VERSION ""

NS_ :

BS_:

BU_: Dummy_PHS EBOOST_OBD_PHS EOCM2cp_IMX6_PHS EOCM2cp_K1_PHS EPSb_PHS EBCM_PHS EPSa_PHS CMMb_PHS CGM3a_PHS CMMa_PHS ADIMb_PHS
VAL_TABLE_ vt_BooleanValues 1 "true" 0 "false" ;
VAL_TABLE_ StgOvrdDetn 3 "Disabled" 2 "False" 1 "True" 0 "Initialization" ;
VAL_TABLE_ PriADSCmdMsgStat 3 "Dual Communication Failure" 2 "Secondary Communication Failed" 1 "Main Communication Failed" 0 "Communication Normal" ;
VAL_TABLE_ PriBrkSysArbStat 7 "Supervisor Override" 6 "Automatic Brake Apply 2" 5 "Automatic Brake Apply 1" 4 "CoPilot Override Request Honored" 3 "Redundant ADS Request Honored" 2 "Main ADS Request Honored" 1 "No Autonomous Request" 0 "Unknown" ;
VAL_TABLE_ AATPCS_PropRngLmtgStat 3 "Request Rate Limited" 2 "Request Value Limited Maximum" 1 "Request Value Limited Minimum" 0 "Request Not Limited" ;
VAL_TABLE_ AATPCS_PropSysStat 6 "Degraded Mode 5" 5 "Degraded Mode 4" 4 "Degraded Mode 3" 3 "Degraded Mode 2" 2 "Degraded Mode 1" 1 "Full Function" 0 "Initialize" ;
VAL_TABLE_ AutoAxlTrqStat 3 "Serial Data Failure" 2 "Data Invalid" 1 "Data Valid" 0 "Unknown" ;
VAL_TABLE_ AutoPropAxlTrqArbStat 3 "Lost Axle Arbitration" 2 "CoPilot Active" 1 "ADS Active" 0 "No ADS data" ;
VAL_TABLE_ StrgCmndMsgStat 3 "Dual Communication Failure" 2 "Redundant Communication Failed" 1 "Primary Communication Failed" 0 "Communication Normal" ;
VAL_TABLE_ StrgCmndMsgUtlzd 1 "Redundant Controller" 0 "Primary Controller" ;
VAL_TABLE_ AutoEstBrkTrqAppStat 2 "Valid" 1 "Reduced Accuracy" 0 "Invalid" ;
VAL_TABLE_ AutoBrkSysDrInfcStat 3 "Failed" 2 "Driver Intervention Not Detected" 1 "Driver Intervention Detected" 0 "Unknown" ;
VAL_TABLE_ ActrBrkFldFlwReqStat 2 "qTarget_EBRmaxPerformance" 1 "qTarget_EBR" 0 "qTarget_Off" ;
VAL_TABLE_ EstWhlBrkPrsStat 3 "Invalid" 2 "Reduced Accuracy" 1 "Valid" 0 "Unknown" ;
VAL_TABLE_ SpltMuCntrl 2 "Split Driver Side High" 1 "Split Driver Side Low" 0 "Inactive" ;
VAL_TABLE_ PriBrkModStat 3 "Failed" 2 "Active" 1 "Available" 0 "Not Available" ;
VAL_TABLE_ ExtBrkReqStat 3 "External Brake Req Active" 2 "External Brake Req Available" 1 "External Brake Req Not Available" 0 "Unknown" ;
VAL_TABLE_ Qualifier 2 "Faulted" 1 "Normal" 0 "Unknown" ;
VAL_TABLE_ iBstStat 7 "iBooster Ready" 6 "iBooster PostRun Reduced" 5 "iBooster Reduced" 2 "iBooster Diagnosis" 1 "iBooster Failure iBoosterOff" 0 "Unknown" 3 "iBooster Autonomous Diagnosis" 4 "iBooster Standalone" ;
VAL_TABLE_ BrkRngLmtgStat 3 "Request Rate Limited" 2 "Req Value Limited Maximum" 1 "Req Value Limited Minimum" 0 "Request Not Limited" ;
VAL_TABLE_ BrkSysStat 6 "Degraded Mode 5" 5 "Degraded Mode 4" 4 "Degraded Mode 3" 3 "Degraded Mode 2" 2 "Degraded Mode 1" 1 "Full Function" 0 "Unknown" ;
VAL_TABLE_ SecBrkModSbSte 5 "Loss of Request" 4 "Full System" 3 "Failed Operational" 2 "Failed Degraded" 1 "Unable to Execute Requests" 0 "Faulted" ;
VAL_TABLE_ SecBrkModCapStat 1 "Active" 0 "Not Active" ;
VAL_TABLE_ EstSrfcMuTyp 3 "Invalid" 2 "Actual Surface Estimate" 1 "Minimum Surface Estimate" 0 "Unknown" ;
VAL_TABLE_ SecBrkModStat 3 "Failed" 2 "Active" 1 "Available" 0 "Not Available" ;
VAL_TABLE_ StgSysOtptStat 3 "Failed" 2 "Single Controller" 1 "Fail Operational" 0 "Unknown" ;
VAL_TABLE_ StgOtptTempLmtgSte 4 "Voltage" 3 "Thermal" 2 "Safety Limit Exceeded" 1 "Normal" 0 "Unknown" 7 "ECU Fault Limited" 6 "Friction Limited" 5 "Lash Exceeded" ;
VAL_TABLE_ AutoStrgCmndStat 6 "Failed" 5 "Emergency Steering Profile" 4 "Temporarily Limited" 3 "Active" 2 "Ready" 1 "Temporarily Inhibited" 0 "Unknown" ;
VAL_TABLE_ EPSWAR_ReqdState 2 "Active" 1 "Inactive" 0 "No Action" ;
VAL_TABLE_ EPBReq 2 "Request Release" 1 "Request Apply" 0 "No Request" ;
VAL_TABLE_ AutoBrkReqType 2 "Standstill Hold Request" 1 "Brake Torque Request" 0 "No Request" 3 "Brake Prefill" ;
VAL_TABLE_ TrqAthdCrsCntrlDsgRsn 17 "CiCRZC_RsmAccelSwTogether" 16 "CiCRZC_PCM_Inhibit" 15 "CiCRZC_OverSpeedTapDown" 14 "CiCRZC_OverSpeed" 13 "CiCRZC_SwOff" 12 "CiCRZC_None" 11 "CiCRZC_LowSpeed" 10 "CiCRZC_IllegalCruzMode" 9 "CiCRZC_HighSpeed" 8 "CiCRZC_HighDecel" 7 "CiCRZC_HighAccel" 6 "CiCRZC_ETC" 5 "CiCRZC_CoastInhibit" 4 "CiCRZC_CoastDisengage" 3 "CiCRZC_Clutch" 2 "CiCRZC_Cancel" 1 "CiCRZC_BrakeBeforeCruz" 0 "CiCRZC_Brake" 74 "CeCRZC_e_HybTorqSigTO" 73 "CeCRZC_e_LCC_SerialDataFault" 72 "CeCRZC_e_ACC_InvalidEngage" 71 "CeCRZC_e_ACC_Off" 70 "CeCRZC_e_ACC_Brake" 69 "CeCRZC_e_ACC_Cancel" 68 "CeCRZC_e_ACC_RedEngPwr" 67 "CiCRZC_VSESFaulted" 66 "CiCRZC_TCSFaulted" 65 "CeCRZC_e_ABS" 64 "CeCRZC_e_VSESOff" 63 "CeCRZC_e_TCSOff" 62 "CeCRZC_e_HybridCruiseDisengage" 61 "CeCRZC_e_HillDescentSerDatInhb" 60 "CeCRZC_e_HillDescentActive" 59 "CeCRZC_e_AutoBrkSerialDataFlt" 58 "CeCRZC_e_AutoBrkFailed" 57 "CeCRZC_e_NotUsed" 56 "CeCRZC_e_SLSW_SwitchOn" 55 "CeCRZC_e_BrkPdlDrvrAplyPressDet" 54 "CeCRZC_e_ManlGrChngWithoutClch" 53 "CeCRZC_e_4WD_LowDisable" 52 "CeCRZC_e_RateLimError" 51 "CeCRZC_e_BrkAplySnsrHomeNotLrnd" 50 "CeCRZC_e_ProcIntegFault" 49 "CeCRZC_e_RunningReset" 48 "CeCRZC_e_PTO" 47 "CeCRZC_e_ACC_CmdSerialDataError" 46 "CeCRZC_e_CntrlSysTypeError" 45 "CeCRZC_e_ACC_AutoBrkFailed" 44 "CeCRZC_e_ACC_Inhibited" 43 "CeCRZC_e_ParkBrakeActive" 42 "CeCRZC_e_BrakeApplyInvalid" 41 "CeCRZC_e_BrakeSerDatError" 40 "CeCRZC_e_TransGrDfltd" 39 "CeCRZC_e_RearAxleLow" 38 "CiCRZC_e_VehStabilityActive" 37 "CiCRZC_e_MetalOvertempActive" 36 "CiCRZC_e_SerialDataFault" 35 "CiCRZC_Sequence" 34 "CiCRZC_DrivenWhlSpdGreater" 33 "CiCRZC_UndrivenWhlSpdGreater" 32 "CiCRZC_HighIgnVoltage" 31 "CiCRZC_AnalogCruzOOR" 30 "CiCRZC_MPH_LimitedFuelEst" 29 "CiCRZC_ManlNeutCruz" 28 "CiCRZC_LowIgnVoltage" 27 "CiCRZC_PedGreaterThanCruz" 26 "CiCRZC_FirstGearDsbl" 25 "CiCRZC_InjectorDsbld" 24 "CiCRZC_Malf" 23 "CiCRZC_EngSpd" 22 "CiCRZC_EngRunTime" 21 "CiCRZC_BadMemory" 20 "CiCRZC_ALDL" 19 "CiCRZC_UnderSchedule" 18 "CiCRZC_TCS" ;
VAL_TABLE_ RTXCorrctnEnbl 1 "Enabled" 0 "Disabled" ;
VAL_TABLE_ PTExPartFltManRegStat 7 "Reserved 3" 6 "Reserved 2" 5 "Reserved 1" 4 "Complete" 3 "In Progress" 2 "Not Allowed" 1 "Allowed" 0 "Cleaning Not Required" ;
VAL_TABLE_ LnchCtrlWhlSlpReq 31 "Unused and Reserved 10" 30 "Unused and Reserved 9" 29 "Unused and Reserved 8" 28 "Unused and Reserved 7" 27 "Unused and Reserved 6" 26 "Unused and Reserved 5" 25 "Unused and Reserved 4" 24 "Unused and Reserved 3" 23 "Unused and Reserved 2" 22 "Unused and Reserved 1" 21 "Fifteen Percent" 20 "Fourteen And A Half Percent" 19 "Fourteen Percent" 18 "Thirteen And A Half Percent" 17 "Thirteen Percent" 16 "Twelve And A Half Percent" 15 "Twelve Percent" 14 "Eleven And a Half Percent" 13 "Eleven Percent" 12 "Ten And A Half Percent" 11 "Ten Percent" 10 "Nine And A Half Percent" 9 "Nine Percent" 8 "Eight And A Half Percent" 7 "Eight Percent" 6 "Seven And A Half Percent" 5 "Seven Percent" 4 "Six And A Half Percent" 3 "Six Percent" 2 "Five And A Half Percent" 1 "Five Percent" 0 "No Action" ;
VAL_TABLE_ LnchCtrlMdReq 3 "Burn Out" 2 "Custom" 1 "Automatic" 0 "No Action" ;
VAL_TABLE_ LnchCtrlEngRPMReq 24 "3100" 23 "3000" 22 "2900" 21 "2800" 20 "2700" 19 "2600" 18 "2500" 17 "2400" 16 "2300" 15 "2200" 14 "2100" 13 "2000" 12 "1900" 11 "1800" 10 "1700" 9 "1600" 8 "1500" 7 "1400" 6 "1300" 5 "1200" 4 "1100" 3 "1000" 2 "900" 1 "800" 0 "No Action" 63 "Unused and Reserved 30" 62 "Unused and Reserved 29" 61 "Unused and Reserved 28" 60 "Unused and Reserved 27" 59 "Unused and Reserved 26" 58 "Unused and Reserved 25" 57 "Unused and Reserved 24" 56 "Unused and Reserved 23" 55 "Unused and Reserved 22" 54 "Unused and Reserved 21" 53 "Unused and Reserved 20" 52 "Unused and Reserved 19" 51 "Unused and Reserved 18" 50 "Unused and Reserved 17" 49 "Unused and Reserved 16" 48 "Unused and Reserved 15" 47 "Unused and Reserved 14" 46 "Unused and Reserved 13" 45 "Unused and Reserved 12" 44 "Unused and Reserved 11" 43 "Unused and Reserved 10" 42 "Unused and Reserved 9" 41 "Unused and Reserved 8" 40 "Unused and Reserved 7" 39 "Unused and Reserved 6" 38 "Unused and Reserved 5" 37 "Unused and Reserved 4" 36 "Unused and Reserved 3" 35 "Unused and Reserved 2" 34 "Unused and Reserved 1" 33 "4000" 32 "3900" 31 "3800" 30 "3700" 29 "3600" 28 "3500" 27 "3400" 26 "3300" 25 "3200" ;
VAL_TABLE_ TARS_TransActRng 15 "Unused and Reserved2" 14 "Unused and Reserved1" 13 "Fourth Drive Position" 12 "Between Third and Fourth Drive position" 11 "Third Drive Position" 10 "Between Second and Third Drive position" 9 "Second Drive Position" 8 "Between First and Second Drive position" 7 "First Drive Position" 6 "Between Neutral and First Drive position" 5 "Neutral Position" 4 "Between Reverse and Neutral" 3 "Reverse Position" 2 "Between Park and Reverse" 1 "Park Position" 0 "Unknown Position" ;
VAL_TABLE_ ChrgSysAudblIndRq 7 "Unused and Reserved3" 6 "Unused and Reserved2" 5 "Unused and Reserved1" 4 "Sequence 4" 3 "Sequence 3" 2 "Sequence 2" 1 "Sequence 1" 0 "Inactive" ;
VAL_TABLE_ EASSI_StrtTyp 7 "Type G" 6 "Type F" 5 "Type E" 4 "Type D" 3 "Type C" 2 "Type B" 1 "Type A" 0 "No Start" ;
VAL_TABLE_ EASSI_StrtStpSt 3 "Engine Stopping" 2 "Engine Starting" 1 "Engine Running" 0 "Engine Off" ;
VAL_TABLE_ TEPI_TrnsEngdPrFlwSt 7 "Unused and Reserved4" 6 "Unused and Reserved3" 5 "Unused and Reserved2" 4 "Unused and Reserved1" 3 "Reverse Engaged" 2 "Drive Engaged" 1 "No Powerflow" 0 "Unavailable " ;
VAL_TABLE_ ESBR_AutoBrkgRqTyp 3 "Unused and Reserved" 2 "Hold Deny Driver Release" 1 "Hold Allow Driver Release" 0 "Release" ;
VAL_TABLE_ ESBR_AutoBrkgRqd 1 "Braking Requested" 0 "Braking Not Requested " ;
VAL_TABLE_ EngDetPndTrnCsRngShf 3 "Shift Out of Neutral Range" 2 "Shift Out of Low Range" 1 "Shift Out of High Range" 0 "None" ;
VAL_TABLE_ AVHSwtchStats 1 "Active" 0 "Not Active" ;
VAL_TABLE_ BCS2ERDTC_SysDesigntr 15 "U3-Network Codes Reserved" 14 "U2-Network Codes Reserved" 13 "U1-Network Codes MFG Controlled" 12 "U0-Network Codes SAE Controlled" 11 "B3-Body Codes Reserved" 10 "B2-Body Codes Reserved" 9 "B1-Body Codes MFG Controlled" 8 "B0-Body Codes SAE Controlled" 7 "C3-Chassis Codes Reserved" 6 "C2-Chassis Codes Reserved" 5 "C1-Chassis Codes MFG Controlled" 4 "C0-Chassis Codes SAE Controlled" 3 "P3-Powertrain Codes Reserved" 2 "P2-Powertrain Codes Reserved" 1 "P1-Powertrain Codes MFG Controlled" 0 "P0-Powertrain Codes SAE Controlled" ;
VAL_TABLE_ ExtHlStrAssCsStRq 2 "Standard Hold" 1 "Extended Hold" 0 "No Action" ;
VAL_TABLE_ PrtdEPBSwStat 3 "Active" 2 "Apply" 1 "Release" 0 "Not Active" ;
VAL_TABLE_ EBrkAstStat 7 "Faulted" 6 "Temporarily Failed" 5 "Reduced" 4 "Standalone" 3 "PostRun Reduced" 2 "Normal" 1 "Initializing" 0 "Not Initialized" ;
VAL_TABLE_ AdptCruzCtrlStg 7 "Performance Mode 7" 6 "Performance Mode 6" 5 "Performance Mode 5" 4 "Performance Mode 4" 3 "Performance Mode 3" 2 "Performance Mode 2" 1 "Performance Mode 1" 0 "No Action" ;
VAL_TABLE_ SpdLmtrSttngTypAct 3 "Reserved" 2 "Auto" 1 "Manual" 0 "Off" ;
VAL_TABLE_ SetSpdLmtRchd 3 "Reserved" 2 "Low limit reached" 1 "High limit reached" 0 "No limit reached" ;
VAL_TABLE_ CrpCstCrvCmd 7 "Creep Coast Curve 7" 6 "Creep Coast Curve 6" 5 "Creep Coast Curve 5" 4 "Creep Coast Curve 4" 3 "Creep Coast Curve 3" 2 "Creep Coast Curve 2" 1 "Creep Coast Curve 1" 0 "Creep Coast Curve 0" ;
VAL_TABLE_ ClmtCtrlHtrEngRunRq 1 "Engine Run Requested" 0 "No Action" ;
VAL_TABLE_ StgSysPerfMdRq 7 "Performance Mode 7" 6 "Performance Mode 6" 5 "Performance Mode 5" 4 "Performance Mode 4" 3 "Performance Mode 3" 2 "Performance Mode 2" 1 "Performance Mode 1" 0 "No Action" ;
VAL_TABLE_ SndEnhcmtPerfMdRq 7 "Performance Mode 7" 6 "Performance Mode 6" 5 "Performance Mode 5" 4 "Performance Mode 4" 3 "Performance Mode 3" 2 "Performance Mode 2" 1 "Performance Mode 1" 0 "No Action" ;
VAL_TABLE_ RideCntrlPerfMdRq 7 "Performance Mode 7" 6 "Performance Mode 6" 5 "Performance Mode 5" 4 "Performance Mode 4" 3 "Performance Mode 3" 2 "Performance Mode 2" 1 "Performance Mode 1" 0 "No Action" ;
VAL_TABLE_ ExhstPerfMdRq 7 "Performance Mode 7" 6 "Performance Mode 6" 5 "Performance Mode 5" 4 "Performance Mode 4" 3 "Performance Mode 3" 2 "Performance Mode 2" 1 "Performance Mode 1" 0 "No Action" ;
VAL_TABLE_ DsplyPerfMdRq 7 "Performance Mode 7" 6 "Performance Mode 6" 5 "Performance Mode 5" 4 "Performance Mode 4" 3 "Performance Mode 3" 2 "Performance Mode 2" 1 "Performance Mode 1" 0 "No Action" ;
VAL_TABLE_ DiffPerfMdRq 7 "Performance Mode 7" 6 "Performance Mode 6" 5 "Performance Mode 5" 4 "Performance Mode 4" 3 "Performance Mode 3" 2 "Performance Mode 2" 1 "Performance Mode 1" 0 "No Action" ;
VAL_TABLE_ AWDPerfMdRq 7 "Performance Mode 7" 6 "Performance Mode 6" 5 "Performance Mode 5" 4 "Performance Mode 4" 3 "Performance Mode 3" 2 "Performance Mode 2" 1 "Performance Mode 1" 0 "No Action" ;
VAL_TABLE_ DrvSelMd8Stat 1 "Active" 0 "Inactive" ;
VAL_TABLE_ DrvSelMd7Stat 1 "Active" 0 "Inactive" ;
VAL_TABLE_ DrvSelMd6Stat 1 "Active" 0 "Inactive" ;
VAL_TABLE_ DrvSelMd5Stat 1 "Active" 0 "Inactive" ;
VAL_TABLE_ DrvSelMd4Stat 1 "Active" 0 "Inactive" ;
VAL_TABLE_ DrvSelMd3Stat 1 "Active" 0 "Inactive" ;
VAL_TABLE_ DrvSelMd2Stat 1 "Active" 0 "Inactive" ;
VAL_TABLE_ WhlRotDrctnlStatus 0 "Unknown" 1 "Forward" 2 "Reverse" 3 "Not Supported" 4 "Failed" 5 "Reserved 1" 6 "Reserved 2" 7 "Reserved 3" ;
VAL_TABLE_ DrvSelMd1Stat 1 "Active" 0 "Inactive" ;
VAL_TABLE_ EngCntrlUtldTrnCsRng 3 "Neutral" 2 "Unused and Reserved" 1 "Low" 0 "High" ;
VAL_TABLE_ CSTATRS_ReqStat 6 "Control System Failure Permanent" 5 "Control System Failure Temporary" 4 "Serial Data Failure Permanent" 3 "Serial Data Failure Temporary" 2 "Lost Arbitration" 1 "Request Honored" 0 "No Request" ;
VAL_TABLE_ CSTATRS_LmtgStat 3 "Rate and Value Limited" 2 "Value Limited" 1 "Rate Limited" 0 "Not Limited" ;
VAL_TABLE_ EngCntrlDtrmdTrfCRng 3 "Neutral" 2 "Unused and Reserved" 1 "Low" 0 "High" ;
VAL_TABLE_ ElecPrkBrkAvailStat 7 "Unused and Reserved 3" 6 "Unused and Reserved 2" 5 "Unused and Reserved 1" 4 "Unavailable, Failed other" 3 "Unavailable, Failed Released" 2 "Unavailable, Failed Applied" 1 "Available, Not Failed" 0 "Unavailable, Not Failed" ;
VAL_TABLE_ ElecPrkBrkApplStat 3 "Park Brake Application in Progress" 2 "Park brake Released" 1 "Park Brake Applied" 0 "Unknown" ;
VAL_TABLE_ CSPATR_TrqIntrvnTyp 3 "Minimum and Maximum Limit" 2 "Minimum Limit" 1 "Maximum Limit" 0 "No Intervention" ;
VAL_TABLE_ CSPATR_TrqRqTyp 0 "Absolute Torque Request" ;
VAL_TABLE_ ChsSysAxlTqRqRspTyp 4 "Braking Torque Request" 3 "Automatic Actuator Selection" 2 "Maximum Range Request" 1 "Pleasability Limited Request" 0 "Inactive" ;
VAL_TABLE_ PMVSS_Trans 7 "Visualization Type 7" 6 "Visualization Type 6" 5 "Visualization Type 5" 4 "Visualization Type 4" 3 "Visualization Type 3" 2 "Visualization Type 2" 1 "Visualization Type 1" 0 "No Action" ;
VAL_TABLE_ PMVSS_Susp 7 "Visualization Type 7" 6 "Visualization Type 6" 5 "Visualization Type 5" 4 "Visualization Type 4" 3 "Visualization Type 3" 2 "Visualization Type 2" 1 "Visualization Type 1" 0 "No Action" ;
VAL_TABLE_ PMVSS_Strng 7 "Visualization Type 7" 6 "Visualization Type 6" 5 "Visualization Type 5" 4 "Visualization Type 4" 3 "Visualization Type 3" 2 "Visualization Type 2" 1 "Visualization Type 1" 0 "No Action" ;
VAL_TABLE_ PMVSS_Snd 7 "Visualization Type 7" 6 "Visualization Type 6" 5 "Visualization Type 5" 4 "Visualization Type 4" 3 "Visualization Type 3" 2 "Visualization Type 2" 1 "Visualization Type 1" 0 "No Action" ;
VAL_TABLE_ PMVSS_PsngrSeat 7 "Visualization Type 7" 6 "Visualization Type 6" 5 "Visualization Type 5" 4 "Visualization Type 4" 3 "Visualization Type 3" 2 "Visualization Type 2" 1 "Visualization Type 1" 0 "No Action" ;
VAL_TABLE_ PMVSS_Exhst 7 "Visualization Type 7" 6 "Visualization Type 6" 5 "Visualization Type 5" 4 "Visualization Type 4" 3 "Visualization Type 3" 2 "Visualization Type 2" 1 "Visualization Type 1" 0 "No Action" ;
VAL_TABLE_ PMVSS_Eng 7 "Visualization Type 7" 6 "Visualization Type 6" 5 "Visualization Type 5" 4 "Visualization Type 4" 3 "Visualization Type 3" 2 "Visualization Type 2" 1 "Visualization Type 1" 0 "No Action" ;
VAL_TABLE_ PMVSS_DrvrSeat 7 "Visualization Type 7" 6 "Visualization Type 6" 5 "Visualization Type 5" 4 "Visualization Type 4" 3 "Visualization Type 3" 2 "Visualization Type 2" 1 "Visualization Type 1" 0 "No Action" ;
VAL_TABLE_ PMVSS_Drvln 7 "Visualization Type 7" 6 "Visualization Type 6" 5 "Visualization Type 5" 4 "Visualization Type 4" 3 "Visualization Type 3" 2 "Visualization Type 2" 1 "Visualization Type 1" 0 "No Action" ;
VAL_TABLE_ PMVSS_Disps 7 "Visualization Type 7" 6 "Visualization Type 6" 5 "Visualization Type 5" 4 "Visualization Type 4" 3 "Visualization Type 3" 2 "Visualization Type 2" 1 "Visualization Type 1" 0 "No Action" ;
VAL_TABLE_ PMVSS_AdptCrsCnt 7 "Visualization Type 7" 6 "Visualization Type 6" 5 "Visualization Type 5" 4 "Visualization Type 4" 3 "Visualization Type 3" 2 "Visualization Type 2" 1 "Visualization Type 1" 0 "No Action" ;
VAL_TABLE_ PsngStPerfMdCsStReq 7 "Auto" 6 "Performance Mode 6" 5 "Performance Mode 5" 4 "Performance Mode 4" 3 "Performance Mode 3" 2 "Performance Mode 2" 1 "Performance Mode 1" 0 "No Action" ;
VAL_TABLE_ DrvrStPerfMdCsStReq 7 "Auto" 6 "Performance Mode 6" 5 "Performance Mode 5" 4 "Performance Mode 4" 3 "Performance Mode 3" 2 "Performance Mode 2" 1 "Performance Mode 1" 0 "No Action" ;
VAL_TABLE_ DrvStyPerfMdCsStReq 7 "Performance Mode 7" 6 "Performance Mode 6" 5 "Performance Mode 5" 4 "Performance Mode 4" 3 "Performance Mode 3" 2 "Performance Mode 2" 1 "Performance Mode 1" 0 "No Action" ;
VAL_TABLE_ ACCPerfMdCsStReq 7 "Auto" 6 "Performance Mode 6" 5 "Performance Mode 5" 4 "Performance Mode 4" 3 "Performance Mode 3" 2 "Performance Mode 2" 1 "Performance Mode 1" 0 "No Action" ;
VAL_TABLE_ PltfrmEngSpdCmmndSt 3 "Request Denied" 2 "Lost Arbitration" 1 "Request Honored" 0 "No Request" ;
VAL_TABLE_ DTCStatus 0 "Not Supported" 1 "Critically Disabled" 2 "No Status to Report" 3 "Diagnostic Passed" 4 "Diagnostic Failed" ;
VAL_TABLE_ WhlSlpSt 3 "Slip Detection Fault" 2 "Positive Slip Detected" 1 "Negative Slip Detected" 0 "No Slip Detected" ;
VAL_TABLE_ ACCmEngRunReq 1 "Engine Run Requested" 0 "No Action" ;
VAL_TABLE_ EngCntrlRunCrnkTrmSt 1 "Active" 0 "Inactive" ;
VAL_TABLE_ ACCATCS_RqStat 4 "Request Suspended Till Driver Input" 3 "Request Denied" 2 "Lost Arbitration" 1 "Request Honored" 0 "No Request" ;
VAL_TABLE_ ACCATCS_LmtgStat 3 "Request Rate Limited" 2 "Request Value Limited Maximum" 1 "Request Value Limited Minimum" 0 "Request Not Limited" ;
VAL_TABLE_ EPBSysWrnIndReq 3 "Flash Rate #2 Indication" 2 "Flash Rate #1 Indication" 1 "Continuous Indication" 0 "No Indication" ;
VAL_TABLE_ SecAxlOpeMod 3 "Active All Wheel Drive (High)" 2 "4 Wheel Drive Low Locked" 1 "4 Wheel Drive High Locked" 0 "2 Wheel Drive High" 15 "Neutral" 14 "Unknown" 7 "2 Wheel Drive Low" 6 "Active All Wheel Drive (Low)" 5 "4 Wheel Drive Low Open" 4 "4 Wheel Drive High Open" ;
VAL_TABLE_ EPBSwSta 3 "Active" 2 "Apply" 1 "Release" 0 "NotActive" ;
VAL_TABLE_ EPBSta 2 "Fault" 1 "Applied" 0 "Released" ;
VAL_TABLE_ TransTUDMdStat 2 "Electronic Range Select Active" 1 "Driver Shift Control Active" 0 "No Activation" ;
VAL_TABLE_ TrnShftPtrnActStat 6 "PT Protection Pattern Active" 5 "PT Non-Protection Pattern Active" 4 "Shift Pattern 4 Active" 3 "Shift Pattern 3 Active" 2 "Shift Pattern 2 Active" 1 "Shift Pattern 1 Active" 0 "Default Shift Pattern Active" ;
VAL_TABLE_ EPBSysAudWarnReq 2 "Warning #2" 1 "Warning #1" 0 "Off" ;
VAL_TABLE_ NotEventSta 2 "Pretensioner Deployment Event" 1 "Near Deployment Event" 0 "No Event" 3 "Airbag Deployment Event" ;
VAL_TABLE_ VehMovSta 4 "Invalid" 3 "Reverse" 2 "Forward" 1 "Neutral" 0 "Parked" ;
VAL_TABLE_ TrnsEngdState 3 "Operating State Not Reached" 2 "Transmission Engaged in Reverse" 1 "Transmission Engaged in Forward" 0 "Transmission Not Engaged" ;
VAL_TABLE_ EPBSysDspMsgReq 7 "Message #7" 6 "Message #6" 5 "Message #5" 4 "Message #4" 3 "Message #3" 2 "Message #2" 1 "Message #1" 0 "Off" ;
VAL_TABLE_ OtsdAmbtLtLvlStat 2 "Day" 1 "Night" 0 "Unknown" ;
VAL_TABLE_ RdSpdCatType 3 "all speed categories 0 - 50 km/h" 2 "all speed categories 51-80 km/h" 1 "all speed categories 81-130 km/h" 0 "all speed categories > 130 km/h" ;
VAL_TABLE_ LnCat 3 "Four Or More Lanes" 2 "Two Or Three Lanes" 1 "One lane" 0 "no info available" ;
VAL_TABLE_ FncRdClass 7 "COLLECTOR" 6 "ALLEY" 5 "ARTERIAL" 4 "HIGHWAY" 3 "PED-MALL" 2 "FREEWAY" 1 "SFREEWAY" 0 "LOCAL (Residential Road)" ;
VAL_TABLE_ CustomizationSettingRequest 4 "Performance Mode 4" 3 "Performance Mode 3" 2 "Performance Mode 2" 1 "Performance Mode 1" 0 "No Action" 7 "Auto" 6 "Performance Mode 6" 5 "Performance Mode 5" ;
VAL_TABLE_ RstrCustFctrDef 1 "Restore Defaults" 0 "No Action" ;
VAL_TABLE_ CustomizationCurrentSettingValue 7 "Auto" 6 "Performance Mode 6" 5 "Performance Mode 5" 4 "Performance Mode 4" 3 "Performance Mode 3" 0 "No Action" 1 "Performance Mode 1" 2 "Performance Mode 2" ;
VAL_TABLE_ EPBSysStatIndReq 3 "Flash Rate 2 Indication" 2 "Flash Rate 1 Indication" 1 "Continuous Indication" 0 "No Indication" ;
VAL_TABLE_ AllNodesVNA 1 "Activate Virtual Network" 0 "No Activation" ;
VAL_TABLE_ ClntCircPmpRq 1 "On" 0 "Off" ;
VAL_TABLE_ ImoIdSt 1 "Info valid" 0 "No info" ;
VAL_TABLE_ LrnEnvIdSt 1 "Info_valid" 0 "No_info" ;
VAL_TABLE_ EnvIdRspSt4 3 "Environment_id_request" 2 "Incorrect_immo_id" 1 "Info_valid" 0 "No_info" ;
VAL_TABLE_ VDAvailability 1 "VirtualDeviceAvailable" 0 "VirtualDeviceUnavailable" ;
VAL_TABLE_ MaskStates 1 "Use Data" 0 "Don't Use Data" ;
VAL_TABLE_ CldrMth 12 "December" 11 "November" 10 "October" 9 "September" 8 "August" 7 "July" 6 "June" 5 "May" 4 "April" 3 "March" 2 "February" 1 "January" 0 "Unknown" ;
VAL_TABLE_ TrnSwAct 2 "Right" 1 "Left" 0 "No Activation" ;
VAL_TABLE_ HdlmpBmSelectStat 2 "High Beams" 1 "Low Beams" 0 "Unknown" ;
VAL_TABLE_ VehStabEnhmntMd 2 "Competitive" 1 "Normal" 0 "Off" ;
VAL_TABLE_ VehStabEnhmntStat 4 "Not Ready" 3 "Warming Up" 2 "Fault" 1 "Active" 0 "Inactive" ;
VAL_TABLE_ TCSysOpMd 2 "Off Road" 1 "Normal" 0 "Off" ;
VAL_TABLE_ TCSysOpStat 2 "Fault" 1 "Active" 0 "Inactive" ;
VAL_TABLE_ HillDscntCntlSysStat 4 "Temporarily Inhibited" 3 "Failed" 2 "Active" 1 "Enabled" 0 "Normal" ;
VAL_TABLE_ EnrgMgtLdShdRq 4 "Load Shed Level 4" 3 "Load Shed Level 3" 2 "Load Shed Level 2" 1 "Load Shed Level 1" 0 "No Load Shedding" ;
VAL_TABLE_ DrId 7 "Unknown" 6 "Driver #7" 5 "Driver #6" 4 "Driver #5" 3 "Driver #4" 2 "Driver #3" 1 "Driver #2" 0 "Driver #1" ;
VAL_TABLE_ TireRRPrsStat 5 "High" 4 "Low - Extended Mobility" 3 "Low" 2 "Low - Service Now" 1 "Nominal" 0 "Unknown" ;
VAL_TABLE_ TireRFPrsStat 5 "High" 4 "Low - Extended Mobility" 3 "Low" 2 "Low - Service Now" 1 "Nominal" 0 "Unknown" ;
VAL_TABLE_ TireLRPrsStat 5 "High" 4 "Low - Extended Mobility" 3 "Low" 2 "Low - Service Now" 1 "Nominal" 0 "Unknown" ;
VAL_TABLE_ TireLFPrsStat 5 "High" 4 "Low - Extended Mobility" 3 "Low" 2 "Low - Service Now" 1 "Nominal" 0 "Unknown" ;
VAL_TABLE_ DTCI_DTCFaultType 3 "Type C" 2 "Type B" 1 "Type A" 0 "Not Supported" ;
VAL_TABLE_ DistRollCntAvgDrvnSrc 1 "Wheel Speed" 0 "Transmission Output Speed" ;
VAL_TABLE_ VehSpdAvgDrvnSrc 1 "Wheel Speed" 0 "Transmission Output Speed" ;
VAL_TABLE_ TrnsSftMdStat 3 "Automatic Grade Braking Mode" 2 "Lift-Foot Cornering Mode" 1 "Performance Mode" 0 "No Override Mode" ;
VAL_TABLE_ TrnsRngInhbtStat 4 "Diagnostic Inhibit Active" 3 "Driveline Not Engaged" 2 "Transmission Range Re-Selection Req" 1 "Transmission Inhibit Active" 0 "No Range Inhibit Active" ;
VAL_TABLE_ DrvtShftCntrlTrgtGear 10 "Tenth Gear" 9 "Ninth Gear" 8 "Eighth Gear" 7 "Seventh Gear" 6 "Sixth Gear" 5 "Fifth Gear" 4 "Fourth Gear" 3 "Third Gear" 2 "Second Gear" 1 "First Gear" 0 "Not Supported" ;
VAL_TABLE_ StrWhlAngSenCalStat 2 "Calibrated" 1 "Estimated" 0 "Unknown" ;
VAL_TABLE_ EngTrqRdFlrSt 4 "Torq Reduction Communication Failed" 3 "Torque Reduction Limited" 2 "Torque Reduction Permanently Failed" 1 "Torque Reduction Temporarily Failed" 0 "Torque Reduction OK" ;
VAL_TABLE_ EngCylDeactMd 3 "Reactivation In Progress" 2 "Half of Total Cylinders Active" 1 "Deactivation In Progress" 0 "All Cylinders Active" ;
VAL_TABLE_ PltfrmEngSpdCmdInhtRq 0 "Allow Platform Engine Speed Control" 1 "Inhibit Platform Eng. Speed Control" ;
VAL_TABLE_ PT_BrkPedDscrtInpStat 1 "Brake Applied" 0 "Brake Not Applied" ;
VAL_TABLE_ EngSpdStat 3 "Invalid" 1 "Degraded Operation" 0 "Normal Operation" ;
VAL_TABLE_ ACCompSysVDM 1 "Use Data" 0 "Don't Use Data" ;
VAL_TABLE_ DispMeasSys 1 "English" 0 "Metric" ;
VAL_TABLE_ ACCompModReq 3 "No Action" 2 "Engage" 1 "Disengage" 0 "Disengage Immediately" ;
VAL_TABLE_ TrnsShftLvrPos 13 "Forward Range J" 12 "Froward Range I" 15 "Lever Position Unknown" 11 "Forward Range H" 10 "Forward Range G" 9 "Forward Range F" 8 "Forward Range E" 7 "Forward Range D" 6 "Forward Range C" 5 "Forward Range B" 4 "Forward Range A" 3 "Neutral Range" 2 "Reverse Range" 1 "Park Range" 0 "Between Ranges" ;
VAL_TABLE_ TrnsTrqCnvCltCmndMd 7 "Not Supported" 3 "Locked" 2 "Controlled Slip" 1 "Transitioning" 0 "Unlocked" ;
VAL_TABLE_ VD_CoPilotSysFltStat 5 "Copilot System Failure" 4 "Partial Function Fault Detected" 3 "Redundancy Fault Detected" 2 "Environmental Interference" 1 "Operational" 0 "Unknown" ;
VAL_TABLE_ RedHVCntctrShdwnReq 4 "Normal Shutdown" 3 "Emergency Crash Shutdown" 2 "Controlled Shutdown" 1 "Emergency Shutdown" 0 "None" ;
VAL_TABLE_ SecVehSpdSrcDrvnRed 3 "Transmission Output Speed" 2 "Averaged Driven Wheel Speed" 1 "Motor RPM" 0 " No Source Available" ;
VAL_TABLE_ EPBStat 3 "Failed" 2 "Reduced Performance" 1 "Normal" 0 "Unknown" ;
VAL_TABLE_ EPBApplSt 3 "Applied" 2 "Transitioning" 1 "Released" 0 "Unknown" ;
VAL_TABLE_ BrkFldLvlIndStat 1 "Failed" 0 "Normal" ;
VAL_TABLE_ SystemStatus 3 "Failed" 2 "Active" 1 "Available" 0 "Unknown" ;
VAL_TABLE_ AutoPwrSelfTestStat 3 "Complete" 2 "Active" 1 "Pending" 0 "Inactive" ;
VAL_TABLE_ AutoPwrSOH 3 "Faulted" 2 "Supervision Mode" 1 "Inactive" 0 "Indeterminate" ;
VAL_TABLE_ AutoPwrDrtgLvl 5 " Derating Level 5" 4 " Derating Level 4" 3 " Derating Level 3" 2 " Derating Level 2" 1 " Derating Level 1" 0 " Derating Level 0" ;
VAL_TABLE_ StrgAngTrqBsdEstSrfcMuConf 2 "Indeterminate" 1 "Use Data" 0 "Do Not Use Data" ;
VAL_TABLE_ VehMdMngrSt 0 "Unknown" 1 "Manual" 2 "Autonomous Supervised" 3 "Supervisor Override" 4 "Autonomous Unsupervised" 5 "Failed" ;
VAL_TABLE_ AutoTransComndGear 9 "Ninth Gear" 15 "Park Gear" 14 "Reverse Gear" 13 "Neutral Gear" 12 "CVT Forward Gear" 11 "Unused and Reserved" 10 "Tenth Gear" 8 "Eighth Gear" 7 "Seventh Gear" 6 "Sixth Gear" 5 "Fifth Gear" 4 "Fourth Gear" 3 "Third Gear" 2 "Second Gear" 1 "First Gear" 0 "Not Supported" ;
VAL_TABLE_ AutoTransGrSftDirect 2 "Downshift in Progress" 1 "Upshift in Progress" 0 "No Shift in Progress" ;
VAL_TABLE_ TransEstGear 9 "Ninth Gear" 15 "Park Gear" 14 "Reverse Gear" 13 "Neutral Gear" 12 "CVT Forward Gear" 11 "Unused and Reserved" 10 "Tenth Gear" 8 "Eighth Gear" 7 "Seventh Gear" 6 "Sixth Gear" 5 "Fifth Gear" 4 "Fourth Gear" 3 "Third Gear" 2 "Second Gear" 1 "First Gear" 0 "Not Supported" ;
VAL_TABLE_ PTORmStMsEngStRq 1 "PTO Remote Start Requested" 0 "PTO Remote Start Not Requested" ;
VAL_TABLE_ RmVehStrRq 1 "Remote Start Requested" 0 "Remote Start Not Requested" ;
VAL_TABLE_ PF_MinIdlBstLvlReq 3 "Boost Level 3" 2 "Boost Level 2" 1 "Boost Level 1" 0 "No Boost Requested" ;
VAL_TABLE_ ThrtlPrgrsnReq 2 "Map C" 1 "Map B" 0 "Map A" ;
VAL_TABLE_ PMMAccTrmSt 1 "Active" 0 "Inactive" ;
VAL_TABLE_ PMMRunCrkTrmSt 1 "Active" 0 "Inactive" ;
VAL_TABLE_ SysBkUpPwrMd 3 "Crank Request" 2 "Run" 1 "Accessory" 0 "Off" ;
VAL_TABLE_ SysPwrMd 3 "Crank Request" 2 "Run" 1 "Accessory" 0 "Off" ;
VAL_TABLE_ ImmblzrPreRelPswdStat 1 "Information Valid" 0 "No Information" ;
VAL_TABLE_ SprTireSt 2 "Spare Detected" 1 "No Spare Detected" 0 "Undetermined" ;
VAL_TABLE_ BSTGRReqdGear 10 "Tenth Gear" 9 "Ninth Gear" 8 "Eighth Gear" 7 "Seventh Gear" 6 "Sixth Gear" 5 "Fifth Gear" 4 "Fourth Gear" 3 "Third Gear" 2 "Second Gear" 1 "First Gear" 0 "No Action" ;
VAL_TABLE_ BSTGRReqType 1 "Max Gear Request" 0 "No Action" 3 "Hold Gear" 2 "Min Gear Request" ;
VAL_TABLE_ VhDynCntlSysSt 7 "Driver Disabled" 6 "Enhanced Operation" 5 "Calibrating" 4 "Warming Up" 3 "Permanently Failed" 2 "Temporarily Inhibited" 1 "Reduced Function" 0 "Normal Operation" ;
VAL_TABLE_ TracCntrlSysDrIntnt 1 "Enabled" 0 "Disabled" ;
VAL_TABLE_ ValidityStates 1 "Invalid" 0 "Valid" ;
VAL_TABLE_ MainLghtSw 3 "HEADLAMP" 2 "PARKLAMP" 1 "OFF" 0 "AUTO" ;

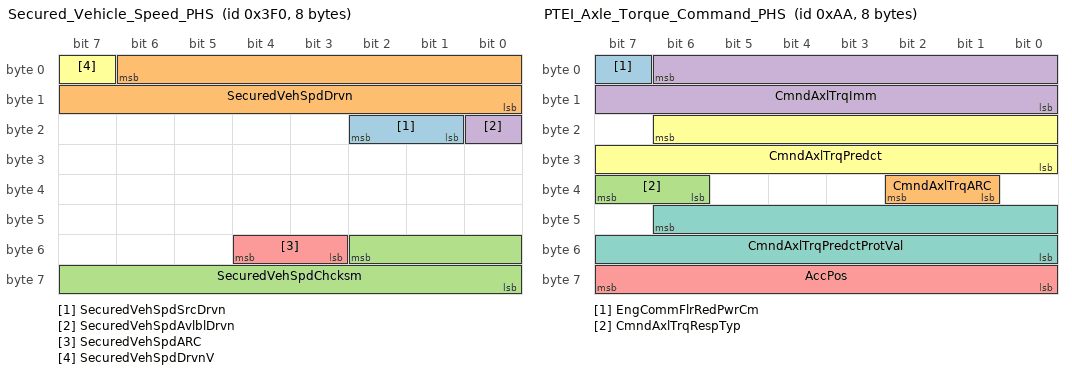
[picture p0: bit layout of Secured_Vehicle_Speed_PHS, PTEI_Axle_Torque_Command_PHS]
BO_ 1008 Secured_Vehicle_Speed_PHS: 8 CGM3a_PHS
 SG_ SecuredVehSpdSrcDrvn : 18|2@0+ (1,0) [0|3] "km/h"  EBOOST_OBD_PHS,EPSb_PHS
 SG_ SecuredVehSpdDrvn : 6|15@0+ (0.015625,0) [0|511.984375] "km/h"  EBOOST_OBD_PHS,EPSb_PHS
 SG_ SecuredVehSpdChcksm : 50|11@0+ (1,0) [0|2047] ""  EBOOST_OBD_PHS,EPSb_PHS
 SG_ SecuredVehSpdAvlblDrvn : 16|1@0+ (1,0) [0|1] ""  EBOOST_OBD_PHS,EPSb_PHS
 SG_ SecuredVehSpdARC : 52|2@0+ (1,0) [0|3] ""  EPSb_PHS,EBOOST_OBD_PHS
 SG_ SecuredVehSpdDrvnV : 7|1@0+ (1,0) [0|1] ""  EPSb_PHS,EBOOST_OBD_PHS

BO_ 647 PTEI_TransferCaseSupplementalPHS: 5 CGM3a_PHS
 SG_ CrnksftTqModRspMxCapV : 28|1@0+ (1,0) [0|1] "" Vector__XXX
 SG_ CrnksftTqModRspMxCap : 27|12@0+ (0.5,-848) [-848|1199.5] "Nm" Vector__XXX
 SG_ EngDetPndTrnCsRngShfV : 21|1@0+ (1,0) [0|1] "" Vector__XXX
 SG_ EngDetPndTrnCsRngShf : 20|2@0+ (1,0) [0|3] "" Vector__XXX
 SG_ CrpCstCrvCmd : 18|3@0+ (1,0) [0|7] "" Vector__XXX
 SG_ DrvMntnMdCmnd : 11|1@0+ (1,0) [0|1] "" Vector__XXX
 SG_ DrvHldMdCmnd : 12|1@0+ (1,0) [0|1] "" Vector__XXX
 SG_ DrPTGrdBrkDsbMdCmd : 22|1@0+ (1,0) [0|1] "" Vector__XXX
 SG_ DrvWntrMdCmd : 13|1@0+ (1,0) [0|1] "" Vector__XXX
 SG_ DrvTwHaulMdCmd : 14|1@0+ (1,0) [0|1] "" Vector__XXX
 SG_ DrvSprtMdCmd : 15|1@0+ (1,0) [0|1] "" Vector__XXX
 SG_ DrvEconMdCmd : 5|1@0+ (1,0) [0|1] "" Vector__XXX
 SG_ EngCntrlDtrmdTrfCRngV : 10|1@0+ (1,0) [0|1] "" Vector__XXX
 SG_ EngCntrlDtrmdTrfCRng : 9|2@0+ (1,0) [0|3] "" Vector__XXX
 SG_ EngCtrlUtldTrnCRgPVal : 1|2@0+ (1,0) [0|3] ""  EBCM_PHS
 SG_ EngCntrlUtldTrnCsRng : 3|2@0+ (1,0) [0|3] ""  EBCM_PHS
 SG_ EngCntrlUtldTrnCsRgIn : 4|1@0+ (1,0) [0|1] ""  EBCM_PHS
 SG_ EngCtrlUtldTrnCRgARC : 7|2@0+ (1,0) [0|3] ""  EBCM_PHS

BO_ 170 PTEI_Axle_Torque_Command_PHS: 8 CGM3a_PHS
 SG_ EngCommFlrRedPwrCm : 7|1@0+ (1,0) [0|1] "" Vector__XXX
 SG_ CmndAxlTrqARC : 34|2@0+ (1,0) [0|3] ""  EBCM_PHS
 SG_ CmndAxlTrqRespTyp : 39|2@0+ (1,0) [0|3] "" Vector__XXX
 SG_ CmndAxlTrqImm : 6|15@0+ (2,-22534) [-22534|43000] "Nm" Vector__XXX
 SG_ AccPos : 63|8@0+ (0.392157,0) [0|100.000035] "%" Vector__XXX
 SG_ CmndAxlTrqPredct : 22|15@0+ (2,-22534) [-22534|43000] "Nm"  EBCM_PHS
 SG_ CmndAxlTrqPredctProtVal : 46|15@0+ (1,0) [0|32767] ""  EBCM_PHS

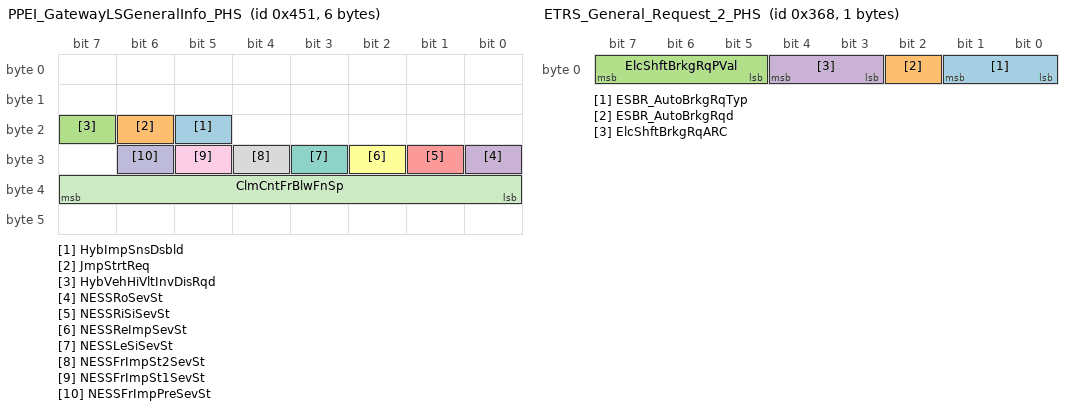
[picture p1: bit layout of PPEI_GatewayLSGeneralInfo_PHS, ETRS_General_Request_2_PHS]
BO_ 1105 PPEI_GatewayLSGeneralInfo_PHS: 6 CGM3a_PHS
 SG_ HybImpSnsDsbld : 21|1@0+ (1,0) [0|1] "" Vector__XXX
 SG_ JmpStrtReq : 22|1@0+ (1,0) [0|1] "" Vector__XXX
 SG_ HybVehHiVltInvDisRqd : 23|1@0+ (1,0) [0|1] "" Vector__XXX
 SG_ NESSRoSevSt : 24|1@0+ (1,0) [0|1] "" Vector__XXX
 SG_ NESSRiSiSevSt : 25|1@0+ (1,0) [0|1] "" Vector__XXX
 SG_ NESSReImpSevSt : 26|1@0+ (1,0) [0|1] "" Vector__XXX
 SG_ NESSLeSiSevSt : 27|1@0+ (1,0) [0|1] "" Vector__XXX
 SG_ NESSFrImpSt2SevSt : 28|1@0+ (1,0) [0|1] "" Vector__XXX
 SG_ NESSFrImpSt1SevSt : 29|1@0+ (1,0) [0|1] "" Vector__XXX
 SG_ NESSFrImpPreSevSt : 30|1@0+ (1,0) [0|1] "" Vector__XXX
 SG_ ClmCntFrBlwFnSp : 39|8@0+ (0.392157,0) [0|100.000035] "%"  EBCM_PHS

BO_ 872 ETRS_General_Request_2_PHS: 1 CGM3a_PHS
 SG_ ESBR_AutoBrkgRqTyp : 1|2@0+ (1,0) [0|3] ""  EBCM_PHS
 SG_ ESBR_AutoBrkgRqd : 2|1@0+ (1,0) [0|1] ""  EBCM_PHS
 SG_ ElcShftBrkgRqPVal : 7|3@0+ (1,0) [0|7] ""  EBCM_PHS
 SG_ ElcShftBrkgRqARC : 4|2@0+ (1,0) [0|3] ""  EBCM_PHS

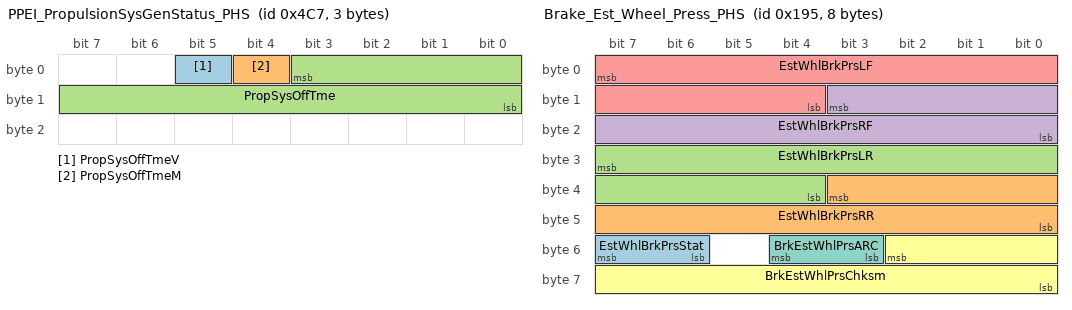
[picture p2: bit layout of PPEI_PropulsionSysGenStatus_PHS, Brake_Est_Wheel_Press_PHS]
BO_ 1223 PPEI_PropulsionSysGenStatus_PHS: 3 CGM3a_PHS
 SG_ PropSysOffTmeV : 5|1@0+ (1,0) [0|1] ""  EBCM_PHS
 SG_ PropSysOffTmeM : 4|1@0+ (1,0) [0|1] ""  EBCM_PHS
 SG_ PropSysOffTme : 3|12@0+ (0.5,0) [0|2047.5] "min"  EBCM_PHS

BO_ 405 Brake_Est_Wheel_Press_PHS: 8 EBCM_PHS
 SG_ EstWhlBrkPrsStat : 55|2@0+ (1,0) [0|3] ""  EBOOST_OBD_PHS,ADIMb_PHS
 SG_ EstWhlBrkPrsRR : 35|12@0+ (10,0) [0|40950] "kPa"  EBOOST_OBD_PHS,ADIMb_PHS
 SG_ EstWhlBrkPrsLR : 31|12@0+ (10,0) [0|40950] "kPa"  EBOOST_OBD_PHS,ADIMb_PHS
 SG_ EstWhlBrkPrsRF : 11|12@0+ (10,0) [0|40950] "kPa"  EBOOST_OBD_PHS,ADIMb_PHS
 SG_ EstWhlBrkPrsLF : 7|12@0+ (10,0) [0|40950] "kPa"  EBOOST_OBD_PHS,ADIMb_PHS
 SG_ BrkEstWhlPrsChksm : 50|11@0+ (1,0) [0|2047] ""  EBOOST_OBD_PHS,ADIMb_PHS
 SG_ BrkEstWhlPrsARC : 52|2@0+ (1,0) [0|3] ""  EBOOST_OBD_PHS,ADIMb_PHS

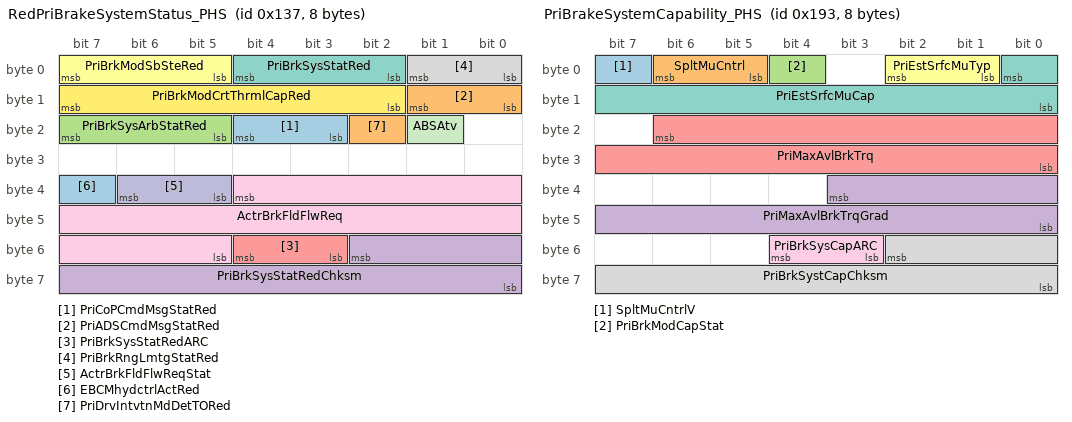
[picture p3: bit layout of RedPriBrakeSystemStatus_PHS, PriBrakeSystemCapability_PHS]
BO_ 311 RedPriBrakeSystemStatus_PHS: 8 EBCM_PHS
 SG_ PriCoPCmdMsgStatRed : 20|2@0+ (1,0) [0|3] ""  ADIMb_PHS,EBOOST_OBD_PHS
 SG_ PriADSCmdMsgStatRed : 9|2@0+ (1,0) [0|3] ""  ADIMb_PHS,EBOOST_OBD_PHS
 SG_ PriBrkSysArbStatRed : 23|3@0+ (1,0) [0|7] ""  ADIMb_PHS,EBOOST_OBD_PHS
 SG_ PriBrkSysStatRedChksm : 50|11@0+ (1,0) [0|2047] ""  ADIMb_PHS,EBOOST_OBD_PHS
 SG_ PriBrkSysStatRedARC : 52|2@0+ (1,0) [0|3] ""  ADIMb_PHS,EBOOST_OBD_PHS
 SG_ PriBrkModSbSteRed : 7|3@0+ (1,0) [0|7] ""  ADIMb_PHS,EBOOST_OBD_PHS
 SG_ PriBrkSysStatRed : 4|3@0+ (1,0) [0|7] ""  ADIMb_PHS,EBOOST_OBD_PHS
 SG_ PriBrkRngLmtgStatRed : 1|2@0+ (1,0) [0|3] ""  ADIMb_PHS,EBOOST_OBD_PHS
 SG_ ActrBrkFldFlwReq : 36|16@0+ (0.0076904296875,-252) [-252|252] "mL/s"  EBOOST_OBD_PHS
 SG_ ActrBrkFldFlwReqStat : 38|2@0+ (1,0) [0|3] ""  EBOOST_OBD_PHS
 SG_ ABSAtv : 17|1@0+ (1,0) [0|1] ""  EBOOST_OBD_PHS
 SG_ PriBrkModCrtThrmlCapRed : 15|6@0+ (1.5873,0) [0|100] "%"  EBOOST_OBD_PHS,ADIMb_PHS
 SG_ EBCMhydctrlActRed : 39|1@0+ (1,0) [0|1] ""  EBOOST_OBD_PHS
 SG_ PriDrvIntvtnMdDetTORed : 18|1@0+ (1,0) [0|1] ""  EBOOST_OBD_PHS,ADIMb_PHS

BO_ 403 PriBrakeSystemCapability_PHS: 8 EBCM_PHS
 SG_ SpltMuCntrlV : 7|1@0+ (1,0) [0|1] ""  ADIMb_PHS
 SG_ SpltMuCntrl : 6|2@0+ (1,0) [0|3] ""  ADIMb_PHS
 SG_ PriBrkModCapStat : 4|1@0+ (1,0) [0|1] ""  ADIMb_PHS
 SG_ PriMaxAvlBrkTrqGrad : 35|12@0+ (100,0) [0|409500] ""  ADIMb_PHS
 SG_ PriMaxAvlBrkTrq : 22|15@0+ (2,-65534) [-65534|0] "Nm"  ADIMb_PHS
 SG_ PriEstSrfcMuTyp : 2|2@0+ (1,0) [0|3] ""  ADIMb_PHS
 SG_ PriEstSrfcMuCap : 0|9@0+ (0.006,0) [0|3.066] ""  ADIMb_PHS
 SG_ PriBrkSystCapChksm : 50|11@0+ (1,0) [0|2047] ""  ADIMb_PHS
 SG_ PriBrkSysCapARC : 52|2@0+ (1,0) [0|3] ""  ADIMb_PHS

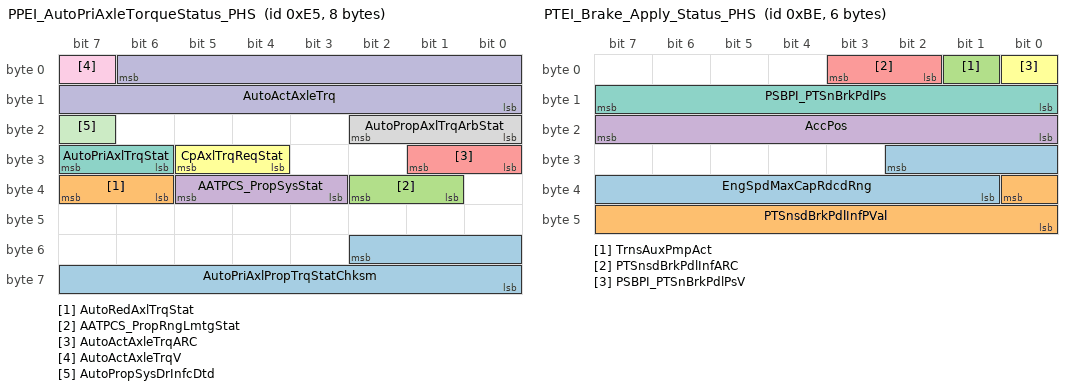
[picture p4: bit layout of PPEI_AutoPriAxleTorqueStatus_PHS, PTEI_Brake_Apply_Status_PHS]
BO_ 229 PPEI_AutoPriAxleTorqueStatus_PHS: 8 CGM3a_PHS
 SG_ AutoPriAxlPropTrqStatChksm : 50|11@0+ (1,0) [0|2047] ""  EOCM2cp_K1_PHS
 SG_ AutoRedAxlTrqStat : 39|2@0+ (1,0) [0|3] ""  EOCM2cp_K1_PHS
 SG_ AATPCS_PropRngLmtgStat : 34|2@0+ (1,0) [0|3] ""  EOCM2cp_K1_PHS
 SG_ AATPCS_PropSysStat : 37|3@0+ (1,0) [0|7] ""  EOCM2cp_K1_PHS
 SG_ AutoActAxleTrqARC : 25|2@0+ (1,0) [0|3] ""  EOCM2cp_K1_PHS
 SG_ CpAxlTrqReqStat : 29|2@0+ (1,0) [0|3] ""  EOCM2cp_K1_PHS
 SG_ AutoPriAxlTrqStat : 31|2@0+ (1,0) [0|3] ""  EOCM2cp_K1_PHS
 SG_ AutoPropAxlTrqArbStat : 18|3@0+ (1,0) [0|7] ""  EOCM2cp_K1_PHS
 SG_ AutoActAxleTrqV : 7|1@0+ (1,0) [0|1] ""  EOCM2cp_K1_PHS
 SG_ AutoActAxleTrq : 6|15@0+ (2,-22534) [-22534|43000] "Nm"  EOCM2cp_K1_PHS
 SG_ AutoPropSysDrInfcDtd : 23|1@0+ (1,0) [0|1] ""  EOCM2cp_K1_PHS

BO_ 190 PTEI_Brake_Apply_Status_PHS: 6 CGM3a_PHS
 SG_ EngSpdMaxCapRdcdRng : 26|10@0+ (8,0) [0|8184] "rpm" Vector__XXX
 SG_ PTSnsdBrkPdlInfPVal : 32|9@0+ (1,0) [0|511] ""  EBOOST_OBD_PHS,EBCM_PHS
 SG_ TrnsAuxPmpAct : 1|1@0+ (1,0) [0|1] "" Vector__XXX
 SG_ AccPos : 23|8@0+ (0.392157,0) [0|100.000035] "%" Vector__XXX
 SG_ PTSnsdBrkPdlInfARC : 3|2@0+ (1,0) [0|3] ""  EBOOST_OBD_PHS,EBCM_PHS
 SG_ PSBPI_PTSnBrkPdlPsV : 0|1@0+ (1,0) [0|1] ""  EBOOST_OBD_PHS,EBCM_PHS
 SG_ PSBPI_PTSnBrkPdlPs : 15|8@0+ (0.392157,0) [0|100.000035] "%"  EBOOST_OBD_PHS,EBCM_PHS

BO_ 288 Vehicle_Odometer_PHS: 5 CGM3a_PHS
 SG_ VehOdo : 7|32@0+ (0.015625,0) [0|67108863.984375] "km"  EOCM2cp_IMX6_PHS,EBOOST_OBD_PHS,EBCM_PHS
 SG_ VehOdoV : 32|1@0+ (1,0) [0|1] ""  EOCM2cp_IMX6_PHS,EBOOST_OBD_PHS,EBCM_PHS

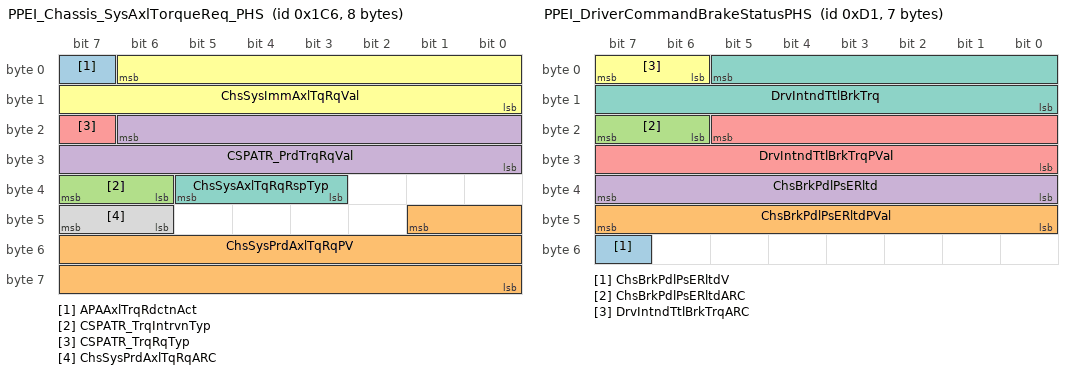
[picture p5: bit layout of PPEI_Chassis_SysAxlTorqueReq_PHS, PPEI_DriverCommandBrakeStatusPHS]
BO_ 454 PPEI_Chassis_SysAxlTorqueReq_PHS: 8 EBCM_PHS
 SG_ APAAxlTrqRdctnAct : 7|1@0+ (1,0) [0|1] ""  CGM3a_PHS
 SG_ ChsSysPrdAxlTqRqPV : 41|18@0+ (1,0) [0|262143] ""  CGM3a_PHS
 SG_ CSPATR_TrqIntrvnTyp : 39|2@0+ (1,0) [0|3] ""  CGM3a_PHS
 SG_ CSPATR_PrdTrqRqVal : 22|15@0+ (2,-22534) [-22534|43000] "Nm"  CGM3a_PHS
 SG_ CSPATR_TrqRqTyp : 23|1@0+ (1,0) [0|1] ""  CGM3a_PHS
 SG_ ChsSysImmAxlTqRqVal : 6|15@0+ (2,-22534) [-22534|43000] "Nm"  CGM3a_PHS
 SG_ ChsSysAxlTqRqRspTyp : 37|3@0+ (1,0) [0|7] ""  CGM3a_PHS
 SG_ ChsSysPrdAxlTqRqARC : 47|2@0+ (1,0) [0|3] ""  CGM3a_PHS

BO_ 209 PPEI_DriverCommandBrakeStatusPHS: 7 EBCM_PHS
 SG_ ChsBrkPdlPsERltdV : 55|1@0+ (1,0) [0|1] ""  CGM3a_PHS
 SG_ ChsBrkPdlPsERltdPVal : 47|8@0+ (1,0) [0|255] ""  CGM3a_PHS
 SG_ ChsBrkPdlPsERltdARC : 23|2@0+ (1,0) [0|3] ""  CGM3a_PHS
 SG_ ChsBrkPdlPsERltd : 39|8@0+ (0.392157,0) [0|100.000035] "%"  CGM3a_PHS
 SG_ DrvIntndTtlBrkTrqPVal : 21|14@0+ (1,0) [0|16383] ""  CGM3a_PHS
 SG_ DrvIntndTtlBrkTrqARC : 7|2@0+ (1,0) [0|3] ""  CGM3a_PHS
 SG_ DrvIntndTtlBrkTrq : 5|14@0+ (2,0) [0|32766] "Nm"  CGM3a_PHS

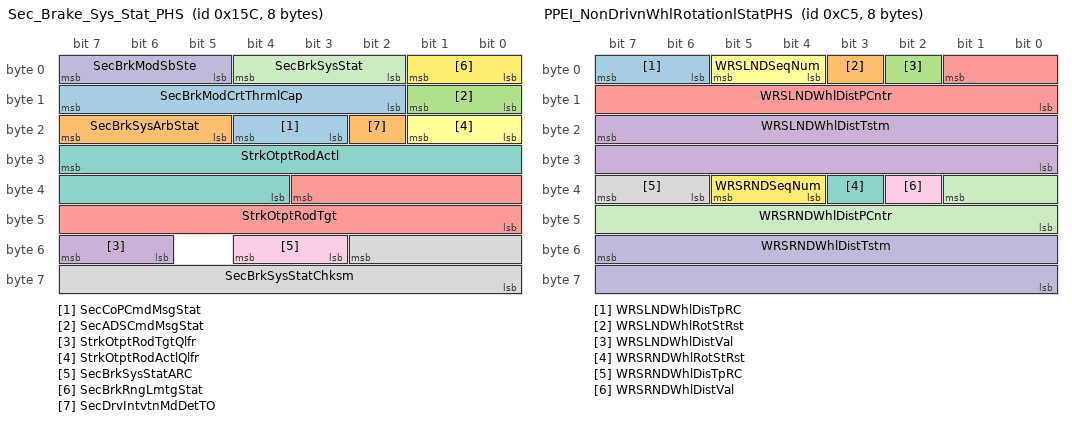
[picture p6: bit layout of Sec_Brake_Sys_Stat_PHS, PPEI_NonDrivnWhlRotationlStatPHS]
BO_ 348 Sec_Brake_Sys_Stat_PHS: 8 EBOOST_OBD_PHS
 SG_ SecCoPCmdMsgStat : 20|2@0+ (1,0) [0|3] ""  ADIMb_PHS,EBCM_PHS
 SG_ SecBrkSysArbStat : 23|3@0+ (1,0) [0|7] ""  ADIMb_PHS,EBCM_PHS
 SG_ SecADSCmdMsgStat : 9|2@0+ (1,0) [0|3] ""  ADIMb_PHS,EBCM_PHS
 SG_ StrkOtptRodTgtQlfr : 55|2@0+ (1,0) [0|3] ""  EBCM_PHS,ADIMb_PHS
 SG_ StrkOtptRodTgt : 35|12@0+ (0.015625,0) [0|64] "mm"  EBCM_PHS,ADIMb_PHS
 SG_ StrkOtptRodActlQlfr : 17|2@0+ (1,0) [0|3] ""  EBCM_PHS,ADIMb_PHS
 SG_ StrkOtptRodActl : 31|12@0+ (0.015625,0) [0|64] "mm"  EBCM_PHS,ADIMb_PHS
 SG_ SecBrkSysStatChksm : 50|11@0+ (1,0) [0|2047] ""  EBCM_PHS,ADIMb_PHS
 SG_ SecBrkSysStatARC : 52|2@0+ (1,0) [0|3] ""  EBCM_PHS,ADIMb_PHS
 SG_ SecBrkModSbSte : 7|3@0+ (1,0) [0|7] ""  EBCM_PHS,ADIMb_PHS
 SG_ SecBrkSysStat : 4|3@0+ (1,0) [0|7] ""  EBCM_PHS,ADIMb_PHS
 SG_ SecBrkRngLmtgStat : 1|2@0+ (1,0) [0|3] ""  EBCM_PHS,ADIMb_PHS
 SG_ SecBrkModCrtThrmlCap : 15|6@0+ (1.5873,0) [0|100] "%"  EBCM_PHS,ADIMb_PHS
 SG_ SecDrvIntvtnMdDetTO : 18|1@0+ (1,0) [0|1] ""  EBCM_PHS,ADIMb_PHS

BO_ 197 PPEI_NonDrivnWhlRotationlStatPHS: 8 EBCM_PHS
 SG_ WRSLNDWhlDisTpRC : 7|2@0+ (1,0) [0|3] "counts"  ADIMb_PHS,CGM3a_PHS
 SG_ WRSLNDWhlRotStRst : 3|1@0+ (1,0) [0|1] ""  ADIMb_PHS,CGM3a_PHS
 SG_ WRSLNDWhlDistVal : 2|1@0+ (1,0) [0|1] ""  ADIMb_PHS,CGM3a_PHS
 SG_ WRSLNDWhlDistTstm : 23|16@0+ (1,0) [0|65535] "counts"  ADIMb_PHS,CGM3a_PHS
 SG_ WRSLNDWhlDistPCntr : 1|10@0+ (1,0) [0|1023] "counts"  ADIMb_PHS,CGM3a_PHS
 SG_ WRSLNDSeqNum : 5|2@0+ (1,0) [0|3] "counts"  ADIMb_PHS,CGM3a_PHS
 SG_ WRSRNDWhlRotStRst : 35|1@0+ (1,0) [0|1] ""  ADIMb_PHS,CGM3a_PHS
 SG_ WRSRNDWhlDisTpRC : 39|2@0+ (1,0) [0|3] "counts"  ADIMb_PHS,CGM3a_PHS
 SG_ WRSRNDWhlDistVal : 34|1@0+ (1,0) [0|1] ""  ADIMb_PHS,CGM3a_PHS
 SG_ WRSRNDWhlDistTstm : 55|16@0+ (1,0) [0|65535] "counts"  ADIMb_PHS,CGM3a_PHS
 SG_ WRSRNDWhlDistPCntr : 33|10@0+ (1,0) [0|1023] "counts"  ADIMb_PHS,CGM3a_PHS
 SG_ WRSRNDSeqNum : 37|2@0+ (1,0) [0|3] "counts"  ADIMb_PHS,CGM3a_PHS

BO_ 500 PPEI_DrvPrefModeSwitchStatus_PHS: 6 CGM3a_PHS
 SG_ EnhDrvMdSwChUseAct : 40|1@0+ (1,0) [0|1] ""  EBCM_PHS
 SG_ EnhDrvSelMdSwStat : 42|2@0+ (1,0) [0|3] ""  EBCM_PHS
 SG_ DrvSelMd8Stat : 17|1@0+ (1,0) [0|1] ""  EBCM_PHS
 SG_ DrvSelMd8ReqDnd : 16|1@0+ (1,0) [0|1] "" Vector__XXX
 SG_ DrvSelMd7Stat : 19|1@0+ (1,0) [0|1] ""  EBCM_PHS
 SG_ DrvSelMd7ReqDnd : 18|1@0+ (1,0) [0|1] "" Vector__XXX
 SG_ DrvSelMd6Stat : 21|1@0+ (1,0) [0|1] ""  EBCM_PHS
 SG_ DrvSelMd6ReqDnd : 20|1@0+ (1,0) [0|1] "" Vector__XXX
 SG_ DrvSelMd5Stat : 23|1@0+ (1,0) [0|1] ""  EBCM_PHS
 SG_ DrvSelMd5ReqDnd : 22|1@0+ (1,0) [0|1] "" Vector__XXX
 SG_ DrvSelMd4Stat : 9|1@0+ (1,0) [0|1] ""  EBCM_PHS
 SG_ DrvSelMd4ReqDnd : 8|1@0+ (1,0) [0|1] "" Vector__XXX
 SG_ DrvSelMd3Stat : 11|1@0+ (1,0) [0|1] ""  EBCM_PHS
 SG_ DrvSelMd3ReqDnd : 10|1@0+ (1,0) [0|1] "" Vector__XXX
 SG_ DrvSelMd2Stat : 13|1@0+ (1,0) [0|1] ""  EBCM_PHS
 SG_ DrvSelMd2ReqDnd : 12|1@0+ (1,0) [0|1] "" Vector__XXX
 SG_ DSMSS_DrvSelMd0Pn : 47|1@0+ (1,0) [0|1] ""  EBCM_PHS
 SG_ DSMSS_DrvSelMd8Pn : 32|1@0+ (1,0) [0|1] ""  EBCM_PHS
 SG_ DSMSS_DrvSelMd7Pn : 33|1@0+ (1,0) [0|1] ""  EBCM_PHS
 SG_ DSMSS_DrvSelMd6Pn : 34|1@0+ (1,0) [0|1] ""  EBCM_PHS
 SG_ DSMSS_DrvSelMd5Pn : 35|1@0+ (1,0) [0|1] ""  EBCM_PHS
 SG_ DSMSS_DrvSelMd4Pn : 36|1@0+ (1,0) [0|1] ""  EBCM_PHS
 SG_ DSMSS_DrvSelMd3Pn : 37|1@0+ (1,0) [0|1] ""  EBCM_PHS
 SG_ DSMSS_DrvSelMd2Pn : 38|1@0+ (1,0) [0|1] ""  EBCM_PHS
 SG_ DSMSS_DrvSelMd1Pn : 39|1@0+ (1,0) [0|1] ""  EBCM_PHS
 SG_ DSMSS_DrvSelMd8Un : 24|1@0+ (1,0) [0|1] ""  EBCM_PHS
 SG_ DSMSS_DrvSelMd7Un : 25|1@0+ (1,0) [0|1] ""  EBCM_PHS
 SG_ DSMSS_DrvSelMd6Un : 26|1@0+ (1,0) [0|1] ""  EBCM_PHS
 SG_ DSMSS_DrvSelMd5Un : 27|1@0+ (1,0) [0|1] ""  EBCM_PHS
 SG_ DSMSS_DrvSelMd4Un : 28|1@0+ (1,0) [0|1] ""  EBCM_PHS
 SG_ DSMSS_DrvSelMd3Un : 29|1@0+ (1,0) [0|1] ""  EBCM_PHS
 SG_ DSMSS_DrvSelMd2Un : 30|1@0+ (1,0) [0|1] ""  EBCM_PHS
 SG_ DSMSS_DrvSelMd1Un : 31|1@0+ (1,0) [0|1] ""  EBCM_PHS
 SG_ DrvSelMd1ReqDnd : 14|1@0+ (1,0) [0|1] "" Vector__XXX
 SG_ DrvSelMd1Stat : 15|1@0+ (1,0) [0|1] ""  EBCM_PHS

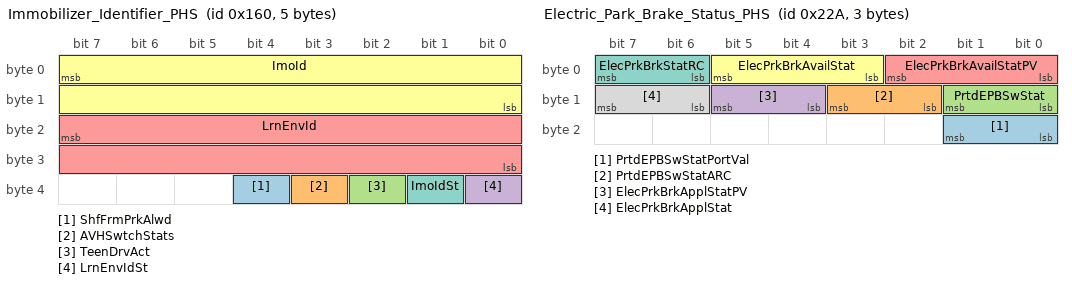
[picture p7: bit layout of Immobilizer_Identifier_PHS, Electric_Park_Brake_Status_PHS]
BO_ 352 Immobilizer_Identifier_PHS: 5 CGM3a_PHS
 SG_ ShfFrmPrkAlwd : 36|1@0+ (1,0) [0|1] "" Vector__XXX
 SG_ AVHSwtchStats : 35|1@0+ (1,0) [0|1] ""  EBCM_PHS
 SG_ TeenDrvAct : 34|1@0+ (1,0) [0|1] ""  EBCM_PHS
 SG_ LrnEnvIdSt : 32|1@0+ (1,0) [0|1] ""  EBCM_PHS
 SG_ LrnEnvId : 23|16@0+ (1,0) [0|65535] ""  EBCM_PHS
 SG_ ImoId : 7|16@0+ (1,0) [0|65535] ""  EBCM_PHS
 SG_ ImoIdSt : 33|1@0+ (1,0) [0|1] ""  EBCM_PHS

BO_ 554 Electric_Park_Brake_Status_PHS: 3 EBCM_PHS
 SG_ PrtdEPBSwStatPortVal : 17|2@0+ (1,0) [0|3] "Counts"  CGM3a_PHS
 SG_ PrtdEPBSwStatARC : 11|2@0+ (1,0) [0|3] "Counts"  CGM3a_PHS
 SG_ PrtdEPBSwStat : 9|2@0+ (1,0) [0|3] ""  CGM3a_PHS
 SG_ ElecPrkBrkApplStatPV : 13|2@0+ (1,0) [0|3] ""  CGM3a_PHS,EBCM_PHS
 SG_ ElecPrkBrkAvailStatPV : 2|3@0+ (1,0) [0|7] ""  CGM3a_PHS,EBCM_PHS
 SG_ ElecPrkBrkAvailStat : 5|3@0+ (1,0) [0|7] ""  CGM3a_PHS,EBCM_PHS
 SG_ ElecPrkBrkStatRC : 7|2@0+ (1,0) [0|3] ""  CGM3a_PHS,EBCM_PHS
 SG_ ElecPrkBrkApplStat : 15|2@0+ (1,0) [0|3] ""  CGM3a_PHS,EBCM_PHS

BO_ 566 VICM_Status_PHS: 7 CGM3a_PHS
 SG_ RdHVBatHtrCntctrStat : 51|2@0+ (1,0) [0|3] "" Vector__XXX
 SG_ ChrgSysShftPrkReqPval : 44|2@0+ (1,0) [0|3] "" Vector__XXX
 SG_ ChrgSysShftPrkReqARC : 42|2@0+ (1,0) [0|3] "" Vector__XXX
 SG_ ChrgSysShftPrkReq : 40|1@0+ (1,0) [0|1] "" Vector__XXX
 SG_ ChrgSysAudblIndRq : 39|3@0+ (1,0) [0|7] "" Vector__XXX
 SG_ HVBatChrgCrdAlrtReq : 7|2@0+ (1,0) [0|3] "" Vector__XXX
 SG_ RdHVBatLwParMdReq : 32|1@0+ (1,0) [0|1] "" Vector__XXX
 SG_ RdHVBtClOVFFTstRq : 31|1@0+ (1,0) [0|1] "" Vector__XXX
 SG_ RdHVBtClOVFFTstIdx : 30|7@0+ (1,0) [0|127] "" Vector__XXX
 SG_ ClimCtrlHVDvcShtdwnCmd : 23|1@0+ (1,0) [0|1] "" Vector__XXX
 SG_ ThrmlRefCompSpdReqARC : 36|2@0+ (1,0) [0|3] " " Vector__XXX
 SG_ VICMHVEnMgCmEnTrS : 22|1@0+ (1,0) [0|1] "" Vector__XXX
 SG_ ChrgSysPrkBrkAnmsBrkReqPVal : 20|2@0+ (1,0) [0|3] ""  EBCM_PHS
 SG_ ChrgSysPrkBrkAnmsBrkReqARC : 18|2@0+ (1,0) [0|3] ""  EBCM_PHS
 SG_ ChrgSysPrkBrkAnmsBrkReq : 16|1@0+ (1,0) [0|1] ""  EBCM_PHS
 SG_ HybVehHiVltSysDisbld_236 : 21|1@0+ (1,0) [0|1] "" Vector__XXX
 SG_ ThrmlRefCompSpdReq : 5|14@0+ (1,0) [0|16383] "rpm" Vector__XXX
 SG_ RHVBCCS_ACChrgrCntCmd : 52|1@0+ (1,0) [0|1] "" Vector__XXX
 SG_ RHVBCCS_InvtrCntCmd : 53|1@0+ (1,0) [0|1] "" Vector__XXX
 SG_ RHVBCCS_InvtrCaptrChrgAct : 54|1@0+ (1,0) [0|1] "" Vector__XXX
 SG_ RHVBCCS_DCChrgrCntCmd : 55|1@0+ (1,0) [0|1] "" Vector__XXX
 SG_ RdDCChrgCntctrStat : 34|2@0+ (1,0) [0|3] "" Vector__XXX
 SG_ RdHVCntctrShdwnCmd : 47|3@0+ (1,0) [0|7] "" Vector__XXX

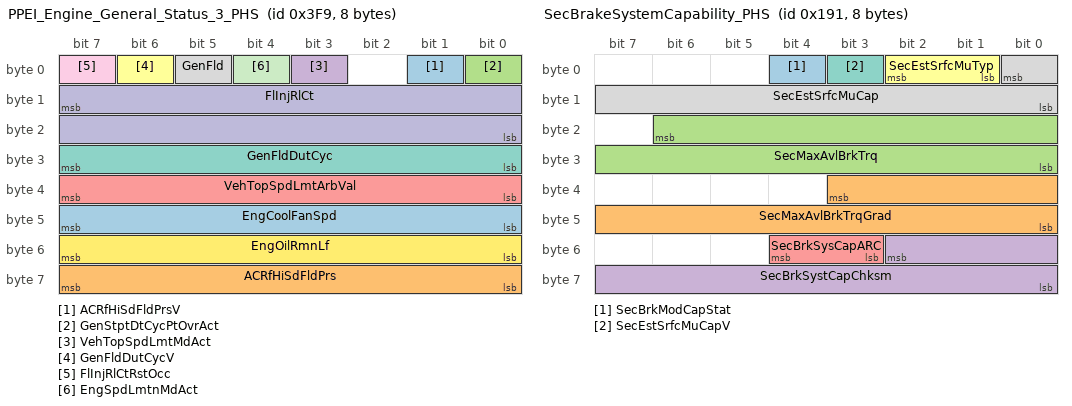
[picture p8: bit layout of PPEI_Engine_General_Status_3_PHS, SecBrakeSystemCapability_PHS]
BO_ 1017 PPEI_Engine_General_Status_3_PHS: 8 CGM3a_PHS
 SG_ ACRfHiSdFldPrsV : 1|1@0+ (1,0) [0|1] ""  Dummy_PHS
 SG_ ACRfHiSdFldPrs : 63|8@0+ (14,0) [0|3570] "kPaG"  Dummy_PHS
 SG_ GenStptDtCycPtOvrAct : 0|1@0+ (1,0) [0|1] ""  Dummy_PHS
 SG_ VehTopSpdLmtMdAct : 3|1@0+ (1,0) [0|1] ""  Dummy_PHS
 SG_ VehTopSpdLmtArbVal : 39|8@0+ (2,0) [0|510] "km / h"  Dummy_PHS
 SG_ GenFldDutCycV : 6|1@0+ (1,0) [0|1] ""  Dummy_PHS
 SG_ GenFldDutCyc : 31|8@0+ (0.392157,0) [0|100.000035] "%"  Dummy_PHS
 SG_ GenFld : 5|1@0+ (1,0) [0|1] ""  Dummy_PHS
 SG_ FlInjRlCtRstOcc : 7|1@0+ (1,0) [0|1] ""  Dummy_PHS
 SG_ FlInjRlCt : 15|16@0+ (3.05176E-005,0) [0|1.999970916] "liters"  Dummy_PHS
 SG_ EngSpdLmtnMdAct : 4|1@0+ (1,0) [0|1] ""  Dummy_PHS
 SG_ EngOilRmnLf : 55|8@0+ (0.392157,0) [0|100.000035] "%"  Dummy_PHS
 SG_ EngCoolFanSpd : 47|8@0+ (0.392157,0) [0|100.000035] "%"  Dummy_PHS

BO_ 401 SecBrakeSystemCapability_PHS: 8 EBOOST_OBD_PHS
 SG_ SecBrkModCapStat : 4|1@0+ (1,0) [0|1] ""  ADIMb_PHS
 SG_ SecMaxAvlBrkTrqGrad : 35|12@0+ (100,0) [0|409500] ""  ADIMb_PHS
 SG_ SecMaxAvlBrkTrq : 22|15@0+ (2,-65534) [-65534|0] "Nm"  ADIMb_PHS
 SG_ SecBrkSystCapChksm : 50|11@0+ (1,0) [0|2047] ""  ADIMb_PHS
 SG_ SecBrkSysCapARC : 52|2@0+ (1,0) [0|3] ""  ADIMb_PHS
 SG_ SecEstSrfcMuTyp : 2|2@0+ (1,0) [0|3] ""  ADIMb_PHS
 SG_ SecEstSrfcMuCapV : 3|1@0+ (1,0) [0|1] ""  ADIMb_PHS
 SG_ SecEstSrfcMuCap : 0|9@0+ (0.006,0) [0|3.066] ""  ADIMb_PHS

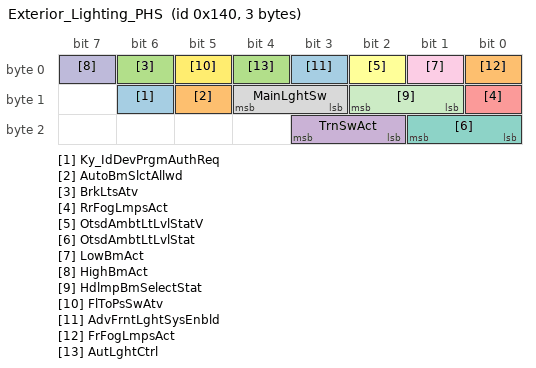
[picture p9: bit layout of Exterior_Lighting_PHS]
BO_ 320 Exterior_Lighting_PHS: 3 CGM3a_PHS
 SG_ Ky_IdDevPrgmAuthReq : 14|1@0+ (1,0) [0|1] ""  EOCM2cp_IMX6_PHS
 SG_ AutoBmSlctAllwd : 13|1@0+ (1,0) [0|1] ""  EOCM2cp_IMX6_PHS
 SG_ BrkLtsAtv : 6|1@0+ (1,0) [0|1] ""  EOCM2cp_IMX6_PHS
 SG_ TrnSwAct : 19|2@0+ (1,0) [0|3] ""  EOCM2cp_IMX6_PHS,EBCM_PHS
 SG_ RrFogLmpsAct : 8|1@0+ (1,0) [0|1] ""  EOCM2cp_IMX6_PHS
 SG_ OtsdAmbtLtLvlStatV : 2|1@0+ (1,0) [0|1] ""  EOCM2cp_IMX6_PHS
 SG_ OtsdAmbtLtLvlStat : 17|2@0+ (1,0) [0|3] ""  EOCM2cp_IMX6_PHS
 SG_ MainLghtSw : 12|2@0+ (1,0) [0|3] "N/A"  EOCM2cp_IMX6_PHS
 SG_ LowBmAct : 1|1@0+ (1,0) [0|1] ""  EOCM2cp_IMX6_PHS
 SG_ HighBmAct : 7|1@0+ (1,0) [0|1] ""  EOCM2cp_IMX6_PHS
 SG_ HdlmpBmSelectStat : 10|2@0+ (1,0) [0|3] ""  EOCM2cp_IMX6_PHS
 SG_ FlToPsSwAtv : 5|1@0+ (1,0) [0|1] ""  EOCM2cp_IMX6_PHS
 SG_ AdvFrntLghtSysEnbld : 3|1@0+ (1,0) [0|1] ""  EOCM2cp_IMX6_PHS
 SG_ FrFogLmpsAct : 0|1@0+ (1,0) [0|1] ""  EOCM2cp_IMX6_PHS
 SG_ AutLghtCtrl : 4|1@0+ (1,0) [0|1] "N/A"  EOCM2cp_IMX6_PHS

CM_ "Private HS bus";
CM_ BU_ Dummy_PHS "This is to avoid single ended signalling";
CM_ BU_ EBOOST_OBD_PHS "Electric Brake Booster OBD";
CM_ BU_ EOCM2cp_IMX6_PHS "External Object Control Module Safety co-pilot - IMX6 micro";
CM_ BU_ EOCM2cp_K1_PHS "External Object Control Module Safety co-pilot - K1 micro";
CM_ BU_ EPSb_PHS "Electronic Power Steering 2";
CM_ BU_ EBCM_PHS "Electronic Brake Control Module";
CM_ BU_ EPSa_PHS "Electronic Power Steering";
CM_ BU_ CMMb_PHS "Chassis Motion Module";
CM_ BU_ CGM3a_PHS "Communication Gateway - Primary";
CM_ BU_ CMMa_PHS "Chassis Motion Module";
CM_ BU_ ADIMb_PHS "Autonomous Drive Interface Module";
CM_ SG_ 320 MainLghtSw "Operator selection for the main lighting switch";
CM_ SG_ 320 AutLghtCtrl "This signal represents if Automatic Lights Control feature is active/inactive";
BA_DEF_  "BusType" STRING ;
BA_DEF_ SG_  "VNSigSLHSSharedDiagnostic" ENUM  "No","Yes";
BA_DEF_ SG_  "SignalType" STRING ;
BA_DEF_ SG_  "PacketOrder" INT 0 65535;
BA_DEF_ SG_  "SignalLongName" STRING ;
BA_DEF_ SG_  "GenSigStartValue" INT 0 65535;
BA_DEF_ SG_  "VNSigAllNodes" ENUM  "No","Yes";
BA_DEF_ SG_  "GenSigSendType" ENUM  "not used","not used","not used","not used","not used","not used","not used","NoSigSendType","not used","not used","OnAnyChange","OnChangeIfActive","OnDelta";
BA_DEF_ SG_  "GenSigSendOnInit" ENUM  "Not Initialized","Application","Handler";
BA_DEF_ BO_  "AppGenMsgCycleTime" INT 0 0;
BA_DEF_ BO_  "GenMsgILSupport" ENUM  "No","Yes";
BA_DEF_ BO_  "TpApplType" STRING ;
BA_DEF_ BO_  "Prio" INT 0 7;
BA_DEF_ BO_  "MessageSubnet" ENUM  "LS","HS","CE","PE","HV","FO","LE","HE2","PHS","PCE","DLCLS","DLCHS","DLCCE","DLCFO";
BA_DEF_ BO_  "DiagState" ENUM  "No","Yes";
BA_DEF_ BO_  "GenMsgStartDelayTime" INT 0 100000;
BA_DEF_ BO_  "GenMsgDelayTime" INT 0 100000;
BA_DEF_ BO_  "GenMsgCycleTime" INT 0 100000;
BA_DEF_ BO_  "GenMsgSendType" ENUM  "cyclicX","spontanX","cyclicIfActiveX","spontanWithDelay","cyclicAndSpontanX","cyclicAndSpontanWithDelay","spontanWithRepitition","cyclicIfActiveAndSpontanWD";
BA_DEF_ BO_  "DiagResponse" ENUM  "No","Yes";
BA_DEF_ BO_  "DiagRequest" ENUM  "No","Yes";
BA_DEF_ BO_  "NmMessage" ENUM  "No","Yes";
BA_DEF_ BU_  "MessageManagerUsed" ENUM  "No","Yes";
BA_DEF_ BU_  "NmNode" ENUM  "No","Yes";
BA_DEF_ BU_  "ILUsed" ENUM  "No","Yes";
BA_DEF_ BU_  "NodeLayerModules" STRING ;
BA_DEF_ BU_  "VNECUSLHSSharedDiagnostic" ENUM  "None","Activator","Remoted","Activator and Remoted","Shared Local";
BA_DEF_ BU_  "VNECUAllNodes" ENUM  "None","Activator","Remoted","Activator and Remoted","Shared Local";
BA_DEF_ BU_  "ECU_Id" HEX 0 255;
BA_DEF_ BU_  "SourceId" HEX 0 253;
BA_DEF_  "VersionMonth" INT 0 255;
BA_DEF_  "SyncJumpWidthMax" INT 0 255;
BA_DEF_  "SyncJumpWidthMin" INT 0 255;
BA_DEF_  "SamplePointMax" FLOAT 0 100;
BA_DEF_  "SamplePointMin" FLOAT 0 100;
BA_DEF_  "Baudrate" INT 0 1000000;
BA_DEF_  "VehicleArchitecture" STRING ;
BA_DEF_  "VNInitActSLHSSharedDiagnostic" ENUM  "No","Yes";
BA_DEF_  "VN_SLHSSharedDiagnostic" INT 0 255;
BA_DEF_  "VersionNumber" INT 0 65535;
BA_DEF_  "NmMessageCount" INT 0 32;
BA_DEF_  "NmBaseAddress" HEX 0 2032;
BA_DEF_  "NetworkType" STRING ;
BA_DEF_  "VNMFPeriodicInterval" INT 0 65535;
BA_DEF_  "BusWakeUpDelay" INT 0 65535;
BA_DEF_  "BusOffRecoveryTime" INT 0 65535;
BA_DEF_  "NodeStatusMsgID" HEX 0 536870911;
BA_DEF_  "NodeStatusMsgCycleTime" INT 0 65535;
BA_DEF_  "NodeStatusMsgTimeoutTime" INT 0 65535;
BA_DEF_  "UseGMParameterIDs" INT 0 1;
BA_DEF_  "VersionWeek" INT 0 255;
BA_DEF_  "VersionYear" INT 0 255;
BA_DEF_  "VN_AllNodes" INT 0 255;
BA_DEF_  "Manufacturer" ENUM  "DBAG","VAG","BMW","PAG","GM";
BA_DEF_  "NmType" STRING ;
BA_DEF_REL_ BU_SG_REL_  "GenSigSuprvRespComment" STRING ;
BA_DEF_REL_ BU_SG_REL_  "GenSigVBitResp" ENUM  "No","Yes";
BA_DEF_REL_ BU_SG_REL_  "GenSigVBitRespComment" STRING ;
BA_DEF_REL_ BU_SG_REL_  "GenSigVDAFailComment" STRING ;
BA_DEF_REL_ BU_SG_REL_  "GenSigVDAFailResp" ENUM  "No","Yes";
BA_DEF_REL_ BU_SG_REL_  "GenSigRxStartValue" STRING ;
BA_DEF_REL_ BU_SG_REL_  "GenSigSuprvResp" ENUM  "None","Notify App","Substitute Default";
BA_DEF_REL_ BU_SG_REL_  "GenSigTimeoutMsg" HEX 0 268435455;
BA_DEF_REL_ BU_SG_REL_  "GenSigTimeoutTime" INT 0 15000;
BA_DEF_DEF_  "BusType" "";
BA_DEF_DEF_  "VNSigSLHSSharedDiagnostic" "No";
BA_DEF_DEF_  "SignalType" "";
BA_DEF_DEF_  "PacketOrder" 0;
BA_DEF_DEF_  "SignalLongName" "";
BA_DEF_DEF_  "GenSigStartValue" 0;
BA_DEF_DEF_  "VNSigAllNodes" "No";
BA_DEF_DEF_  "GenSigSendType" "NoSigSendType";
BA_DEF_DEF_  "GenSigSendOnInit" "Not Initialized";
BA_DEF_DEF_  "AppGenMsgCycleTime" 0;
BA_DEF_DEF_  "GenMsgILSupport" "Yes";
BA_DEF_DEF_  "TpApplType" "";
BA_DEF_DEF_  "Prio" 4;
BA_DEF_DEF_  "MessageSubnet" "LS";
BA_DEF_DEF_  "DiagState" "No";
BA_DEF_DEF_  "GenMsgStartDelayTime" 0;
BA_DEF_DEF_  "GenMsgDelayTime" 0;
BA_DEF_DEF_  "GenMsgCycleTime" 0;
BA_DEF_DEF_  "GenMsgSendType" "spontanX";
BA_DEF_DEF_  "DiagResponse" "No";
BA_DEF_DEF_  "DiagRequest" "No";
BA_DEF_DEF_  "NmMessage" "No";
BA_DEF_DEF_REL_ "GenSigSuprvRespComment" "";
BA_DEF_DEF_REL_ "GenSigVBitResp" "No";
BA_DEF_DEF_REL_ "GenSigVBitRespComment" "";
BA_DEF_DEF_REL_ "GenSigVDAFailComment" "";
BA_DEF_DEF_REL_ "GenSigVDAFailResp" "No";
BA_DEF_DEF_REL_ "GenSigRxStartValue" "";
BA_DEF_DEF_REL_ "GenSigSuprvResp" "None";
BA_DEF_DEF_REL_ "GenSigTimeoutMsg" 0;
BA_DEF_DEF_REL_ "GenSigTimeoutTime" 0;
BA_DEF_DEF_  "MessageManagerUsed" "Yes";
BA_DEF_DEF_  "NmNode" "Yes";
BA_DEF_DEF_  "ILUsed" "Yes";
BA_DEF_DEF_  "NodeLayerModules" "gmlan02.dll";
BA_DEF_DEF_  "VNECUSLHSSharedDiagnostic" "None";
BA_DEF_DEF_  "VNECUAllNodes" "None";
BA_DEF_DEF_  "ECU_Id" 0;
BA_DEF_DEF_  "SourceId" 0;
BA_DEF_DEF_  "VersionMonth" 0;
BA_DEF_DEF_  "SyncJumpWidthMax" 0;
BA_DEF_DEF_  "SyncJumpWidthMin" 0;
BA_DEF_DEF_  "SamplePointMax" 0;
BA_DEF_DEF_  "SamplePointMin" 0;
BA_DEF_DEF_  "Baudrate" 0;
BA_DEF_DEF_  "VehicleArchitecture" "";
BA_DEF_DEF_  "VNInitActSLHSSharedDiagnostic" "No";
BA_DEF_DEF_  "VN_SLHSSharedDiagnostic" 0;
BA_DEF_DEF_  "VersionNumber" 0;
BA_DEF_DEF_  "NmMessageCount" 32;
BA_DEF_DEF_  "NmBaseAddress" 1568;
BA_DEF_DEF_  "NetworkType" "";
BA_DEF_DEF_  "VNMFPeriodicInterval" 3000;
BA_DEF_DEF_  "BusWakeUpDelay" 100;
BA_DEF_DEF_  "BusOffRecoveryTime" 0;
BA_DEF_DEF_  "NodeStatusMsgID" 268427264;
BA_DEF_DEF_  "NodeStatusMsgCycleTime" 1200;
BA_DEF_DEF_  "NodeStatusMsgTimeoutTime" 0;
BA_DEF_DEF_  "UseGMParameterIDs" 1;
BA_DEF_DEF_  "VersionWeek" 0;
BA_DEF_DEF_  "VersionYear" 0;
BA_DEF_DEF_  "VN_AllNodes" 1;
BA_DEF_DEF_  "Manufacturer" "GM";
BA_DEF_DEF_  "NmType" "GMLAN";
BA_ "VersionMonth" 19;
BA_ "SyncJumpWidthMax" 4;
BA_ "SyncJumpWidthMin" 3;
BA_ "SamplePointMax" 81.25;
BA_ "SamplePointMin" 80;
BA_ "Baudrate" 500000;
BA_ "VehicleArchitecture" "Autonomous";
BA_ "VNInitActSLHSSharedDiagnostic" 1;
BA_ "NmMessageCount" 16;
BA_ "NmBaseAddress" 1536;
BA_ "NetworkType" "Powertrain";
BA_ "BusOffRecoveryTime" 160;
BA_ "NodeStatusMsgID" 0;
BA_ "UseGMParameterIDs" 0;
BA_ "VersionWeek" 38;
BA_ "VersionYear" 19;
BA_ "BusType" "CAN";
BA_ "VNECUSLHSSharedDiagnostic" BU_ Dummy_PHS 4;
BA_ "VNECUAllNodes" BU_ Dummy_PHS 4;
BA_ "VNECUSLHSSharedDiagnostic" BU_ EBOOST_OBD_PHS 4;
BA_ "VNECUAllNodes" BU_ EBOOST_OBD_PHS 4;
BA_ "ECU_Id" BU_ EBOOST_OBD_PHS 20;
BA_ "SourceId" BU_ EBOOST_OBD_PHS 43;
BA_ "VNECUSLHSSharedDiagnostic" BU_ EOCM2cp_IMX6_PHS 4;
BA_ "VNECUAllNodes" BU_ EOCM2cp_IMX6_PHS 4;
BA_ "SourceId" BU_ EOCM2cp_IMX6_PHS 220;
BA_ "VNECUSLHSSharedDiagnostic" BU_ EOCM2cp_K1_PHS 4;
BA_ "VNECUAllNodes" BU_ EOCM2cp_K1_PHS 4;
BA_ "ECU_Id" BU_ EOCM2cp_K1_PHS 11;
BA_ "SourceId" BU_ EOCM2cp_K1_PHS 108;
BA_ "VNECUSLHSSharedDiagnostic" BU_ EPSb_PHS 4;
BA_ "VNECUAllNodes" BU_ EPSb_PHS 4;
BA_ "ECU_Id" BU_ EPSb_PHS 10;
BA_ "SourceId" BU_ EPSb_PHS 48;
BA_ "VNECUSLHSSharedDiagnostic" BU_ EBCM_PHS 4;
BA_ "VNECUAllNodes" BU_ EBCM_PHS 4;
BA_ "ECU_Id" BU_ EBCM_PHS 3;
BA_ "SourceId" BU_ EBCM_PHS 40;
BA_ "VNECUSLHSSharedDiagnostic" BU_ EPSa_PHS 4;
BA_ "VNECUAllNodes" BU_ EPSa_PHS 4;
BA_ "ECU_Id" BU_ EPSa_PHS 2;
BA_ "SourceId" BU_ EPSa_PHS 49;
BA_ "VNECUSLHSSharedDiagnostic" BU_ CMMb_PHS 4;
BA_ "VNECUAllNodes" BU_ CMMb_PHS 4;
BA_ "ECU_Id" BU_ CMMb_PHS 22;
BA_ "SourceId" BU_ CMMb_PHS 62;
BA_ "VNECUSLHSSharedDiagnostic" BU_ CGM3a_PHS 4;
BA_ "VNECUAllNodes" BU_ CGM3a_PHS 4;
BA_ "ECU_Id" BU_ CGM3a_PHS 31;
BA_ "SourceId" BU_ CGM3a_PHS 69;
BA_ "VNECUSLHSSharedDiagnostic" BU_ CMMa_PHS 4;
BA_ "VNECUAllNodes" BU_ CMMa_PHS 4;
BA_ "ECU_Id" BU_ CMMa_PHS 27;
BA_ "SourceId" BU_ CMMa_PHS 61;
BA_ "VNECUSLHSSharedDiagnostic" BU_ ADIMb_PHS 4;
BA_ "VNECUAllNodes" BU_ ADIMb_PHS 4;
BA_ "ECU_Id" BU_ ADIMb_PHS 15;
BA_ "SourceId" BU_ ADIMb_PHS 8;
BA_ "Prio" BO_ 1008 0;
BA_ "MessageSubnet" BO_ 1008 8;
BA_ "GenMsgCycleTime" BO_ 1008 100;
BA_ "GenMsgSendType" BO_ 1008 0;
BA_ "Prio" BO_ 647 0;
BA_ "MessageSubnet" BO_ 647 8;
BA_ "GenMsgCycleTime" BO_ 647 25;
BA_ "GenMsgSendType" BO_ 647 0;
BA_ "Prio" BO_ 170 0;
BA_ "MessageSubnet" BO_ 170 8;
BA_ "GenMsgCycleTime" BO_ 170 12;
BA_ "GenMsgSendType" BO_ 170 0;
BA_ "Prio" BO_ 1105 0;
BA_ "MessageSubnet" BO_ 1105 8;
BA_ "GenMsgStartDelayTime" BO_ 1105 10;
BA_ "GenMsgCycleTime" BO_ 1105 100;
BA_ "GenMsgSendType" BO_ 1105 0;
BA_ "Prio" BO_ 872 0;
BA_ "MessageSubnet" BO_ 872 8;
BA_ "GenMsgCycleTime" BO_ 872 25;
BA_ "GenMsgSendType" BO_ 872 0;
BA_ "Prio" BO_ 1223 0;
BA_ "MessageSubnet" BO_ 1223 8;
BA_ "GenMsgCycleTime" BO_ 1223 500;
BA_ "GenMsgSendType" BO_ 1223 0;
BA_ "MessageSubnet" BO_ 405 8;
BA_ "GenMsgCycleTime" BO_ 405 20;
BA_ "GenMsgSendType" BO_ 405 0;
BA_ "MessageSubnet" BO_ 311 8;
BA_ "GenMsgCycleTime" BO_ 311 10;
BA_ "GenMsgSendType" BO_ 311 0;
BA_ "Prio" BO_ 403 0;
BA_ "MessageSubnet" BO_ 403 8;
BA_ "GenMsgCycleTime" BO_ 403 20;
BA_ "GenMsgSendType" BO_ 403 0;
BA_ "Prio" BO_ 229 0;
BA_ "MessageSubnet" BO_ 229 8;
BA_ "GenMsgCycleTime" BO_ 229 12;
BA_ "GenMsgSendType" BO_ 229 0;
BA_ "Prio" BO_ 190 0;
BA_ "MessageSubnet" BO_ 190 8;
BA_ "GenMsgCycleTime" BO_ 190 12;
BA_ "GenMsgSendType" BO_ 190 0;
BA_ "Prio" BO_ 288 0;
BA_ "MessageSubnet" BO_ 288 8;
BA_ "GenMsgStartDelayTime" BO_ 288 10;
BA_ "GenMsgCycleTime" BO_ 288 5000;
BA_ "GenMsgSendType" BO_ 288 0;
BA_ "Prio" BO_ 454 0;
BA_ "MessageSubnet" BO_ 454 1;
BA_ "GenMsgCycleTime" BO_ 454 25;
BA_ "GenMsgSendType" BO_ 454 0;
BA_ "Prio" BO_ 209 0;
BA_ "MessageSubnet" BO_ 209 8;
BA_ "GenMsgCycleTime" BO_ 209 10;
BA_ "GenMsgSendType" BO_ 209 0;
BA_ "Prio" BO_ 348 0;
BA_ "MessageSubnet" BO_ 348 8;
BA_ "GenMsgCycleTime" BO_ 348 10;
BA_ "GenMsgSendType" BO_ 348 0;
BA_ "Prio" BO_ 197 0;
BA_ "MessageSubnet" BO_ 197 8;
BA_ "GenMsgCycleTime" BO_ 197 10;
BA_ "GenMsgSendType" BO_ 197 0;
BA_ "Prio" BO_ 500 0;
BA_ "MessageSubnet" BO_ 500 8;
BA_ "GenMsgCycleTime" BO_ 500 25;
BA_ "GenMsgSendType" BO_ 500 0;
BA_ "Prio" BO_ 352 0;
BA_ "MessageSubnet" BO_ 352 8;
BA_ "GenMsgStartDelayTime" BO_ 352 30;
BA_ "GenMsgCycleTime" BO_ 352 100;
BA_ "GenMsgSendType" BO_ 352 0;
BA_ "Prio" BO_ 554 0;
BA_ "MessageSubnet" BO_ 554 8;
BA_ "GenMsgCycleTime" BO_ 554 100;
BA_ "GenMsgSendType" BO_ 554 0;
BA_ "Prio" BO_ 566 0;
BA_ "MessageSubnet" BO_ 566 8;
BA_ "GenMsgCycleTime" BO_ 566 100;
BA_ "GenMsgSendType" BO_ 566 0;
BA_ "Prio" BO_ 1017 0;
BA_ "MessageSubnet" BO_ 1017 8;
BA_ "GenMsgCycleTime" BO_ 1017 250;
BA_ "GenMsgSendType" BO_ 1017 0;
BA_ "Prio" BO_ 401 0;
BA_ "MessageSubnet" BO_ 401 8;
BA_ "GenMsgCycleTime" BO_ 401 20;
BA_ "GenMsgSendType" BO_ 401 0;
BA_ "Prio" BO_ 320 0;
BA_ "MessageSubnet" BO_ 320 8;
BA_ "GenMsgStartDelayTime" BO_ 320 30;
BA_ "GenMsgDelayTime" BO_ 320 10;
BA_ "GenMsgCycleTime" BO_ 320 1000;
BA_ "GenMsgSendType" BO_ 320 0;
BA_ "SignalType" SG_ 1008 SecuredVehSpdSrcDrvn "ENM";
BA_ "SignalLongName" SG_ 1008 SecuredVehSpdSrcDrvn "Secured Vehicle Speed Source Driven ";
BA_ "VNSigAllNodes" SG_ 1008 SecuredVehSpdSrcDrvn 1;
BA_ "SignalType" SG_ 1008 SecuredVehSpdDrvn "UNM";
BA_ "SignalLongName" SG_ 1008 SecuredVehSpdDrvn "Secured Vehicle Speed Driven ";
BA_ "VNSigAllNodes" SG_ 1008 SecuredVehSpdDrvn 1;
BA_ "SignalType" SG_ 1008 SecuredVehSpdChcksm "UNM";
BA_ "SignalLongName" SG_ 1008 SecuredVehSpdChcksm "Secured Vehicle Speed Checksum";
BA_ "VNSigAllNodes" SG_ 1008 SecuredVehSpdChcksm 1;
BA_ "SignalType" SG_ 1008 SecuredVehSpdAvlblDrvn "BLN";
BA_ "SignalLongName" SG_ 1008 SecuredVehSpdAvlblDrvn "Secured Vehicle Speed Available Driven ";
BA_ "VNSigAllNodes" SG_ 1008 SecuredVehSpdAvlblDrvn 1;
BA_ "SignalType" SG_ 1008 SecuredVehSpdARC "UNM";
BA_ "SignalLongName" SG_ 1008 SecuredVehSpdARC "Secured Vehicle Speed Alive Rolling Count";
BA_ "VNSigAllNodes" SG_ 1008 SecuredVehSpdARC 1;
BA_ "SignalType" SG_ 1008 SecuredVehSpdDrvnV "ENM";
BA_ "SignalLongName" SG_ 1008 SecuredVehSpdDrvnV "Secured Vehicle Speed  Driven Validity";
BA_ "VNSigAllNodes" SG_ 1008 SecuredVehSpdDrvnV 1;
BA_ "SignalType" SG_ 647 CrnksftTqModRspMxCapV "ENM";
BA_ "SignalLongName" SG_ 647 CrnksftTqModRspMxCapV "Crankshaft Torque Moderate Response Maximum Capacity Validity";
BA_ "VNSigAllNodes" SG_ 647 CrnksftTqModRspMxCapV 1;
BA_ "SignalType" SG_ 647 CrnksftTqModRspMxCap "UNM";
BA_ "SignalLongName" SG_ 647 CrnksftTqModRspMxCap "Crankshaft Torque Moderate Response Maximum Capacity";
BA_ "VNSigAllNodes" SG_ 647 CrnksftTqModRspMxCap 1;
BA_ "SignalType" SG_ 647 EngDetPndTrnCsRngShfV "ENM";
BA_ "SignalLongName" SG_ 647 EngDetPndTrnCsRngShfV "Engine Determined Pending Transfer Case Range Shift Validity";
BA_ "VNSigAllNodes" SG_ 647 EngDetPndTrnCsRngShfV 1;
BA_ "SignalType" SG_ 647 EngDetPndTrnCsRngShf "ENM";
BA_ "SignalLongName" SG_ 647 EngDetPndTrnCsRngShf "Engine Determined Pending Transfer Case Range Shift";
BA_ "VNSigAllNodes" SG_ 647 EngDetPndTrnCsRngShf 1;
BA_ "SignalType" SG_ 647 CrpCstCrvCmd "ENM";
BA_ "SignalLongName" SG_ 647 CrpCstCrvCmd "Creep Coast Curve Commanded";
BA_ "VNSigAllNodes" SG_ 647 CrpCstCrvCmd 1;
BA_ "SignalType" SG_ 647 DrvMntnMdCmnd "BLN";
BA_ "SignalLongName" SG_ 647 DrvMntnMdCmnd "Driver Mountain Mode Commanded";
BA_ "VNSigAllNodes" SG_ 647 DrvMntnMdCmnd 1;
BA_ "SignalType" SG_ 647 DrvHldMdCmnd "BLN";
BA_ "SignalLongName" SG_ 647 DrvHldMdCmnd "Driver Hold Mode Commanded";
BA_ "VNSigAllNodes" SG_ 647 DrvHldMdCmnd 1;
BA_ "SignalType" SG_ 647 DrPTGrdBrkDsbMdCmd "BLN";
BA_ "SignalLongName" SG_ 647 DrPTGrdBrkDsbMdCmd "Driver Powertrain Grade Braking Disable Mode Commanded";
BA_ "VNSigAllNodes" SG_ 647 DrPTGrdBrkDsbMdCmd 1;
BA_ "SignalType" SG_ 647 DrvWntrMdCmd "BLN";
BA_ "SignalLongName" SG_ 647 DrvWntrMdCmd "Driver Winter Mode Commanded";
BA_ "VNSigAllNodes" SG_ 647 DrvWntrMdCmd 1;
BA_ "SignalType" SG_ 647 DrvTwHaulMdCmd "BLN";
BA_ "SignalLongName" SG_ 647 DrvTwHaulMdCmd "Driver Tow Haul Mode Commanded";
BA_ "VNSigAllNodes" SG_ 647 DrvTwHaulMdCmd 1;
BA_ "SignalType" SG_ 647 DrvSprtMdCmd "BLN";
BA_ "SignalLongName" SG_ 647 DrvSprtMdCmd "Driver Sport Mode Commanded";
BA_ "VNSigAllNodes" SG_ 647 DrvSprtMdCmd 1;
BA_ "SignalType" SG_ 647 DrvEconMdCmd "BLN";
BA_ "SignalLongName" SG_ 647 DrvEconMdCmd "Driver Economy Mode Commanded";
BA_ "VNSigAllNodes" SG_ 647 DrvEconMdCmd 1;
BA_ "SignalType" SG_ 647 EngCntrlDtrmdTrfCRngV "ENM";
BA_ "SignalLongName" SG_ 647 EngCntrlDtrmdTrfCRngV "Engine Controller Determined Transfer Case Range Validity";
BA_ "VNSigAllNodes" SG_ 647 EngCntrlDtrmdTrfCRngV 1;
BA_ "SignalType" SG_ 647 EngCntrlDtrmdTrfCRng "ENM";
BA_ "SignalLongName" SG_ 647 EngCntrlDtrmdTrfCRng "Engine Controller Determined Transfer Case Range";
BA_ "VNSigAllNodes" SG_ 647 EngCntrlDtrmdTrfCRng 1;
BA_ "SignalType" SG_ 647 EngCtrlUtldTrnCRgPVal "UNM";
BA_ "SignalLongName" SG_ 647 EngCtrlUtldTrnCRgPVal "Engine Controller Utilized Transfer Case Range Protection Value";
BA_ "VNSigAllNodes" SG_ 647 EngCtrlUtldTrnCRgPVal 1;
BA_ "SignalType" SG_ 647 EngCntrlUtldTrnCsRng "ENM";
BA_ "SignalLongName" SG_ 647 EngCntrlUtldTrnCsRng "Engine Controller Utilized Transfer Case Range";
BA_ "VNSigAllNodes" SG_ 647 EngCntrlUtldTrnCsRng 1;
BA_ "SignalType" SG_ 647 EngCntrlUtldTrnCsRgIn "BLN";
BA_ "SignalLongName" SG_ 647 EngCntrlUtldTrnCsRgIn "Engine Controller Utilized Transfer Case Range Inconsistent";
BA_ "VNSigAllNodes" SG_ 647 EngCntrlUtldTrnCsRgIn 1;
BA_ "SignalType" SG_ 647 EngCtrlUtldTrnCRgARC "UNM";
BA_ "SignalLongName" SG_ 647 EngCtrlUtldTrnCRgARC "Engine Controller Utilized Transfer Case Range Alive Rolling Count";
BA_ "VNSigAllNodes" SG_ 647 EngCtrlUtldTrnCRgARC 1;
BA_ "SignalType" SG_ 170 EngCommFlrRedPwrCm "BLN";
BA_ "SignalLongName" SG_ 170 EngCommFlrRedPwrCm "Engine Communication Failure Reduced Power Commanded";
BA_ "VNSigAllNodes" SG_ 170 EngCommFlrRedPwrCm 1;
BA_ "SignalType" SG_ 170 CmndAxlTrqARC "UNM";
BA_ "SignalLongName" SG_ 170 CmndAxlTrqARC "Commanded Axle Torque Alive Rolling Count";
BA_ "VNSigAllNodes" SG_ 170 CmndAxlTrqARC 1;
BA_ "SignalType" SG_ 170 CmndAxlTrqRespTyp "ENM";
BA_ "SignalLongName" SG_ 170 CmndAxlTrqRespTyp "Commanded Axle Torque Response Type";
BA_ "VNSigAllNodes" SG_ 170 CmndAxlTrqRespTyp 1;
BA_ "SignalType" SG_ 170 CmndAxlTrqImm "UNM";
BA_ "SignalLongName" SG_ 170 CmndAxlTrqImm "Commanded Axle Torque Immediate";
BA_ "VNSigAllNodes" SG_ 170 CmndAxlTrqImm 1;
BA_ "SignalType" SG_ 170 AccPos "UNM";
BA_ "SignalLongName" SG_ 170 AccPos "Accelerator Effective Position";
BA_ "VNSigAllNodes" SG_ 170 AccPos 1;
BA_ "SignalType" SG_ 170 CmndAxlTrqPredct "UNM";
BA_ "SignalLongName" SG_ 170 CmndAxlTrqPredct "Commanded Axle Torque Predicted";
BA_ "VNSigAllNodes" SG_ 170 CmndAxlTrqPredct 1;
BA_ "SignalType" SG_ 170 CmndAxlTrqPredctProtVal "UNM";
BA_ "SignalLongName" SG_ 170 CmndAxlTrqPredctProtVal "Commanded Axle Torque Predicted Protection Value";
BA_ "VNSigAllNodes" SG_ 170 CmndAxlTrqPredctProtVal 1;
BA_ "SignalType" SG_ 1105 HybImpSnsDsbld "BLN";
BA_ "SignalLongName" SG_ 1105 HybImpSnsDsbld "Hybrid Impact Sensing Disabled";
BA_ "VNSigAllNodes" SG_ 1105 HybImpSnsDsbld 1;
BA_ "SignalType" SG_ 1105 JmpStrtReq "BLN";
BA_ "SignalLongName" SG_ 1105 JmpStrtReq "Jump Start Requested";
BA_ "VNSigAllNodes" SG_ 1105 JmpStrtReq 1;
BA_ "SignalType" SG_ 1105 HybVehHiVltInvDisRqd "BLN";
BA_ "SignalLongName" SG_ 1105 HybVehHiVltInvDisRqd "Hybrid Vehicle High Voltage Inverter Disable Requested";
BA_ "VNSigAllNodes" SG_ 1105 HybVehHiVltInvDisRqd 1;
BA_ "SignalType" SG_ 1105 NESSRoSevSt "BLN";
BA_ "PacketOrder" SG_ 1105 NESSRoSevSt 7;
BA_ "SignalLongName" SG_ 1105 NESSRoSevSt "Notification Event Severity Status : Rollover Severity Achieved";
BA_ "VNSigAllNodes" SG_ 1105 NESSRoSevSt 1;
BA_ "SignalType" SG_ 1105 NESSRiSiSevSt "BLN";
BA_ "PacketOrder" SG_ 1105 NESSRiSiSevSt 6;
BA_ "SignalLongName" SG_ 1105 NESSRiSiSevSt "Notification Event Severity Status : Right Side Severity Achieved";
BA_ "VNSigAllNodes" SG_ 1105 NESSRiSiSevSt 1;
BA_ "SignalType" SG_ 1105 NESSReImpSevSt "BLN";
BA_ "PacketOrder" SG_ 1105 NESSReImpSevSt 5;
BA_ "SignalLongName" SG_ 1105 NESSReImpSevSt "Notification Event Severity Status : Rear Impact Severity Achieved";
BA_ "VNSigAllNodes" SG_ 1105 NESSReImpSevSt 1;
BA_ "SignalType" SG_ 1105 NESSLeSiSevSt "BLN";
BA_ "PacketOrder" SG_ 1105 NESSLeSiSevSt 4;
BA_ "SignalLongName" SG_ 1105 NESSLeSiSevSt "Notification Event Severity Status : Left Side Severity Achieved";
BA_ "VNSigAllNodes" SG_ 1105 NESSLeSiSevSt 1;
BA_ "SignalType" SG_ 1105 NESSFrImpSt2SevSt "BLN";
BA_ "PacketOrder" SG_ 1105 NESSFrImpSt2SevSt 3;
BA_ "SignalLongName" SG_ 1105 NESSFrImpSt2SevSt "Notification Event Severity Status : Frontal Impact Stage 2 Severity Achieved";
BA_ "VNSigAllNodes" SG_ 1105 NESSFrImpSt2SevSt 1;
BA_ "SignalType" SG_ 1105 NESSFrImpSt1SevSt "BLN";
BA_ "PacketOrder" SG_ 1105 NESSFrImpSt1SevSt 2;
BA_ "SignalLongName" SG_ 1105 NESSFrImpSt1SevSt "Notification Event Severity Status : Frontal Impact Stage 1 Severity Achieved";
BA_ "VNSigAllNodes" SG_ 1105 NESSFrImpSt1SevSt 1;
BA_ "SignalType" SG_ 1105 NESSFrImpPreSevSt "BLN";
BA_ "PacketOrder" SG_ 1105 NESSFrImpPreSevSt 1;
BA_ "SignalLongName" SG_ 1105 NESSFrImpPreSevSt "Notification Event Severity Status : Frontal Impact Pretensioner Severity Achieved";
BA_ "VNSigAllNodes" SG_ 1105 NESSFrImpPreSevSt 1;
BA_ "SignalType" SG_ 1105 ClmCntFrBlwFnSp "UNM";
BA_ "SignalLongName" SG_ 1105 ClmCntFrBlwFnSp "Climate Control Front Blower Fan Speed";
BA_ "VNSigAllNodes" SG_ 1105 ClmCntFrBlwFnSp 1;
BA_ "PacketOrder" SG_ 872 ESBR_AutoBrkgRqTyp 2;
BA_ "SignalType" SG_ 872 ESBR_AutoBrkgRqTyp "ENM";
BA_ "SignalLongName" SG_ 872 ESBR_AutoBrkgRqTyp "Electronic Shift Braking Request : Automatic Braking Request Type";
BA_ "VNSigAllNodes" SG_ 872 ESBR_AutoBrkgRqTyp 1;
BA_ "PacketOrder" SG_ 872 ESBR_AutoBrkgRqd 1;
BA_ "SignalType" SG_ 872 ESBR_AutoBrkgRqd "ENM";
BA_ "SignalLongName" SG_ 872 ESBR_AutoBrkgRqd "Electronic Shift Braking Request : Automatic Braking Requested";
BA_ "VNSigAllNodes" SG_ 872 ESBR_AutoBrkgRqd 1;
BA_ "SignalType" SG_ 872 ElcShftBrkgRqPVal "UNM";
BA_ "SignalLongName" SG_ 872 ElcShftBrkgRqPVal "Electronic Shift Braking Request Protection Value";
BA_ "VNSigAllNodes" SG_ 872 ElcShftBrkgRqPVal 1;
BA_ "SignalType" SG_ 872 ElcShftBrkgRqARC "UNM";
BA_ "SignalLongName" SG_ 872 ElcShftBrkgRqARC "Electronic Shift Braking Request Alive Rolling Count";
BA_ "VNSigAllNodes" SG_ 872 ElcShftBrkgRqARC 1;
BA_ "SignalType" SG_ 1223 PropSysOffTmeV "ENM";
BA_ "SignalLongName" SG_ 1223 PropSysOffTmeV "Propulsion System Off Time Validity";
BA_ "VNSigAllNodes" SG_ 1223 PropSysOffTmeV 1;
BA_ "SignalType" SG_ 1223 PropSysOffTmeM "ENM";
BA_ "SignalLongName" SG_ 1223 PropSysOffTmeM "Propulsion System Off Time Mask";
BA_ "VNSigAllNodes" SG_ 1223 PropSysOffTmeM 1;
BA_ "SignalType" SG_ 1223 PropSysOffTme "UNM";
BA_ "SignalLongName" SG_ 1223 PropSysOffTme "Propulsion System Off Time";
BA_ "VNSigAllNodes" SG_ 1223 PropSysOffTme 1;
BA_ "SignalType" SG_ 405 EstWhlBrkPrsStat "ENM";
BA_ "SignalLongName" SG_ 405 EstWhlBrkPrsStat "Estimated Wheel Brake Pressure Status";
BA_ "VNSigAllNodes" SG_ 405 EstWhlBrkPrsStat 1;
BA_ "SignalType" SG_ 405 EstWhlBrkPrsRR "UNM";
BA_ "SignalLongName" SG_ 405 EstWhlBrkPrsRR "Estimated Wheel Brake Pressure Right Rear";
BA_ "VNSigAllNodes" SG_ 405 EstWhlBrkPrsRR 1;
BA_ "SignalType" SG_ 405 EstWhlBrkPrsLR "UNM";
BA_ "SignalLongName" SG_ 405 EstWhlBrkPrsLR "Estimated Wheel Brake Pressure Left Rear";
BA_ "VNSigAllNodes" SG_ 405 EstWhlBrkPrsLR 1;
BA_ "SignalType" SG_ 405 EstWhlBrkPrsRF "UNM";
BA_ "SignalLongName" SG_ 405 EstWhlBrkPrsRF "Estimated Wheel Brake Pressure Right Front";
BA_ "VNSigAllNodes" SG_ 405 EstWhlBrkPrsRF 1;
BA_ "SignalType" SG_ 405 EstWhlBrkPrsLF "UNM";
BA_ "SignalLongName" SG_ 405 EstWhlBrkPrsLF "Estimated Wheel Brake Pressure Left Front";
BA_ "VNSigAllNodes" SG_ 405 EstWhlBrkPrsLF 1;
BA_ "SignalType" SG_ 405 BrkEstWhlPrsChksm "UNM";
BA_ "SignalLongName" SG_ 405 BrkEstWhlPrsChksm "Brake Estimated Wheel Pressure Checksum";
BA_ "VNSigAllNodes" SG_ 405 BrkEstWhlPrsChksm 1;
BA_ "SignalType" SG_ 405 BrkEstWhlPrsARC "UNM";
BA_ "SignalLongName" SG_ 405 BrkEstWhlPrsARC "Brake Estimated Wheel Pressure Alive Rolling Count";
BA_ "VNSigAllNodes" SG_ 405 BrkEstWhlPrsARC 1;
BA_ "SignalType" SG_ 311 PriCoPCmdMsgStatRed "ENM";
BA_ "SignalLongName" SG_ 311 PriCoPCmdMsgStatRed "Primary CoPilot Command Message Status Redundant";
BA_ "VNSigAllNodes" SG_ 311 PriCoPCmdMsgStatRed 1;
BA_ "SignalType" SG_ 311 PriADSCmdMsgStatRed "ENM";
BA_ "SignalLongName" SG_ 311 PriADSCmdMsgStatRed "Primary ADS Command Message Status Redundant";
BA_ "VNSigAllNodes" SG_ 311 PriADSCmdMsgStatRed 1;
BA_ "SignalType" SG_ 311 PriBrkSysArbStatRed "ENM";
BA_ "SignalLongName" SG_ 311 PriBrkSysArbStatRed "Primary Brake System Arbitration Status Redundant";
BA_ "VNSigAllNodes" SG_ 311 PriBrkSysArbStatRed 1;
BA_ "SignalType" SG_ 311 PriBrkSysStatRedChksm "UNM";
BA_ "SignalLongName" SG_ 311 PriBrkSysStatRedChksm "Primary Brake System Status Redundant Checksum";
BA_ "VNSigAllNodes" SG_ 311 PriBrkSysStatRedChksm 1;
BA_ "SignalType" SG_ 311 PriBrkSysStatRedARC "UNM";
BA_ "SignalLongName" SG_ 311 PriBrkSysStatRedARC "Primary Brake System Status Redundant Alive Rolling Count";
BA_ "VNSigAllNodes" SG_ 311 PriBrkSysStatRedARC 1;
BA_ "SignalType" SG_ 311 PriBrkModSbSteRed "ENM";
BA_ "SignalLongName" SG_ 311 PriBrkModSbSteRed "Primary Brake Module Sub State Redundant";
BA_ "VNSigAllNodes" SG_ 311 PriBrkModSbSteRed 1;
BA_ "SignalType" SG_ 311 PriBrkSysStatRed "ENM";
BA_ "SignalLongName" SG_ 311 PriBrkSysStatRed "Primary Brake System Status Redundant";
BA_ "VNSigAllNodes" SG_ 311 PriBrkSysStatRed 1;
BA_ "SignalType" SG_ 311 PriBrkRngLmtgStatRed "ENM";
BA_ "SignalLongName" SG_ 311 PriBrkRngLmtgStatRed "Primary Brake Range Limiting Status Redundant";
BA_ "VNSigAllNodes" SG_ 311 PriBrkRngLmtgStatRed 1;
BA_ "SignalType" SG_ 311 ActrBrkFldFlwReq "UNM";
BA_ "SignalLongName" SG_ 311 ActrBrkFldFlwReq "Actuator Brake Fluid Flow Request";
BA_ "GenSigStartValue" SG_ 311 ActrBrkFldFlwReq 32768;
BA_ "VNSigAllNodes" SG_ 311 ActrBrkFldFlwReq 1;
BA_ "SignalType" SG_ 311 ActrBrkFldFlwReqStat "ENM";
BA_ "SignalLongName" SG_ 311 ActrBrkFldFlwReqStat "Actuator Brake Fluid Flow Request Status";
BA_ "VNSigAllNodes" SG_ 311 ActrBrkFldFlwReqStat 1;
BA_ "SignalType" SG_ 311 ABSAtv "BLN";
BA_ "SignalLongName" SG_ 311 ABSAtv "Antilock Brake System Active";
BA_ "VNSigAllNodes" SG_ 311 ABSAtv 1;
BA_ "SignalType" SG_ 311 PriBrkModCrtThrmlCapRed "UNM";
BA_ "SignalLongName" SG_ 311 PriBrkModCrtThrmlCapRed "Primary Brake Module Current Thermal Capacity Redundant";
BA_ "VNSigAllNodes" SG_ 311 PriBrkModCrtThrmlCapRed 1;
BA_ "SignalType" SG_ 311 EBCMhydctrlActRed "BLN";
BA_ "SignalLongName" SG_ 311 EBCMhydctrlActRed "EBCM Hydraulic Control Active Redundant ";
BA_ "VNSigAllNodes" SG_ 311 EBCMhydctrlActRed 1;
BA_ "SignalType" SG_ 311 PriDrvIntvtnMdDetTORed "BLN";
BA_ "SignalLongName" SG_ 311 PriDrvIntvtnMdDetTORed "Primary Driver Intervention Mode Detection Timeout Redundant";
BA_ "VNSigAllNodes" SG_ 311 PriDrvIntvtnMdDetTORed 1;
BA_ "SignalType" SG_ 403 SpltMuCntrlV "ENM";
BA_ "SignalLongName" SG_ 403 SpltMuCntrlV "Split Mu Control Validity";
BA_ "VNSigAllNodes" SG_ 403 SpltMuCntrlV 1;
BA_ "SignalType" SG_ 403 SpltMuCntrl "ENM";
BA_ "SignalLongName" SG_ 403 SpltMuCntrl "Split Mu Control";
BA_ "VNSigAllNodes" SG_ 403 SpltMuCntrl 1;
BA_ "SignalType" SG_ 403 PriBrkModCapStat "ENM";
BA_ "SignalLongName" SG_ 403 PriBrkModCapStat "Primary Brake Module Capability Status";
BA_ "VNSigAllNodes" SG_ 403 PriBrkModCapStat 1;
BA_ "SignalType" SG_ 403 PriMaxAvlBrkTrqGrad "UNM";
BA_ "SignalLongName" SG_ 403 PriMaxAvlBrkTrqGrad "Primary Maximum Available Brake Torque Gradient";
BA_ "VNSigAllNodes" SG_ 403 PriMaxAvlBrkTrqGrad 1;
BA_ "SignalType" SG_ 403 PriMaxAvlBrkTrq "UNM";
BA_ "SignalLongName" SG_ 403 PriMaxAvlBrkTrq "Primary Maximum Available Brake Torque";
BA_ "GenSigStartValue" SG_ 403 PriMaxAvlBrkTrq 32767;
BA_ "VNSigAllNodes" SG_ 403 PriMaxAvlBrkTrq 1;
BA_ "SignalType" SG_ 403 PriEstSrfcMuTyp "ENM";
BA_ "SignalLongName" SG_ 403 PriEstSrfcMuTyp "Primary Estimated Surface Mu Type";
BA_ "VNSigAllNodes" SG_ 403 PriEstSrfcMuTyp 1;
BA_ "SignalType" SG_ 403 PriEstSrfcMuCap "UNM";
BA_ "SignalLongName" SG_ 403 PriEstSrfcMuCap "Primary Estimated Surface Mu Capacity";
BA_ "VNSigAllNodes" SG_ 403 PriEstSrfcMuCap 1;
BA_ "SignalType" SG_ 403 PriBrkSystCapChksm "UNM";
BA_ "SignalLongName" SG_ 403 PriBrkSystCapChksm "Primary Brake System Capability Checksum";
BA_ "VNSigAllNodes" SG_ 403 PriBrkSystCapChksm 1;
BA_ "SignalType" SG_ 403 PriBrkSysCapARC "UNM";
BA_ "SignalLongName" SG_ 403 PriBrkSysCapARC "Primary Brake System Capability Alive Rolling Count";
BA_ "VNSigAllNodes" SG_ 403 PriBrkSysCapARC 1;
BA_ "SignalType" SG_ 229 AutoPriAxlPropTrqStatChksm "UNM";
BA_ "SignalLongName" SG_ 229 AutoPriAxlPropTrqStatChksm "Autonomous Primary Axle Propulsion Torque Status Checksum";
BA_ "VNSigAllNodes" SG_ 229 AutoPriAxlPropTrqStatChksm 1;
BA_ "SignalType" SG_ 229 AutoRedAxlTrqStat "ENM";
BA_ "SignalLongName" SG_ 229 AutoRedAxlTrqStat "Autonomous Redundant Axle Torque Status";
BA_ "VNSigAllNodes" SG_ 229 AutoRedAxlTrqStat 1;
BA_ "SignalType" SG_ 229 AATPCS_PropRngLmtgStat "ENM";
BA_ "SignalLongName" SG_ 229 AATPCS_PropRngLmtgStat "Autonomous Axle Torque Propulsion Capability Status: Propulsion Range Limiting Status";
BA_ "VNSigAllNodes" SG_ 229 AATPCS_PropRngLmtgStat 1;
BA_ "SignalType" SG_ 229 AATPCS_PropSysStat "ENM";
BA_ "SignalLongName" SG_ 229 AATPCS_PropSysStat "Autonomous Axle Torque Propulsion Capability Status: Propulsion System Status";
BA_ "VNSigAllNodes" SG_ 229 AATPCS_PropSysStat 1;
BA_ "SignalType" SG_ 229 AutoActAxleTrqARC "UNM";
BA_ "SignalLongName" SG_ 229 AutoActAxleTrqARC "Autonomous Actual Axle Torque Alive Rolling Count";
BA_ "VNSigAllNodes" SG_ 229 AutoActAxleTrqARC 1;
BA_ "SignalType" SG_ 229 CpAxlTrqReqStat "ENM";
BA_ "SignalLongName" SG_ 229 CpAxlTrqReqStat "CoPilot Axle Torque Request Status";
BA_ "VNSigAllNodes" SG_ 229 CpAxlTrqReqStat 1;
BA_ "SignalType" SG_ 229 AutoPriAxlTrqStat "ENM";
BA_ "SignalLongName" SG_ 229 AutoPriAxlTrqStat "Autonomous Primary Axle Torque Status";
BA_ "VNSigAllNodes" SG_ 229 AutoPriAxlTrqStat 1;
BA_ "SignalType" SG_ 229 AutoPropAxlTrqArbStat "ENM";
BA_ "SignalLongName" SG_ 229 AutoPropAxlTrqArbStat "Autonomous Propulsion Axle Torque Arbitration Status";
BA_ "VNSigAllNodes" SG_ 229 AutoPropAxlTrqArbStat 1;
BA_ "SignalType" SG_ 229 AutoActAxleTrqV "ENM";
BA_ "SignalLongName" SG_ 229 AutoActAxleTrqV "Autonomous Actual Axle Torque Validity";
BA_ "VNSigAllNodes" SG_ 229 AutoActAxleTrqV 1;
BA_ "SignalType" SG_ 229 AutoActAxleTrq "UNM";
BA_ "SignalLongName" SG_ 229 AutoActAxleTrq "Autonomous Actual Axle Torque";
BA_ "GenSigStartValue" SG_ 229 AutoActAxleTrq 11267;
BA_ "VNSigAllNodes" SG_ 229 AutoActAxleTrq 1;
BA_ "SignalType" SG_ 229 AutoPropSysDrInfcDtd "BLN";
BA_ "SignalLongName" SG_ 229 AutoPropSysDrInfcDtd "Autonomous Propulsion System Driver Interference Detected";
BA_ "VNSigAllNodes" SG_ 229 AutoPropSysDrInfcDtd 1;
BA_ "SignalType" SG_ 190 EngSpdMaxCapRdcdRng "UNM";
BA_ "SignalLongName" SG_ 190 EngSpdMaxCapRdcdRng "Engine Speed Maximum Capacity Reduced Range";
BA_ "VNSigAllNodes" SG_ 190 EngSpdMaxCapRdcdRng 1;
BA_ "SignalType" SG_ 190 PTSnsdBrkPdlInfPVal "UNM";
BA_ "SignalLongName" SG_ 190 PTSnsdBrkPdlInfPVal "Powertrain Sensed Brake Pedal Information Protection Value";
BA_ "VNSigAllNodes" SG_ 190 PTSnsdBrkPdlInfPVal 1;
BA_ "SignalType" SG_ 190 TrnsAuxPmpAct "BLN";
BA_ "SignalLongName" SG_ 190 TrnsAuxPmpAct "Transmission Auxiliary Pump Active";
BA_ "VNSigAllNodes" SG_ 190 TrnsAuxPmpAct 1;
BA_ "SignalType" SG_ 190 AccPos "UNM";
BA_ "SignalLongName" SG_ 190 AccPos "Accelerator Effective Position";
BA_ "VNSigAllNodes" SG_ 190 AccPos 1;
BA_ "SignalType" SG_ 190 PTSnsdBrkPdlInfARC "UNM";
BA_ "SignalLongName" SG_ 190 PTSnsdBrkPdlInfARC "Powertrain Sensed Brake Pedal Information Alive Rolling Count";
BA_ "VNSigAllNodes" SG_ 190 PTSnsdBrkPdlInfARC 1;
BA_ "SignalType" SG_ 190 PSBPI_PTSnBrkPdlPsV "ENM";
BA_ "PacketOrder" SG_ 190 PSBPI_PTSnBrkPdlPsV 1;
BA_ "SignalLongName" SG_ 190 PSBPI_PTSnBrkPdlPsV "Powertrain Sensed Brake Pedal Information : Powertrain Sensed Brake Pedal Position Validity";
BA_ "VNSigAllNodes" SG_ 190 PSBPI_PTSnBrkPdlPsV 1;
BA_ "SignalType" SG_ 190 PSBPI_PTSnBrkPdlPs "UNM";
BA_ "PacketOrder" SG_ 190 PSBPI_PTSnBrkPdlPs 2;
BA_ "SignalLongName" SG_ 190 PSBPI_PTSnBrkPdlPs "Powertrain Sensed Brake Pedal Information : Powertrain Sensed Brake Pedal Position";
BA_ "VNSigAllNodes" SG_ 190 PSBPI_PTSnBrkPdlPs 1;
BA_ "SignalType" SG_ 288 VehOdo "UNM";
BA_ "SignalLongName" SG_ 288 VehOdo "Vehicle Odometer";
BA_ "VNSigAllNodes" SG_ 288 VehOdo 1;
BA_ "SignalType" SG_ 288 VehOdoV "ENM";
BA_ "SignalLongName" SG_ 288 VehOdoV "Vehicle Odometer Validity";
BA_ "VNSigAllNodes" SG_ 288 VehOdoV 1;
BA_ "SignalType" SG_ 454 APAAxlTrqRdctnAct "BLN";
BA_ "SignalLongName" SG_ 454 APAAxlTrqRdctnAct "Advanced Park Assist Axle Torque Reduction Active";
BA_ "VNSigAllNodes" SG_ 454 APAAxlTrqRdctnAct 1;
BA_ "SignalType" SG_ 454 ChsSysPrdAxlTqRqPV "UNM";
BA_ "SignalLongName" SG_ 454 ChsSysPrdAxlTqRqPV "Chassis System Predicted Axle Torque Request Protection Value";
BA_ "VNSigAllNodes" SG_ 454 ChsSysPrdAxlTqRqPV 1;
BA_ "SignalType" SG_ 454 CSPATR_TrqIntrvnTyp "ENM";
BA_ "PacketOrder" SG_ 454 CSPATR_TrqIntrvnTyp 3;
BA_ "SignalLongName" SG_ 454 CSPATR_TrqIntrvnTyp "Chassis System Predicted Axle Torque Request : Torque Intervention Type";
BA_ "VNSigAllNodes" SG_ 454 CSPATR_TrqIntrvnTyp 1;
BA_ "SignalType" SG_ 454 CSPATR_PrdTrqRqVal "UNM";
BA_ "PacketOrder" SG_ 454 CSPATR_PrdTrqRqVal 2;
BA_ "SignalLongName" SG_ 454 CSPATR_PrdTrqRqVal "Chassis System Predicted Axle Torque Request : Predicted Torque Request Value";
BA_ "VNSigAllNodes" SG_ 454 CSPATR_PrdTrqRqVal 1;
BA_ "SignalType" SG_ 454 CSPATR_TrqRqTyp "ENM";
BA_ "PacketOrder" SG_ 454 CSPATR_TrqRqTyp 1;
BA_ "SignalLongName" SG_ 454 CSPATR_TrqRqTyp "Chassis System Predicted Axle Torque Request : Torque Request Type";
BA_ "VNSigAllNodes" SG_ 454 CSPATR_TrqRqTyp 1;
BA_ "SignalType" SG_ 454 ChsSysImmAxlTqRqVal "UNM";
BA_ "SignalLongName" SG_ 454 ChsSysImmAxlTqRqVal "Chassis System Immediate Axle Torque Request Value";
BA_ "VNSigAllNodes" SG_ 454 ChsSysImmAxlTqRqVal 1;
BA_ "SignalType" SG_ 454 ChsSysAxlTqRqRspTyp "ENM";
BA_ "SignalLongName" SG_ 454 ChsSysAxlTqRqRspTyp "Chassis System Axle Torque Request Response Type";
BA_ "VNSigAllNodes" SG_ 454 ChsSysAxlTqRqRspTyp 1;
BA_ "SignalType" SG_ 454 ChsSysPrdAxlTqRqARC "UNM";
BA_ "SignalLongName" SG_ 454 ChsSysPrdAxlTqRqARC "Chassis System Predicted Axle Torque Request Alive Rolling Count";
BA_ "VNSigAllNodes" SG_ 454 ChsSysPrdAxlTqRqARC 1;
BA_ "SignalType" SG_ 209 ChsBrkPdlPsERltdV "ENM";
BA_ "SignalLongName" SG_ 209 ChsBrkPdlPsERltdV "Chassis Brake Pedal Position Emissions Related Validity";
BA_ "VNSigAllNodes" SG_ 209 ChsBrkPdlPsERltdV 1;
BA_ "SignalType" SG_ 209 ChsBrkPdlPsERltdPVal "UNM";
BA_ "SignalLongName" SG_ 209 ChsBrkPdlPsERltdPVal "Chassis Brake Pedal Position Emissions Related Protection Value";
BA_ "VNSigAllNodes" SG_ 209 ChsBrkPdlPsERltdPVal 1;
BA_ "SignalType" SG_ 209 ChsBrkPdlPsERltdARC "UNM";
BA_ "SignalLongName" SG_ 209 ChsBrkPdlPsERltdARC "Chassis Brake Pedal Position Emissions Related Alive Rolling Count";
BA_ "VNSigAllNodes" SG_ 209 ChsBrkPdlPsERltdARC 1;
BA_ "SignalType" SG_ 209 ChsBrkPdlPsERltd "UNM";
BA_ "SignalLongName" SG_ 209 ChsBrkPdlPsERltd "Chassis Brake Pedal Position Emissions Related";
BA_ "VNSigAllNodes" SG_ 209 ChsBrkPdlPsERltd 1;
BA_ "SignalType" SG_ 209 DrvIntndTtlBrkTrqPVal "UNM";
BA_ "SignalLongName" SG_ 209 DrvIntndTtlBrkTrqPVal "Driver Intended Total Brake Torque Protection Value";
BA_ "VNSigAllNodes" SG_ 209 DrvIntndTtlBrkTrqPVal 1;
BA_ "SignalType" SG_ 209 DrvIntndTtlBrkTrqARC "UNM";
BA_ "SignalLongName" SG_ 209 DrvIntndTtlBrkTrqARC "Driver Intended Total Brake Torque Alive Rolling Count";
BA_ "VNSigAllNodes" SG_ 209 DrvIntndTtlBrkTrqARC 1;
BA_ "SignalType" SG_ 209 DrvIntndTtlBrkTrq "UNM";
BA_ "SignalLongName" SG_ 209 DrvIntndTtlBrkTrq "Driver Intended Total Brake Torque";
BA_ "VNSigAllNodes" SG_ 209 DrvIntndTtlBrkTrq 1;
BA_ "SignalType" SG_ 348 SecCoPCmdMsgStat "ENM";
BA_ "SignalLongName" SG_ 348 SecCoPCmdMsgStat "Secondary CoPilot Command Message Status";
BA_ "VNSigAllNodes" SG_ 348 SecCoPCmdMsgStat 1;
BA_ "SignalType" SG_ 348 SecBrkSysArbStat "ENM";
BA_ "SignalLongName" SG_ 348 SecBrkSysArbStat "Secondary Brake System Arbitration Status";
BA_ "VNSigAllNodes" SG_ 348 SecBrkSysArbStat 1;
BA_ "SignalType" SG_ 348 SecADSCmdMsgStat "ENM";
BA_ "SignalLongName" SG_ 348 SecADSCmdMsgStat "Secondary ADS Command Message Status";
BA_ "VNSigAllNodes" SG_ 348 SecADSCmdMsgStat 1;
BA_ "SignalType" SG_ 348 StrkOtptRodTgtQlfr "ENM";
BA_ "SignalLongName" SG_ 348 StrkOtptRodTgtQlfr "Stroke Output Rod Target Qualifier";
BA_ "VNSigAllNodes" SG_ 348 StrkOtptRodTgtQlfr 1;
BA_ "SignalType" SG_ 348 StrkOtptRodTgt "UNM";
BA_ "SignalLongName" SG_ 348 StrkOtptRodTgt "Stroke Output Rod Target";
BA_ "VNSigAllNodes" SG_ 348 StrkOtptRodTgt 1;
BA_ "SignalType" SG_ 348 StrkOtptRodActlQlfr "ENM";
BA_ "SignalLongName" SG_ 348 StrkOtptRodActlQlfr "Stroke Output Rod Actual Qualifier";
BA_ "VNSigAllNodes" SG_ 348 StrkOtptRodActlQlfr 1;
BA_ "SignalType" SG_ 348 StrkOtptRodActl "UNM";
BA_ "SignalLongName" SG_ 348 StrkOtptRodActl "Stroke Output Rod Actual";
BA_ "VNSigAllNodes" SG_ 348 StrkOtptRodActl 1;
BA_ "SignalType" SG_ 348 SecBrkSysStatChksm "UNM";
BA_ "SignalLongName" SG_ 348 SecBrkSysStatChksm "Seconday Brake System Status Checksum";
BA_ "VNSigAllNodes" SG_ 348 SecBrkSysStatChksm 1;
BA_ "SignalType" SG_ 348 SecBrkSysStatARC "UNM";
BA_ "SignalLongName" SG_ 348 SecBrkSysStatARC "Seconday Brake System Status Alive Rolling Count";
BA_ "VNSigAllNodes" SG_ 348 SecBrkSysStatARC 1;
BA_ "SignalType" SG_ 348 SecBrkModSbSte "ENM";
BA_ "SignalLongName" SG_ 348 SecBrkModSbSte "Secondary Brake Module Sub State";
BA_ "VNSigAllNodes" SG_ 348 SecBrkModSbSte 1;
BA_ "SignalType" SG_ 348 SecBrkSysStat "ENM";
BA_ "SignalLongName" SG_ 348 SecBrkSysStat "Secondary Brake System Status";
BA_ "VNSigAllNodes" SG_ 348 SecBrkSysStat 1;
BA_ "SignalType" SG_ 348 SecBrkRngLmtgStat "ENM";
BA_ "SignalLongName" SG_ 348 SecBrkRngLmtgStat "Secondary Brake Range Limiting Status";
BA_ "VNSigAllNodes" SG_ 348 SecBrkRngLmtgStat 1;
BA_ "SignalType" SG_ 348 SecBrkModCrtThrmlCap "UNM";
BA_ "SignalLongName" SG_ 348 SecBrkModCrtThrmlCap "Secondary Brake Module Current Thermal Capacity";
BA_ "VNSigAllNodes" SG_ 348 SecBrkModCrtThrmlCap 1;
BA_ "SignalType" SG_ 348 SecDrvIntvtnMdDetTO "BLN";
BA_ "SignalLongName" SG_ 348 SecDrvIntvtnMdDetTO "Secondary Driver Intervention Mode Detection Timeout";
BA_ "VNSigAllNodes" SG_ 348 SecDrvIntvtnMdDetTO 1;
BA_ "SignalType" SG_ 197 WRSLNDWhlDisTpRC "UNM";
BA_ "PacketOrder" SG_ 197 WRSLNDWhlDisTpRC 1;
BA_ "SignalLongName" SG_ 197 WRSLNDWhlDisTpRC "Wheel Rotational Status Left Non Driven : Wheel Distance Timestamp Rollover Counter";
BA_ "VNSigAllNodes" SG_ 197 WRSLNDWhlDisTpRC 1;
BA_ "SignalType" SG_ 197 WRSLNDWhlRotStRst "BLN";
BA_ "PacketOrder" SG_ 197 WRSLNDWhlRotStRst 3;
BA_ "SignalLongName" SG_ 197 WRSLNDWhlRotStRst "Wheel Rotational Status Left Non Driven : Wheel Rotational Status Reset Occurred";
BA_ "VNSigAllNodes" SG_ 197 WRSLNDWhlRotStRst 1;
BA_ "SignalType" SG_ 197 WRSLNDWhlDistVal "ENM";
BA_ "PacketOrder" SG_ 197 WRSLNDWhlDistVal 4;
BA_ "SignalLongName" SG_ 197 WRSLNDWhlDistVal "Wheel Rotational Status Left Non Driven : Wheel Distance Validity";
BA_ "VNSigAllNodes" SG_ 197 WRSLNDWhlDistVal 1;
BA_ "SignalType" SG_ 197 WRSLNDWhlDistTstm "UNM";
BA_ "PacketOrder" SG_ 197 WRSLNDWhlDistTstm 6;
BA_ "SignalLongName" SG_ 197 WRSLNDWhlDistTstm "Wheel Rotational Status Left Non Driven : Wheel Distance Timestamp";
BA_ "VNSigAllNodes" SG_ 197 WRSLNDWhlDistTstm 1;
BA_ "SignalType" SG_ 197 WRSLNDWhlDistPCntr "UNM";
BA_ "PacketOrder" SG_ 197 WRSLNDWhlDistPCntr 5;
BA_ "SignalLongName" SG_ 197 WRSLNDWhlDistPCntr "Wheel Rotational Status Left Non Driven : Wheel Distance Pulse Counter";
BA_ "VNSigAllNodes" SG_ 197 WRSLNDWhlDistPCntr 1;
BA_ "SignalType" SG_ 197 WRSLNDSeqNum "UNM";
BA_ "PacketOrder" SG_ 197 WRSLNDSeqNum 2;
BA_ "SignalLongName" SG_ 197 WRSLNDSeqNum "Wheel Rotational Status Left Non Driven : Sequence Number";
BA_ "VNSigAllNodes" SG_ 197 WRSLNDSeqNum 1;
BA_ "SignalType" SG_ 197 WRSRNDWhlRotStRst "BLN";
BA_ "PacketOrder" SG_ 197 WRSRNDWhlRotStRst 3;
BA_ "SignalLongName" SG_ 197 WRSRNDWhlRotStRst "Wheel Rotational Status Right Non Driven : Wheel Rotational Status Reset Occurred";
BA_ "VNSigAllNodes" SG_ 197 WRSRNDWhlRotStRst 1;
BA_ "SignalType" SG_ 197 WRSRNDWhlDisTpRC "UNM";
BA_ "PacketOrder" SG_ 197 WRSRNDWhlDisTpRC 1;
BA_ "SignalLongName" SG_ 197 WRSRNDWhlDisTpRC "Wheel Rotational Status Right Non Driven : Wheel Distance Timestamp Rollover Counter";
BA_ "VNSigAllNodes" SG_ 197 WRSRNDWhlDisTpRC 1;
BA_ "SignalType" SG_ 197 WRSRNDWhlDistVal "ENM";
BA_ "PacketOrder" SG_ 197 WRSRNDWhlDistVal 4;
BA_ "SignalLongName" SG_ 197 WRSRNDWhlDistVal "Wheel Rotational Status Right Non Driven : Wheel Distance Validity";
BA_ "VNSigAllNodes" SG_ 197 WRSRNDWhlDistVal 1;
BA_ "SignalType" SG_ 197 WRSRNDWhlDistTstm "UNM";
BA_ "PacketOrder" SG_ 197 WRSRNDWhlDistTstm 6;
BA_ "SignalLongName" SG_ 197 WRSRNDWhlDistTstm "Wheel Rotational Status Right Non Driven : Wheel Distance Timestamp";
BA_ "VNSigAllNodes" SG_ 197 WRSRNDWhlDistTstm 1;
BA_ "SignalType" SG_ 197 WRSRNDWhlDistPCntr "UNM";
BA_ "PacketOrder" SG_ 197 WRSRNDWhlDistPCntr 5;
BA_ "SignalLongName" SG_ 197 WRSRNDWhlDistPCntr "Wheel Rotational Status Right Non Driven : Wheel Distance Pulse Counter";
BA_ "VNSigAllNodes" SG_ 197 WRSRNDWhlDistPCntr 1;
BA_ "SignalType" SG_ 197 WRSRNDSeqNum "UNM";
BA_ "PacketOrder" SG_ 197 WRSRNDSeqNum 2;
BA_ "SignalLongName" SG_ 197 WRSRNDSeqNum "Wheel Rotational Status Right Non Driven : Sequence Number";
BA_ "VNSigAllNodes" SG_ 197 WRSRNDSeqNum 1;
BA_ "SignalType" SG_ 500 EnhDrvMdSwChUseAct "BLN";
BA_ "SignalLongName" SG_ 500 EnhDrvMdSwChUseAct "Enhanced Driver Selected Mode Switch Chassis Use Active";
BA_ "VNSigAllNodes" SG_ 500 EnhDrvMdSwChUseAct 1;
BA_ "SignalType" SG_ 500 EnhDrvSelMdSwStat "ENM";
BA_ "SignalLongName" SG_ 500 EnhDrvSelMdSwStat "Enhanced Driver Selected Mode Switch Status";
BA_ "VNSigAllNodes" SG_ 500 EnhDrvSelMdSwStat 1;
BA_ "SignalType" SG_ 500 DrvSelMd8Stat "ENM";
BA_ "SignalLongName" SG_ 500 DrvSelMd8Stat "Driver Selected Mode 8 Status";
BA_ "VNSigAllNodes" SG_ 500 DrvSelMd8Stat 1;
BA_ "SignalType" SG_ 500 DrvSelMd8ReqDnd "BLN";
BA_ "SignalLongName" SG_ 500 DrvSelMd8ReqDnd "Driver Selected Mode 8 Request Denied";
BA_ "VNSigAllNodes" SG_ 500 DrvSelMd8ReqDnd 1;
BA_ "SignalType" SG_ 500 DrvSelMd7Stat "ENM";
BA_ "SignalLongName" SG_ 500 DrvSelMd7Stat "Driver Selected Mode 7 Status";
BA_ "VNSigAllNodes" SG_ 500 DrvSelMd7Stat 1;
BA_ "SignalType" SG_ 500 DrvSelMd7ReqDnd "BLN";
BA_ "SignalLongName" SG_ 500 DrvSelMd7ReqDnd "Driver Selected Mode 7 Request Denied";
BA_ "VNSigAllNodes" SG_ 500 DrvSelMd7ReqDnd 1;
BA_ "SignalType" SG_ 500 DrvSelMd6Stat "ENM";
BA_ "SignalLongName" SG_ 500 DrvSelMd6Stat "Driver Selected Mode 6 Status";
BA_ "VNSigAllNodes" SG_ 500 DrvSelMd6Stat 1;
BA_ "SignalType" SG_ 500 DrvSelMd6ReqDnd "BLN";
BA_ "SignalLongName" SG_ 500 DrvSelMd6ReqDnd "Driver Selected Mode 6 Request Denied";
BA_ "VNSigAllNodes" SG_ 500 DrvSelMd6ReqDnd 1;
BA_ "SignalType" SG_ 500 DrvSelMd5Stat "ENM";
BA_ "SignalLongName" SG_ 500 DrvSelMd5Stat "Driver Selected Mode 5 Status";
BA_ "VNSigAllNodes" SG_ 500 DrvSelMd5Stat 1;
BA_ "SignalType" SG_ 500 DrvSelMd5ReqDnd "BLN";
BA_ "SignalLongName" SG_ 500 DrvSelMd5ReqDnd "Driver Selected Mode 5 Request Denied";
BA_ "VNSigAllNodes" SG_ 500 DrvSelMd5ReqDnd 1;
BA_ "SignalType" SG_ 500 DrvSelMd4Stat "ENM";
BA_ "SignalLongName" SG_ 500 DrvSelMd4Stat "Driver Selected Mode 4 Status";
BA_ "VNSigAllNodes" SG_ 500 DrvSelMd4Stat 1;
BA_ "SignalType" SG_ 500 DrvSelMd4ReqDnd "BLN";
BA_ "SignalLongName" SG_ 500 DrvSelMd4ReqDnd "Driver Selected Mode 4 Request Denied";
BA_ "VNSigAllNodes" SG_ 500 DrvSelMd4ReqDnd 1;
BA_ "SignalType" SG_ 500 DrvSelMd3Stat "ENM";
BA_ "SignalLongName" SG_ 500 DrvSelMd3Stat "Driver Selected Mode 3 Status";
BA_ "VNSigAllNodes" SG_ 500 DrvSelMd3Stat 1;
BA_ "SignalType" SG_ 500 DrvSelMd3ReqDnd "BLN";
BA_ "SignalLongName" SG_ 500 DrvSelMd3ReqDnd "Driver Selected Mode 3 Request Denied";
BA_ "VNSigAllNodes" SG_ 500 DrvSelMd3ReqDnd 1;
BA_ "SignalType" SG_ 500 DrvSelMd2Stat "ENM";
BA_ "SignalLongName" SG_ 500 DrvSelMd2Stat "Driver Selected Mode 2 Status";
BA_ "VNSigAllNodes" SG_ 500 DrvSelMd2Stat 1;
BA_ "SignalType" SG_ 500 DrvSelMd2ReqDnd "BLN";
BA_ "SignalLongName" SG_ 500 DrvSelMd2ReqDnd "Driver Selected Mode 2 Request Denied";
BA_ "VNSigAllNodes" SG_ 500 DrvSelMd2ReqDnd 1;
BA_ "SignalType" SG_ 500 DSMSS_DrvSelMd0Pn "BLN";
BA_ "PacketOrder" SG_ 500 DSMSS_DrvSelMd0Pn 17;
BA_ "SignalLongName" SG_ 500 DSMSS_DrvSelMd0Pn "Driver Selected Mode Selection Status : Driver Selected Mode 0 Pending";
BA_ "VNSigAllNodes" SG_ 500 DSMSS_DrvSelMd0Pn 1;
BA_ "SignalType" SG_ 500 DSMSS_DrvSelMd8Pn "BLN";
BA_ "PacketOrder" SG_ 500 DSMSS_DrvSelMd8Pn 16;
BA_ "SignalLongName" SG_ 500 DSMSS_DrvSelMd8Pn "Driver Selected Mode Selection Status : Driver Selected Mode 8 Pending";
BA_ "VNSigAllNodes" SG_ 500 DSMSS_DrvSelMd8Pn 1;
BA_ "SignalType" SG_ 500 DSMSS_DrvSelMd7Pn "BLN";
BA_ "PacketOrder" SG_ 500 DSMSS_DrvSelMd7Pn 15;
BA_ "SignalLongName" SG_ 500 DSMSS_DrvSelMd7Pn "Driver Selected Mode Selection Status : Driver Selected Mode 7 Pending";
BA_ "VNSigAllNodes" SG_ 500 DSMSS_DrvSelMd7Pn 1;
BA_ "SignalType" SG_ 500 DSMSS_DrvSelMd6Pn "BLN";
BA_ "PacketOrder" SG_ 500 DSMSS_DrvSelMd6Pn 14;
BA_ "SignalLongName" SG_ 500 DSMSS_DrvSelMd6Pn "Driver Selected Mode Selection Status : Driver Selected Mode 6 Pending";
BA_ "VNSigAllNodes" SG_ 500 DSMSS_DrvSelMd6Pn 1;
BA_ "SignalType" SG_ 500 DSMSS_DrvSelMd5Pn "BLN";
BA_ "PacketOrder" SG_ 500 DSMSS_DrvSelMd5Pn 13;
BA_ "SignalLongName" SG_ 500 DSMSS_DrvSelMd5Pn "Driver Selected Mode Selection Status : Driver Selected Mode 5 Pending";
BA_ "VNSigAllNodes" SG_ 500 DSMSS_DrvSelMd5Pn 1;
BA_ "SignalType" SG_ 500 DSMSS_DrvSelMd4Pn "BLN";
BA_ "PacketOrder" SG_ 500 DSMSS_DrvSelMd4Pn 12;
BA_ "SignalLongName" SG_ 500 DSMSS_DrvSelMd4Pn "Driver Selected Mode Selection Status : Driver Selected Mode 4 Pending";
BA_ "VNSigAllNodes" SG_ 500 DSMSS_DrvSelMd4Pn 1;
BA_ "SignalType" SG_ 500 DSMSS_DrvSelMd3Pn "BLN";
BA_ "PacketOrder" SG_ 500 DSMSS_DrvSelMd3Pn 11;
BA_ "SignalLongName" SG_ 500 DSMSS_DrvSelMd3Pn "Driver Selected Mode Selection Status : Driver Selected Mode 3 Pending";
BA_ "VNSigAllNodes" SG_ 500 DSMSS_DrvSelMd3Pn 1;
BA_ "SignalType" SG_ 500 DSMSS_DrvSelMd2Pn "BLN";
BA_ "PacketOrder" SG_ 500 DSMSS_DrvSelMd2Pn 10;
BA_ "SignalLongName" SG_ 500 DSMSS_DrvSelMd2Pn "Driver Selected Mode Selection Status : Driver Selected Mode 2 Pending";
BA_ "VNSigAllNodes" SG_ 500 DSMSS_DrvSelMd2Pn 1;
BA_ "SignalType" SG_ 500 DSMSS_DrvSelMd1Pn "BLN";
BA_ "PacketOrder" SG_ 500 DSMSS_DrvSelMd1Pn 9;
BA_ "SignalLongName" SG_ 500 DSMSS_DrvSelMd1Pn "Driver Selected Mode Selection Status : Driver Selected Mode 1 Pending";
BA_ "VNSigAllNodes" SG_ 500 DSMSS_DrvSelMd1Pn 1;
BA_ "SignalType" SG_ 500 DSMSS_DrvSelMd8Un "BLN";
BA_ "PacketOrder" SG_ 500 DSMSS_DrvSelMd8Un 8;
BA_ "SignalLongName" SG_ 500 DSMSS_DrvSelMd8Un "Driver Selected Mode Selection Status : Driver Selected Mode 8 Unavailable";
BA_ "VNSigAllNodes" SG_ 500 DSMSS_DrvSelMd8Un 1;
BA_ "SignalType" SG_ 500 DSMSS_DrvSelMd7Un "BLN";
BA_ "PacketOrder" SG_ 500 DSMSS_DrvSelMd7Un 7;
BA_ "SignalLongName" SG_ 500 DSMSS_DrvSelMd7Un "Driver Selected Mode Selection Status : Driver Selected Mode 7 Unavailable";
BA_ "VNSigAllNodes" SG_ 500 DSMSS_DrvSelMd7Un 1;
BA_ "SignalType" SG_ 500 DSMSS_DrvSelMd6Un "BLN";
BA_ "PacketOrder" SG_ 500 DSMSS_DrvSelMd6Un 6;
BA_ "SignalLongName" SG_ 500 DSMSS_DrvSelMd6Un "Driver Selected Mode Selection Status : Driver Selected Mode 6 Unavailable";
BA_ "VNSigAllNodes" SG_ 500 DSMSS_DrvSelMd6Un 1;
BA_ "SignalType" SG_ 500 DSMSS_DrvSelMd5Un "BLN";
BA_ "PacketOrder" SG_ 500 DSMSS_DrvSelMd5Un 5;
BA_ "SignalLongName" SG_ 500 DSMSS_DrvSelMd5Un "Driver Selected Mode Selection Status : Driver Selected Mode 5 Unavailable";
BA_ "VNSigAllNodes" SG_ 500 DSMSS_DrvSelMd5Un 1;
BA_ "SignalType" SG_ 500 DSMSS_DrvSelMd4Un "BLN";
BA_ "PacketOrder" SG_ 500 DSMSS_DrvSelMd4Un 4;
BA_ "SignalLongName" SG_ 500 DSMSS_DrvSelMd4Un "Driver Selected Mode Selection Status : Driver Selected Mode 4 Unavailable";
BA_ "VNSigAllNodes" SG_ 500 DSMSS_DrvSelMd4Un 1;
BA_ "SignalType" SG_ 500 DSMSS_DrvSelMd3Un "BLN";
BA_ "PacketOrder" SG_ 500 DSMSS_DrvSelMd3Un 3;
BA_ "SignalLongName" SG_ 500 DSMSS_DrvSelMd3Un "Driver Selected Mode Selection Status : Driver Selected Mode 3 Unavailable";
BA_ "VNSigAllNodes" SG_ 500 DSMSS_DrvSelMd3Un 1;
BA_ "SignalType" SG_ 500 DSMSS_DrvSelMd2Un "BLN";
BA_ "PacketOrder" SG_ 500 DSMSS_DrvSelMd2Un 2;
BA_ "SignalLongName" SG_ 500 DSMSS_DrvSelMd2Un "Driver Selected Mode Selection Status : Driver Selected Mode 2 Unavailable";
BA_ "VNSigAllNodes" SG_ 500 DSMSS_DrvSelMd2Un 1;
BA_ "SignalType" SG_ 500 DSMSS_DrvSelMd1Un "BLN";
BA_ "PacketOrder" SG_ 500 DSMSS_DrvSelMd1Un 1;
BA_ "SignalLongName" SG_ 500 DSMSS_DrvSelMd1Un "Driver Selected Mode Selection Status : Driver Selected Mode 1 Unavailable";
BA_ "VNSigAllNodes" SG_ 500 DSMSS_DrvSelMd1Un 1;
BA_ "SignalType" SG_ 500 DrvSelMd1ReqDnd "BLN";
BA_ "SignalLongName" SG_ 500 DrvSelMd1ReqDnd "Driver Selected Mode 1 Request Denied";
BA_ "VNSigAllNodes" SG_ 500 DrvSelMd1ReqDnd 1;
BA_ "SignalType" SG_ 500 DrvSelMd1Stat "ENM";
BA_ "SignalLongName" SG_ 500 DrvSelMd1Stat "Driver Selected Mode 1 Status";
BA_ "VNSigAllNodes" SG_ 500 DrvSelMd1Stat 1;
BA_ "SignalType" SG_ 352 ShfFrmPrkAlwd "BLN";
BA_ "SignalLongName" SG_ 352 ShfFrmPrkAlwd "Shift From Park Allowed";
BA_ "VNSigAllNodes" SG_ 352 ShfFrmPrkAlwd 1;
BA_ "SignalType" SG_ 352 AVHSwtchStats "ENM";
BA_ "SignalLongName" SG_ 352 AVHSwtchStats "Auto Vehicle Hold Switch Status";
BA_ "VNSigAllNodes" SG_ 352 AVHSwtchStats 1;
BA_ "SignalType" SG_ 352 TeenDrvAct "BLN";
BA_ "SignalLongName" SG_ 352 TeenDrvAct "Teen Driver Active";
BA_ "VNSigAllNodes" SG_ 352 TeenDrvAct 1;
BA_ "SignalType" SG_ 352 LrnEnvIdSt "ENM";
BA_ "SignalLongName" SG_ 352 LrnEnvIdSt "Learn Environment Identification Status";
BA_ "VNSigAllNodes" SG_ 352 LrnEnvIdSt 1;
BA_ "SignalType" SG_ 352 LrnEnvId "UNM";
BA_ "SignalLongName" SG_ 352 LrnEnvId "Learn Environment Identification";
BA_ "VNSigAllNodes" SG_ 352 LrnEnvId 1;
BA_ "SignalType" SG_ 352 ImoId "UNM";
BA_ "SignalLongName" SG_ 352 ImoId "Immobilizer Identifier";
BA_ "VNSigAllNodes" SG_ 352 ImoId 1;
BA_ "SignalType" SG_ 352 ImoIdSt "ENM";
BA_ "SignalLongName" SG_ 352 ImoIdSt "Immobilizer Identifier Status";
BA_ "VNSigAllNodes" SG_ 352 ImoIdSt 1;
BA_ "SignalType" SG_ 554 PrtdEPBSwStatPortVal "UNM";
BA_ "SignalLongName" SG_ 554 PrtdEPBSwStatPortVal "Protected Electric Park Brake Switch Status Protection Value";
BA_ "VNSigAllNodes" SG_ 554 PrtdEPBSwStatPortVal 1;
BA_ "SignalType" SG_ 554 PrtdEPBSwStatARC "UNM";
BA_ "SignalLongName" SG_ 554 PrtdEPBSwStatARC "Protected Electric Park Brake Switch Status Alive Rolling Count";
BA_ "VNSigAllNodes" SG_ 554 PrtdEPBSwStatARC 1;
BA_ "SignalType" SG_ 554 PrtdEPBSwStat "ENM";
BA_ "SignalLongName" SG_ 554 PrtdEPBSwStat "Protected Electric Park Brake Switch Status";
BA_ "VNSigAllNodes" SG_ 554 PrtdEPBSwStat 1;
BA_ "SignalType" SG_ 554 ElecPrkBrkApplStatPV "UNM";
BA_ "SignalLongName" SG_ 554 ElecPrkBrkApplStatPV "Electric Park Brake Application Status Protection Value";
BA_ "VNSigAllNodes" SG_ 554 ElecPrkBrkApplStatPV 1;
BA_ "SignalType" SG_ 554 ElecPrkBrkAvailStatPV "UNM";
BA_ "SignalLongName" SG_ 554 ElecPrkBrkAvailStatPV "Electric Park Brake Availability Status Protection Value";
BA_ "VNSigAllNodes" SG_ 554 ElecPrkBrkAvailStatPV 1;
BA_ "SignalType" SG_ 554 ElecPrkBrkAvailStat "ENM";
BA_ "SignalLongName" SG_ 554 ElecPrkBrkAvailStat "Electric Park Brake Availability Status";
BA_ "VNSigAllNodes" SG_ 554 ElecPrkBrkAvailStat 1;
BA_ "SignalType" SG_ 554 ElecPrkBrkStatRC "UNM";
BA_ "SignalLongName" SG_ 554 ElecPrkBrkStatRC "Electric Park Brake Status Rolling Count";
BA_ "VNSigAllNodes" SG_ 554 ElecPrkBrkStatRC 1;
BA_ "SignalType" SG_ 554 ElecPrkBrkApplStat "ENM";
BA_ "SignalLongName" SG_ 554 ElecPrkBrkApplStat "Electric Park Brake Application Status";
BA_ "VNSigAllNodes" SG_ 554 ElecPrkBrkApplStat 1;
BA_ "SignalType" SG_ 566 RdHVBatHtrCntctrStat "ENM";
BA_ "SignalLongName" SG_ 566 RdHVBatHtrCntctrStat "Redundant High Voltage Battery Heater Contactor Status";
BA_ "VNSigAllNodes" SG_ 566 RdHVBatHtrCntctrStat 1;
BA_ "SignalType" SG_ 566 ChrgSysShftPrkReqPval "UNM";
BA_ "SignalLongName" SG_ 566 ChrgSysShftPrkReqPval "Charging System Shift To Park Requested Protection Value";
BA_ "VNSigAllNodes" SG_ 566 ChrgSysShftPrkReqPval 1;
BA_ "SignalType" SG_ 566 ChrgSysShftPrkReqARC "UNM";
BA_ "SignalLongName" SG_ 566 ChrgSysShftPrkReqARC "Charging System Shift To Park Requested Alive Rolling Count";
BA_ "VNSigAllNodes" SG_ 566 ChrgSysShftPrkReqARC 1;
BA_ "SignalType" SG_ 566 ChrgSysShftPrkReq "BLN";
BA_ "SignalLongName" SG_ 566 ChrgSysShftPrkReq "Charging System Shift To Park Requested";
BA_ "VNSigAllNodes" SG_ 566 ChrgSysShftPrkReq 1;
BA_ "SignalType" SG_ 566 ChrgSysAudblIndRq "ENM";
BA_ "SignalLongName" SG_ 566 ChrgSysAudblIndRq "Charging System Audible Indication Request";
BA_ "VNSigAllNodes" SG_ 566 ChrgSysAudblIndRq 1;
BA_ "SignalType" SG_ 566 HVBatChrgCrdAlrtReq "ENM";
BA_ "SignalLongName" SG_ 566 HVBatChrgCrdAlrtReq "High Voltage Battery Charge Cord Alert Request";
BA_ "VNSigAllNodes" SG_ 566 HVBatChrgCrdAlrtReq 1;
BA_ "SignalType" SG_ 566 RdHVBatLwParMdReq "BLN";
BA_ "SignalLongName" SG_ 566 RdHVBatLwParMdReq "Redundant High Voltage Battery Low Parasitic Mode Requested";
BA_ "VNSigAllNodes" SG_ 566 RdHVBatLwParMdReq 1;
BA_ "SignalType" SG_ 566 RdHVBtClOVFFTstRq "BLN";
BA_ "SignalLongName" SG_ 566 RdHVBtClOVFFTstRq "Redundant High Voltage Battery Cell Over Voltage Fault Flag Test Req";
BA_ "VNSigAllNodes" SG_ 566 RdHVBtClOVFFTstRq 1;
BA_ "SignalType" SG_ 566 RdHVBtClOVFFTstIdx "UNM";
BA_ "SignalLongName" SG_ 566 RdHVBtClOVFFTstIdx "Redundant High Voltage Battery Cell Over Voltage Fault Flag Test Index";
BA_ "VNSigAllNodes" SG_ 566 RdHVBtClOVFFTstIdx 1;
BA_ "SignalType" SG_ 566 ClimCtrlHVDvcShtdwnCmd "BLN";
BA_ "SignalLongName" SG_ 566 ClimCtrlHVDvcShtdwnCmd "Climate Control High Voltage Device Shutdown Commanded";
BA_ "VNSigAllNodes" SG_ 566 ClimCtrlHVDvcShtdwnCmd 1;
BA_ "SignalType" SG_ 566 ThrmlRefCompSpdReqARC "UNM";
BA_ "SignalLongName" SG_ 566 ThrmlRefCompSpdReqARC "Thermal Refrigerant Compressor Speed Request Alive Rolling Count";
BA_ "VNSigAllNodes" SG_ 566 ThrmlRefCompSpdReqARC 1;
BA_ "SignalType" SG_ 566 VICMHVEnMgCmEnTrS "ENM";
BA_ "SignalLongName" SG_ 566 VICMHVEnMgCmEnTrS "VICM High Voltage Energy Management Comm Enable Terminal Status";
BA_ "VNSigAllNodes" SG_ 566 VICMHVEnMgCmEnTrS 1;
BA_ "SignalType" SG_ 566 ChrgSysPrkBrkAnmsBrkReqPVal "UNM";
BA_ "SignalLongName" SG_ 566 ChrgSysPrkBrkAnmsBrkReqPVal "Charging System Park Brake Autonomous Apply Request Protection Value";
BA_ "VNSigAllNodes" SG_ 566 ChrgSysPrkBrkAnmsBrkReqPVal 1;
BA_ "SignalType" SG_ 566 ChrgSysPrkBrkAnmsBrkReqARC "UNM";
BA_ "SignalLongName" SG_ 566 ChrgSysPrkBrkAnmsBrkReqARC "Charging System Park Brake Autonomous Apply Request Alive Rolling Count";
BA_ "VNSigAllNodes" SG_ 566 ChrgSysPrkBrkAnmsBrkReqARC 1;
BA_ "SignalType" SG_ 566 ChrgSysPrkBrkAnmsBrkReq "BLN";
BA_ "SignalLongName" SG_ 566 ChrgSysPrkBrkAnmsBrkReq "Charging System Park Brake Autonomous Apply Request";
BA_ "VNSigAllNodes" SG_ 566 ChrgSysPrkBrkAnmsBrkReq 1;
BA_ "SignalType" SG_ 566 HybVehHiVltSysDisbld_236 "BLN";
BA_ "SignalLongName" SG_ 566 HybVehHiVltSysDisbld_236 "Hybrid Vehicle High Voltage System Disabled";
BA_ "VNSigAllNodes" SG_ 566 HybVehHiVltSysDisbld_236 1;
BA_ "SignalType" SG_ 566 ThrmlRefCompSpdReq "UNM";
BA_ "SignalLongName" SG_ 566 ThrmlRefCompSpdReq "Thermal Refrigerant Compressor Speed Request";
BA_ "VNSigAllNodes" SG_ 566 ThrmlRefCompSpdReq 1;
BA_ "SignalLongName" SG_ 566 RHVBCCS_ACChrgrCntCmd "Redundant High Voltage Battery Connect Command Status : AC Charger Connect Commanded";
BA_ "VNSigAllNodes" SG_ 566 RHVBCCS_ACChrgrCntCmd 1;
BA_ "PacketOrder" SG_ 566 RHVBCCS_InvtrCntCmd 7;
BA_ "SignalLongName" SG_ 566 RHVBCCS_InvtrCntCmd "Redundant High Voltage Battery Connect Command Status : Inverter Connect Commanded";
BA_ "VNSigAllNodes" SG_ 566 RHVBCCS_InvtrCntCmd 1;
BA_ "SignalType" SG_ 566 RHVBCCS_InvtrCaptrChrgAct "ENM";
BA_ "PacketOrder" SG_ 566 RHVBCCS_InvtrCaptrChrgAct 1;
BA_ "SignalLongName" SG_ 566 RHVBCCS_InvtrCaptrChrgAct "Redundant High Voltage Battery Connect Command Status : Inverter Capacitor Charging Active";
BA_ "VNSigAllNodes" SG_ 566 RHVBCCS_InvtrCaptrChrgAct 1;
BA_ "SignalLongName" SG_ 566 RHVBCCS_DCChrgrCntCmd "Redundant High Voltage Battery Connect Command Status : DC Charger Connect Commanded";
BA_ "VNSigAllNodes" SG_ 566 RHVBCCS_DCChrgrCntCmd 1;
BA_ "SignalType" SG_ 566 RdDCChrgCntctrStat "ENM";
BA_ "PacketOrder" SG_ 566 RdDCChrgCntctrStat 1;
BA_ "SignalLongName" SG_ 566 RdDCChrgCntctrStat "Redundant DC Charge Contactor Status";
BA_ "VNSigAllNodes" SG_ 566 RdDCChrgCntctrStat 1;
BA_ "SignalType" SG_ 566 RdHVCntctrShdwnCmd "ENM";
BA_ "SignalLongName" SG_ 566 RdHVCntctrShdwnCmd "Redundant High Voltage Contactor Shutdown Command";
BA_ "VNSigAllNodes" SG_ 566 RdHVCntctrShdwnCmd 1;
BA_ "SignalType" SG_ 1017 ACRfHiSdFldPrsV "ENM";
BA_ "SignalLongName" SG_ 1017 ACRfHiSdFldPrsV "Air Conditioning Refrigerant High Side Fluid Pressure Validity";
BA_ "VNSigAllNodes" SG_ 1017 ACRfHiSdFldPrsV 1;
BA_ "SignalType" SG_ 1017 ACRfHiSdFldPrs "UNM";
BA_ "SignalLongName" SG_ 1017 ACRfHiSdFldPrs "Air Conditioning Refrigerant High Side Fluid Pressure";
BA_ "VNSigAllNodes" SG_ 1017 ACRfHiSdFldPrs 1;
BA_ "SignalType" SG_ 1017 GenStptDtCycPtOvrAct "BLN";
BA_ "SignalLongName" SG_ 1017 GenStptDtCycPtOvrAct "Generator Setpoint Duty Cycle Powertrain Override Active";
BA_ "VNSigAllNodes" SG_ 1017 GenStptDtCycPtOvrAct 1;
BA_ "SignalType" SG_ 1017 VehTopSpdLmtMdAct "BLN";
BA_ "SignalLongName" SG_ 1017 VehTopSpdLmtMdAct "Vehicle Top Speed Limit Mode Active";
BA_ "VNSigAllNodes" SG_ 1017 VehTopSpdLmtMdAct 1;
BA_ "SignalType" SG_ 1017 VehTopSpdLmtArbVal "UNM";
BA_ "SignalLongName" SG_ 1017 VehTopSpdLmtArbVal "Vehicle Top Speed Limit Arbitrated Value";
BA_ "VNSigAllNodes" SG_ 1017 VehTopSpdLmtArbVal 1;
BA_ "SignalType" SG_ 1017 GenFldDutCycV "ENM";
BA_ "SignalLongName" SG_ 1017 GenFldDutCycV "Generator Field Duty Cycle Validity";
BA_ "VNSigAllNodes" SG_ 1017 GenFldDutCycV 1;
BA_ "SignalType" SG_ 1017 GenFldDutCyc "UNM";
BA_ "SignalLongName" SG_ 1017 GenFldDutCyc "Generator Field Duty Cycle";
BA_ "VNSigAllNodes" SG_ 1017 GenFldDutCyc 1;
BA_ "SignalType" SG_ 1017 GenFld "BLN";
BA_ "SignalLongName" SG_ 1017 GenFld "Generator Failed";
BA_ "VNSigAllNodes" SG_ 1017 GenFld 1;
BA_ "SignalType" SG_ 1017 FlInjRlCtRstOcc "BLN";
BA_ "SignalLongName" SG_ 1017 FlInjRlCtRstOcc "Fuel Injected Rolling Count Reset Occurred";
BA_ "VNSigAllNodes" SG_ 1017 FlInjRlCtRstOcc 1;
BA_ "SignalType" SG_ 1017 FlInjRlCt "UNM";
BA_ "SignalLongName" SG_ 1017 FlInjRlCt "Fuel Injected Rolling Count";
BA_ "VNSigAllNodes" SG_ 1017 FlInjRlCt 1;
BA_ "SignalType" SG_ 1017 EngSpdLmtnMdAct "BLN";
BA_ "SignalLongName" SG_ 1017 EngSpdLmtnMdAct "Engine Speed Limitation Mode Active";
BA_ "VNSigAllNodes" SG_ 1017 EngSpdLmtnMdAct 1;
BA_ "SignalType" SG_ 1017 EngOilRmnLf "UNM";
BA_ "SignalLongName" SG_ 1017 EngOilRmnLf "Engine Oil Remaining Life";
BA_ "VNSigAllNodes" SG_ 1017 EngOilRmnLf 1;
BA_ "SignalType" SG_ 1017 EngCoolFanSpd "UNM";
BA_ "SignalLongName" SG_ 1017 EngCoolFanSpd "Engine Cooling Fan Speed";
BA_ "VNSigAllNodes" SG_ 1017 EngCoolFanSpd 1;
BA_ "SignalType" SG_ 401 SecBrkModCapStat "ENM";
BA_ "SignalLongName" SG_ 401 SecBrkModCapStat "Secondary Brake Module Capability Status";
BA_ "VNSigAllNodes" SG_ 401 SecBrkModCapStat 1;
BA_ "SignalType" SG_ 401 SecMaxAvlBrkTrqGrad "UNM";
BA_ "SignalLongName" SG_ 401 SecMaxAvlBrkTrqGrad "Secondary Maximum Available Brake Torque Gradient";
BA_ "VNSigAllNodes" SG_ 401 SecMaxAvlBrkTrqGrad 1;
BA_ "SignalType" SG_ 401 SecMaxAvlBrkTrq "UNM";
BA_ "SignalLongName" SG_ 401 SecMaxAvlBrkTrq "Secondary Maximum Available Brake Torque";
BA_ "GenSigStartValue" SG_ 401 SecMaxAvlBrkTrq 32767;
BA_ "VNSigAllNodes" SG_ 401 SecMaxAvlBrkTrq 1;
BA_ "SignalType" SG_ 401 SecBrkSystCapChksm "UNM";
BA_ "SignalLongName" SG_ 401 SecBrkSystCapChksm "Secondary Brake System Capability Checksum";
BA_ "VNSigAllNodes" SG_ 401 SecBrkSystCapChksm 1;
BA_ "SignalType" SG_ 401 SecBrkSysCapARC "UNM";
BA_ "SignalLongName" SG_ 401 SecBrkSysCapARC "Secondary Brake System Capability Alive Rolling Count";
BA_ "VNSigAllNodes" SG_ 401 SecBrkSysCapARC 1;
BA_ "SignalType" SG_ 401 SecEstSrfcMuTyp "ENM";
BA_ "SignalLongName" SG_ 401 SecEstSrfcMuTyp "Secondary Estimated Surface Mu Type";
BA_ "VNSigAllNodes" SG_ 401 SecEstSrfcMuTyp 1;
BA_ "SignalType" SG_ 401 SecEstSrfcMuCapV "ENM";
BA_ "SignalLongName" SG_ 401 SecEstSrfcMuCapV "Secondary Estimated Surface Mu Capacity Validity";
BA_ "VNSigAllNodes" SG_ 401 SecEstSrfcMuCapV 1;
BA_ "SignalType" SG_ 401 SecEstSrfcMuCap "UNM";
BA_ "SignalLongName" SG_ 401 SecEstSrfcMuCap "Secondary Estimated Surface Mu Capacity";
BA_ "VNSigAllNodes" SG_ 401 SecEstSrfcMuCap 1;
BA_ "SignalType" SG_ 320 Ky_IdDevPrgmAuthReq "BLN";
BA_ "SignalLongName" SG_ 320 Ky_IdDevPrgmAuthReq "Key / Identification Device Programming Authentication Requested";
BA_ "VNSigAllNodes" SG_ 320 Ky_IdDevPrgmAuthReq 1;
BA_ "SignalType" SG_ 320 AutoBmSlctAllwd "BLN";
BA_ "SignalLongName" SG_ 320 AutoBmSlctAllwd "Automatic Beam Select Allowed";
BA_ "VNSigAllNodes" SG_ 320 AutoBmSlctAllwd 1;
BA_ "SignalType" SG_ 320 BrkLtsAtv "BLN";
BA_ "SignalLongName" SG_ 320 BrkLtsAtv "Brake Lights Active";
BA_ "VNSigAllNodes" SG_ 320 BrkLtsAtv 1;
BA_ "SignalType" SG_ 320 TrnSwAct "ENM";
BA_ "SignalLongName" SG_ 320 TrnSwAct "Turn Switch Activation";
BA_ "VNSigAllNodes" SG_ 320 TrnSwAct 1;
BA_ "SignalType" SG_ 320 RrFogLmpsAct "BLN";
BA_ "SignalLongName" SG_ 320 RrFogLmpsAct "Rear Fog Lamps Active";
BA_ "VNSigAllNodes" SG_ 320 RrFogLmpsAct 1;
BA_ "SignalType" SG_ 320 OtsdAmbtLtLvlStatV "ENM";
BA_ "SignalLongName" SG_ 320 OtsdAmbtLtLvlStatV "Outside Ambient Light Level Status Validity";
BA_ "VNSigAllNodes" SG_ 320 OtsdAmbtLtLvlStatV 1;
BA_ "SignalType" SG_ 320 OtsdAmbtLtLvlStat "ENM";
BA_ "SignalLongName" SG_ 320 OtsdAmbtLtLvlStat "Outside Ambient Light Level Status";
BA_ "VNSigAllNodes" SG_ 320 OtsdAmbtLtLvlStat 1;
BA_ "SignalType" SG_ 320 MainLghtSw "ENM";
BA_ "SignalLongName" SG_ 320 MainLghtSw "Main Light Switch";
BA_ "VNSigAllNodes" SG_ 320 MainLghtSw 1;
BA_ "SignalType" SG_ 320 LowBmAct "BLN";
BA_ "SignalLongName" SG_ 320 LowBmAct "Low Beam Active";
BA_ "VNSigAllNodes" SG_ 320 LowBmAct 1;
BA_ "SignalType" SG_ 320 HighBmAct "BLN";
BA_ "SignalLongName" SG_ 320 HighBmAct "High Beam Active";
BA_ "VNSigAllNodes" SG_ 320 HighBmAct 1;
BA_ "SignalType" SG_ 320 HdlmpBmSelectStat "ENM";
BA_ "SignalLongName" SG_ 320 HdlmpBmSelectStat "Headlamp Beam Select Status";
BA_ "VNSigAllNodes" SG_ 320 HdlmpBmSelectStat 1;
BA_ "SignalType" SG_ 320 FlToPsSwAtv "BLN";
BA_ "SignalLongName" SG_ 320 FlToPsSwAtv "Flash To Pass Switch Active";
BA_ "VNSigAllNodes" SG_ 320 FlToPsSwAtv 1;
BA_ "SignalType" SG_ 320 AdvFrntLghtSysEnbld "BLN";
BA_ "SignalLongName" SG_ 320 AdvFrntLghtSysEnbld "Advanced Front Lighting System Enabled";
BA_ "VNSigAllNodes" SG_ 320 AdvFrntLghtSysEnbld 1;
BA_ "SignalType" SG_ 320 FrFogLmpsAct "BLN";
BA_ "SignalLongName" SG_ 320 FrFogLmpsAct "Front Fog Lamps Active";
BA_ "VNSigAllNodes" SG_ 320 FrFogLmpsAct 1;
BA_ "SignalType" SG_ 320 AutLghtCtrl "BLN";
BA_ "SignalLongName" SG_ 320 AutLghtCtrl "Auto Light Control";
BA_ "VNSigAllNodes" SG_ 320 AutLghtCtrl 1;
BA_REL_ "GenSigSuprvResp" BU_SG_REL_ EBOOST_OBD_PHS SG_ 1008 SecuredVehSpdSrcDrvn 1;
BA_REL_ "GenSigTimeoutMsg" BU_SG_REL_ EBOOST_OBD_PHS SG_ 1008 SecuredVehSpdSrcDrvn 1008;
BA_REL_ "GenSigTimeoutTime" BU_SG_REL_ EBOOST_OBD_PHS SG_ 1008 SecuredVehSpdSrcDrvn 250;
BA_REL_ "GenSigSuprvResp" BU_SG_REL_ EPSb_PHS SG_ 1008 SecuredVehSpdSrcDrvn 1;
BA_REL_ "GenSigTimeoutMsg" BU_SG_REL_ EPSb_PHS SG_ 1008 SecuredVehSpdSrcDrvn 1008;
BA_REL_ "GenSigTimeoutTime" BU_SG_REL_ EPSb_PHS SG_ 1008 SecuredVehSpdSrcDrvn 250;
BA_REL_ "GenSigVBitResp" BU_SG_REL_ EBOOST_OBD_PHS SG_ 1008 SecuredVehSpdDrvn 1;
BA_REL_ "GenSigSuprvResp" BU_SG_REL_ EBOOST_OBD_PHS SG_ 1008 SecuredVehSpdDrvn 1;
BA_REL_ "GenSigTimeoutMsg" BU_SG_REL_ EBOOST_OBD_PHS SG_ 1008 SecuredVehSpdDrvn 1008;
BA_REL_ "GenSigTimeoutTime" BU_SG_REL_ EBOOST_OBD_PHS SG_ 1008 SecuredVehSpdDrvn 250;
BA_REL_ "GenSigVBitResp" BU_SG_REL_ EPSb_PHS SG_ 1008 SecuredVehSpdDrvn 1;
BA_REL_ "GenSigSuprvResp" BU_SG_REL_ EPSb_PHS SG_ 1008 SecuredVehSpdDrvn 1;
BA_REL_ "GenSigTimeoutMsg" BU_SG_REL_ EPSb_PHS SG_ 1008 SecuredVehSpdDrvn 1008;
BA_REL_ "GenSigTimeoutTime" BU_SG_REL_ EPSb_PHS SG_ 1008 SecuredVehSpdDrvn 250;
BA_REL_ "GenSigSuprvResp" BU_SG_REL_ EBOOST_OBD_PHS SG_ 1008 SecuredVehSpdAvlblDrvn 1;
BA_REL_ "GenSigTimeoutMsg" BU_SG_REL_ EBOOST_OBD_PHS SG_ 1008 SecuredVehSpdAvlblDrvn 1008;
BA_REL_ "GenSigTimeoutTime" BU_SG_REL_ EBOOST_OBD_PHS SG_ 1008 SecuredVehSpdAvlblDrvn 250;
BA_REL_ "GenSigSuprvResp" BU_SG_REL_ EPSb_PHS SG_ 1008 SecuredVehSpdAvlblDrvn 1;
BA_REL_ "GenSigTimeoutMsg" BU_SG_REL_ EPSb_PHS SG_ 1008 SecuredVehSpdAvlblDrvn 1008;
BA_REL_ "GenSigTimeoutTime" BU_SG_REL_ EPSb_PHS SG_ 1008 SecuredVehSpdAvlblDrvn 250;
BA_REL_ "GenSigSuprvResp" BU_SG_REL_ EBCM_PHS SG_ 647 EngCntrlUtldTrnCsRng 1;
BA_REL_ "GenSigTimeoutMsg" BU_SG_REL_ EBCM_PHS SG_ 647 EngCntrlUtldTrnCsRng 647;
BA_REL_ "GenSigTimeoutTime" BU_SG_REL_ EBCM_PHS SG_ 647 EngCntrlUtldTrnCsRng 250;
BA_REL_ "GenSigSuprvResp" BU_SG_REL_ EBCM_PHS SG_ 647 EngCntrlUtldTrnCsRgIn 1;
BA_REL_ "GenSigTimeoutMsg" BU_SG_REL_ EBCM_PHS SG_ 647 EngCntrlUtldTrnCsRgIn 647;
BA_REL_ "GenSigTimeoutTime" BU_SG_REL_ EBCM_PHS SG_ 647 EngCntrlUtldTrnCsRgIn 250;
BA_REL_ "GenSigSuprvResp" BU_SG_REL_ EBCM_PHS SG_ 170 CmndAxlTrqPredct 1;
BA_REL_ "GenSigTimeoutMsg" BU_SG_REL_ EBCM_PHS SG_ 170 CmndAxlTrqPredct 170;
BA_REL_ "GenSigTimeoutTime" BU_SG_REL_ EBCM_PHS SG_ 170 CmndAxlTrqPredct 250;
BA_REL_ "GenSigSuprvResp" BU_SG_REL_ EBCM_PHS SG_ 1105 ClmCntFrBlwFnSp 1;
BA_REL_ "GenSigTimeoutMsg" BU_SG_REL_ EBCM_PHS SG_ 1105 ClmCntFrBlwFnSp 1105;
BA_REL_ "GenSigTimeoutTime" BU_SG_REL_ EBCM_PHS SG_ 1105 ClmCntFrBlwFnSp 1000;
BA_REL_ "GenSigSuprvResp" BU_SG_REL_ EBCM_PHS SG_ 872 ESBR_AutoBrkgRqTyp 1;
BA_REL_ "GenSigTimeoutMsg" BU_SG_REL_ EBCM_PHS SG_ 872 ESBR_AutoBrkgRqTyp 872;
BA_REL_ "GenSigTimeoutTime" BU_SG_REL_ EBCM_PHS SG_ 872 ESBR_AutoBrkgRqTyp 250;
BA_REL_ "GenSigSuprvResp" BU_SG_REL_ EBCM_PHS SG_ 872 ESBR_AutoBrkgRqd 1;
BA_REL_ "GenSigTimeoutMsg" BU_SG_REL_ EBCM_PHS SG_ 872 ESBR_AutoBrkgRqd 872;
BA_REL_ "GenSigTimeoutTime" BU_SG_REL_ EBCM_PHS SG_ 872 ESBR_AutoBrkgRqd 250;
BA_REL_ "GenSigVBitResp" BU_SG_REL_ EBCM_PHS SG_ 1223 PropSysOffTme 1;
BA_REL_ "GenSigSuprvResp" BU_SG_REL_ EBCM_PHS SG_ 1223 PropSysOffTme 1;
BA_REL_ "GenSigTimeoutMsg" BU_SG_REL_ EBCM_PHS SG_ 1223 PropSysOffTme 1223;
BA_REL_ "GenSigTimeoutTime" BU_SG_REL_ EBCM_PHS SG_ 1223 PropSysOffTme 1250;
BA_REL_ "GenSigRxStartValue" BU_SG_REL_ EBOOST_OBD_PHS SG_ 405 EstWhlBrkPrsStat "Unknown";
BA_REL_ "GenSigSuprvResp" BU_SG_REL_ EBOOST_OBD_PHS SG_ 405 EstWhlBrkPrsStat 1;
BA_REL_ "GenSigTimeoutMsg" BU_SG_REL_ EBOOST_OBD_PHS SG_ 405 EstWhlBrkPrsStat 405;
BA_REL_ "GenSigTimeoutTime" BU_SG_REL_ EBOOST_OBD_PHS SG_ 405 EstWhlBrkPrsStat 50;
BA_REL_ "GenSigRxStartValue" BU_SG_REL_ ADIMb_PHS SG_ 405 EstWhlBrkPrsStat "0";
BA_REL_ "GenSigSuprvResp" BU_SG_REL_ ADIMb_PHS SG_ 405 EstWhlBrkPrsStat 1;
BA_REL_ "GenSigTimeoutMsg" BU_SG_REL_ ADIMb_PHS SG_ 405 EstWhlBrkPrsStat 405;
BA_REL_ "GenSigTimeoutTime" BU_SG_REL_ ADIMb_PHS SG_ 405 EstWhlBrkPrsStat 50;
BA_REL_ "GenSigRxStartValue" BU_SG_REL_ EBOOST_OBD_PHS SG_ 405 EstWhlBrkPrsRR "0";
BA_REL_ "GenSigSuprvResp" BU_SG_REL_ EBOOST_OBD_PHS SG_ 405 EstWhlBrkPrsRR 1;
BA_REL_ "GenSigTimeoutMsg" BU_SG_REL_ EBOOST_OBD_PHS SG_ 405 EstWhlBrkPrsRR 405;
BA_REL_ "GenSigTimeoutTime" BU_SG_REL_ EBOOST_OBD_PHS SG_ 405 EstWhlBrkPrsRR 50;
BA_REL_ "GenSigRxStartValue" BU_SG_REL_ ADIMb_PHS SG_ 405 EstWhlBrkPrsRR "0";
BA_REL_ "GenSigSuprvResp" BU_SG_REL_ ADIMb_PHS SG_ 405 EstWhlBrkPrsRR 1;
BA_REL_ "GenSigTimeoutMsg" BU_SG_REL_ ADIMb_PHS SG_ 405 EstWhlBrkPrsRR 405;
BA_REL_ "GenSigTimeoutTime" BU_SG_REL_ ADIMb_PHS SG_ 405 EstWhlBrkPrsRR 50;
BA_REL_ "GenSigRxStartValue" BU_SG_REL_ EBOOST_OBD_PHS SG_ 405 EstWhlBrkPrsLR "0";
BA_REL_ "GenSigSuprvResp" BU_SG_REL_ EBOOST_OBD_PHS SG_ 405 EstWhlBrkPrsLR 1;
BA_REL_ "GenSigTimeoutMsg" BU_SG_REL_ EBOOST_OBD_PHS SG_ 405 EstWhlBrkPrsLR 405;
BA_REL_ "GenSigTimeoutTime" BU_SG_REL_ EBOOST_OBD_PHS SG_ 405 EstWhlBrkPrsLR 50;
BA_REL_ "GenSigRxStartValue" BU_SG_REL_ ADIMb_PHS SG_ 405 EstWhlBrkPrsLR "0";
BA_REL_ "GenSigSuprvResp" BU_SG_REL_ ADIMb_PHS SG_ 405 EstWhlBrkPrsLR 1;
BA_REL_ "GenSigTimeoutMsg" BU_SG_REL_ ADIMb_PHS SG_ 405 EstWhlBrkPrsLR 405;
BA_REL_ "GenSigTimeoutTime" BU_SG_REL_ ADIMb_PHS SG_ 405 EstWhlBrkPrsLR 50;
BA_REL_ "GenSigRxStartValue" BU_SG_REL_ EBOOST_OBD_PHS SG_ 405 EstWhlBrkPrsRF "0";
BA_REL_ "GenSigSuprvResp" BU_SG_REL_ EBOOST_OBD_PHS SG_ 405 EstWhlBrkPrsRF 1;
BA_REL_ "GenSigTimeoutMsg" BU_SG_REL_ EBOOST_OBD_PHS SG_ 405 EstWhlBrkPrsRF 405;
BA_REL_ "GenSigTimeoutTime" BU_SG_REL_ EBOOST_OBD_PHS SG_ 405 EstWhlBrkPrsRF 50;
BA_REL_ "GenSigRxStartValue" BU_SG_REL_ ADIMb_PHS SG_ 405 EstWhlBrkPrsRF "0";
BA_REL_ "GenSigSuprvResp" BU_SG_REL_ ADIMb_PHS SG_ 405 EstWhlBrkPrsRF 1;
BA_REL_ "GenSigTimeoutMsg" BU_SG_REL_ ADIMb_PHS SG_ 405 EstWhlBrkPrsRF 405;
BA_REL_ "GenSigTimeoutTime" BU_SG_REL_ ADIMb_PHS SG_ 405 EstWhlBrkPrsRF 50;
BA_REL_ "GenSigRxStartValue" BU_SG_REL_ EBOOST_OBD_PHS SG_ 405 EstWhlBrkPrsLF "0";
BA_REL_ "GenSigSuprvResp" BU_SG_REL_ EBOOST_OBD_PHS SG_ 405 EstWhlBrkPrsLF 1;
BA_REL_ "GenSigTimeoutMsg" BU_SG_REL_ EBOOST_OBD_PHS SG_ 405 EstWhlBrkPrsLF 405;
BA_REL_ "GenSigTimeoutTime" BU_SG_REL_ EBOOST_OBD_PHS SG_ 405 EstWhlBrkPrsLF 50;
BA_REL_ "GenSigRxStartValue" BU_SG_REL_ ADIMb_PHS SG_ 405 EstWhlBrkPrsLF "0";
BA_REL_ "GenSigSuprvResp" BU_SG_REL_ ADIMb_PHS SG_ 405 EstWhlBrkPrsLF 1;
BA_REL_ "GenSigTimeoutMsg" BU_SG_REL_ ADIMb_PHS SG_ 405 EstWhlBrkPrsLF 405;
BA_REL_ "GenSigTimeoutTime" BU_SG_REL_ ADIMb_PHS SG_ 405 EstWhlBrkPrsLF 50;
BA_REL_ "GenSigRxStartValue" BU_SG_REL_ EBOOST_OBD_PHS SG_ 405 BrkEstWhlPrsChksm "0";
BA_REL_ "GenSigRxStartValue" BU_SG_REL_ ADIMb_PHS SG_ 405 BrkEstWhlPrsChksm "0";
BA_REL_ "GenSigRxStartValue" BU_SG_REL_ EBOOST_OBD_PHS SG_ 405 BrkEstWhlPrsARC "0";
BA_REL_ "GenSigRxStartValue" BU_SG_REL_ ADIMb_PHS SG_ 405 BrkEstWhlPrsARC "0";
BA_REL_ "GenSigRxStartValue" BU_SG_REL_ ADIMb_PHS SG_ 311 PriCoPCmdMsgStatRed "Normal Communication";
BA_REL_ "GenSigSuprvResp" BU_SG_REL_ ADIMb_PHS SG_ 311 PriCoPCmdMsgStatRed 1;
BA_REL_ "GenSigTimeoutMsg" BU_SG_REL_ ADIMb_PHS SG_ 311 PriCoPCmdMsgStatRed 311;
BA_REL_ "GenSigTimeoutTime" BU_SG_REL_ ADIMb_PHS SG_ 311 PriCoPCmdMsgStatRed 25;
BA_REL_ "GenSigRxStartValue" BU_SG_REL_ EBOOST_OBD_PHS SG_ 311 PriCoPCmdMsgStatRed "Normal Communication";
BA_REL_ "GenSigSuprvResp" BU_SG_REL_ EBOOST_OBD_PHS SG_ 311 PriCoPCmdMsgStatRed 1;
BA_REL_ "GenSigTimeoutMsg" BU_SG_REL_ EBOOST_OBD_PHS SG_ 311 PriCoPCmdMsgStatRed 311;
BA_REL_ "GenSigTimeoutTime" BU_SG_REL_ EBOOST_OBD_PHS SG_ 311 PriCoPCmdMsgStatRed 25;
BA_REL_ "GenSigRxStartValue" BU_SG_REL_ ADIMb_PHS SG_ 311 PriADSCmdMsgStatRed "Normal Communication";
BA_REL_ "GenSigSuprvResp" BU_SG_REL_ ADIMb_PHS SG_ 311 PriADSCmdMsgStatRed 1;
BA_REL_ "GenSigTimeoutMsg" BU_SG_REL_ ADIMb_PHS SG_ 311 PriADSCmdMsgStatRed 311;
BA_REL_ "GenSigTimeoutTime" BU_SG_REL_ ADIMb_PHS SG_ 311 PriADSCmdMsgStatRed 25;
BA_REL_ "GenSigRxStartValue" BU_SG_REL_ EBOOST_OBD_PHS SG_ 311 PriADSCmdMsgStatRed "Normal Communication";
BA_REL_ "GenSigSuprvResp" BU_SG_REL_ EBOOST_OBD_PHS SG_ 311 PriADSCmdMsgStatRed 1;
BA_REL_ "GenSigTimeoutMsg" BU_SG_REL_ EBOOST_OBD_PHS SG_ 311 PriADSCmdMsgStatRed 311;
BA_REL_ "GenSigTimeoutTime" BU_SG_REL_ EBOOST_OBD_PHS SG_ 311 PriADSCmdMsgStatRed 25;
BA_REL_ "GenSigRxStartValue" BU_SG_REL_ ADIMb_PHS SG_ 311 PriBrkSysArbStatRed "Unknown";
BA_REL_ "GenSigSuprvResp" BU_SG_REL_ ADIMb_PHS SG_ 311 PriBrkSysArbStatRed 1;
BA_REL_ "GenSigTimeoutMsg" BU_SG_REL_ ADIMb_PHS SG_ 311 PriBrkSysArbStatRed 311;
BA_REL_ "GenSigTimeoutTime" BU_SG_REL_ ADIMb_PHS SG_ 311 PriBrkSysArbStatRed 25;
BA_REL_ "GenSigRxStartValue" BU_SG_REL_ EBOOST_OBD_PHS SG_ 311 PriBrkSysArbStatRed "Unknown";
BA_REL_ "GenSigSuprvResp" BU_SG_REL_ EBOOST_OBD_PHS SG_ 311 PriBrkSysArbStatRed 1;
BA_REL_ "GenSigTimeoutMsg" BU_SG_REL_ EBOOST_OBD_PHS SG_ 311 PriBrkSysArbStatRed 311;
BA_REL_ "GenSigTimeoutTime" BU_SG_REL_ EBOOST_OBD_PHS SG_ 311 PriBrkSysArbStatRed 25;
BA_REL_ "GenSigRxStartValue" BU_SG_REL_ ADIMb_PHS SG_ 311 PriBrkSysStatRedChksm "0";
BA_REL_ "GenSigRxStartValue" BU_SG_REL_ EBOOST_OBD_PHS SG_ 311 PriBrkSysStatRedChksm "0";
BA_REL_ "GenSigRxStartValue" BU_SG_REL_ ADIMb_PHS SG_ 311 PriBrkSysStatRedARC "0";
BA_REL_ "GenSigRxStartValue" BU_SG_REL_ EBOOST_OBD_PHS SG_ 311 PriBrkSysStatRedARC "0";
BA_REL_ "GenSigRxStartValue" BU_SG_REL_ ADIMb_PHS SG_ 311 PriBrkModSbSteRed "0";
BA_REL_ "GenSigSuprvResp" BU_SG_REL_ ADIMb_PHS SG_ 311 PriBrkModSbSteRed 1;
BA_REL_ "GenSigTimeoutMsg" BU_SG_REL_ ADIMb_PHS SG_ 311 PriBrkModSbSteRed 311;
BA_REL_ "GenSigTimeoutTime" BU_SG_REL_ ADIMb_PHS SG_ 311 PriBrkModSbSteRed 25;
BA_REL_ "GenSigRxStartValue" BU_SG_REL_ EBOOST_OBD_PHS SG_ 311 PriBrkModSbSteRed "0";
BA_REL_ "GenSigSuprvResp" BU_SG_REL_ EBOOST_OBD_PHS SG_ 311 PriBrkModSbSteRed 1;
BA_REL_ "GenSigTimeoutMsg" BU_SG_REL_ EBOOST_OBD_PHS SG_ 311 PriBrkModSbSteRed 311;
BA_REL_ "GenSigTimeoutTime" BU_SG_REL_ EBOOST_OBD_PHS SG_ 311 PriBrkModSbSteRed 25;
BA_REL_ "GenSigRxStartValue" BU_SG_REL_ ADIMb_PHS SG_ 311 PriBrkSysStatRed "0";
BA_REL_ "GenSigSuprvResp" BU_SG_REL_ ADIMb_PHS SG_ 311 PriBrkSysStatRed 1;
BA_REL_ "GenSigTimeoutMsg" BU_SG_REL_ ADIMb_PHS SG_ 311 PriBrkSysStatRed 311;
BA_REL_ "GenSigTimeoutTime" BU_SG_REL_ ADIMb_PHS SG_ 311 PriBrkSysStatRed 25;
BA_REL_ "GenSigRxStartValue" BU_SG_REL_ EBOOST_OBD_PHS SG_ 311 PriBrkSysStatRed "0";
BA_REL_ "GenSigSuprvResp" BU_SG_REL_ EBOOST_OBD_PHS SG_ 311 PriBrkSysStatRed 1;
BA_REL_ "GenSigTimeoutMsg" BU_SG_REL_ EBOOST_OBD_PHS SG_ 311 PriBrkSysStatRed 311;
BA_REL_ "GenSigTimeoutTime" BU_SG_REL_ EBOOST_OBD_PHS SG_ 311 PriBrkSysStatRed 25;
BA_REL_ "GenSigRxStartValue" BU_SG_REL_ ADIMb_PHS SG_ 311 PriBrkRngLmtgStatRed "0";
BA_REL_ "GenSigSuprvResp" BU_SG_REL_ ADIMb_PHS SG_ 311 PriBrkRngLmtgStatRed 1;
BA_REL_ "GenSigTimeoutMsg" BU_SG_REL_ ADIMb_PHS SG_ 311 PriBrkRngLmtgStatRed 311;
BA_REL_ "GenSigTimeoutTime" BU_SG_REL_ ADIMb_PHS SG_ 311 PriBrkRngLmtgStatRed 25;
BA_REL_ "GenSigRxStartValue" BU_SG_REL_ EBOOST_OBD_PHS SG_ 311 PriBrkRngLmtgStatRed "0";
BA_REL_ "GenSigSuprvResp" BU_SG_REL_ EBOOST_OBD_PHS SG_ 311 PriBrkRngLmtgStatRed 1;
BA_REL_ "GenSigTimeoutMsg" BU_SG_REL_ EBOOST_OBD_PHS SG_ 311 PriBrkRngLmtgStatRed 311;
BA_REL_ "GenSigTimeoutTime" BU_SG_REL_ EBOOST_OBD_PHS SG_ 311 PriBrkRngLmtgStatRed 25;
BA_REL_ "GenSigSuprvResp" BU_SG_REL_ EBOOST_OBD_PHS SG_ 311 ActrBrkFldFlwReq 1;
BA_REL_ "GenSigTimeoutMsg" BU_SG_REL_ EBOOST_OBD_PHS SG_ 311 ActrBrkFldFlwReq 311;
BA_REL_ "GenSigTimeoutTime" BU_SG_REL_ EBOOST_OBD_PHS SG_ 311 ActrBrkFldFlwReq 250;
BA_REL_ "GenSigSuprvResp" BU_SG_REL_ EBOOST_OBD_PHS SG_ 311 ActrBrkFldFlwReq 1;
BA_REL_ "GenSigTimeoutTime" BU_SG_REL_ EBOOST_OBD_PHS SG_ 311 ActrBrkFldFlwReq 25;
BA_REL_ "GenSigSuprvResp" BU_SG_REL_ EBOOST_OBD_PHS SG_ 311 ActrBrkFldFlwReqStat 1;
BA_REL_ "GenSigTimeoutMsg" BU_SG_REL_ EBOOST_OBD_PHS SG_ 311 ActrBrkFldFlwReqStat 311;
BA_REL_ "GenSigTimeoutTime" BU_SG_REL_ EBOOST_OBD_PHS SG_ 311 ActrBrkFldFlwReqStat 250;
BA_REL_ "GenSigSuprvResp" BU_SG_REL_ EBOOST_OBD_PHS SG_ 311 ABSAtv 1;
BA_REL_ "GenSigTimeoutMsg" BU_SG_REL_ EBOOST_OBD_PHS SG_ 311 ABSAtv 311;
BA_REL_ "GenSigTimeoutTime" BU_SG_REL_ EBOOST_OBD_PHS SG_ 311 ABSAtv 250;
BA_REL_ "GenSigSuprvResp" BU_SG_REL_ EBOOST_OBD_PHS SG_ 311 ABSAtv 1;
BA_REL_ "GenSigTimeoutTime" BU_SG_REL_ EBOOST_OBD_PHS SG_ 311 ABSAtv 25;
BA_REL_ "GenSigRxStartValue" BU_SG_REL_ EBOOST_OBD_PHS SG_ 311 PriBrkModCrtThrmlCapRed "0";
BA_REL_ "GenSigSuprvResp" BU_SG_REL_ EBOOST_OBD_PHS SG_ 311 PriBrkModCrtThrmlCapRed 1;
BA_REL_ "GenSigTimeoutMsg" BU_SG_REL_ EBOOST_OBD_PHS SG_ 311 PriBrkModCrtThrmlCapRed 311;
BA_REL_ "GenSigTimeoutTime" BU_SG_REL_ EBOOST_OBD_PHS SG_ 311 PriBrkModCrtThrmlCapRed 25;
BA_REL_ "GenSigRxStartValue" BU_SG_REL_ ADIMb_PHS SG_ 311 PriBrkModCrtThrmlCapRed "0";
BA_REL_ "GenSigSuprvResp" BU_SG_REL_ ADIMb_PHS SG_ 311 PriBrkModCrtThrmlCapRed 1;
BA_REL_ "GenSigTimeoutMsg" BU_SG_REL_ ADIMb_PHS SG_ 311 PriBrkModCrtThrmlCapRed 311;
BA_REL_ "GenSigTimeoutTime" BU_SG_REL_ ADIMb_PHS SG_ 311 PriBrkModCrtThrmlCapRed 25;
BA_REL_ "GenSigSuprvResp" BU_SG_REL_ EBOOST_OBD_PHS SG_ 311 EBCMhydctrlActRed 1;
BA_REL_ "GenSigTimeoutMsg" BU_SG_REL_ EBOOST_OBD_PHS SG_ 311 EBCMhydctrlActRed 311;
BA_REL_ "GenSigTimeoutTime" BU_SG_REL_ EBOOST_OBD_PHS SG_ 311 EBCMhydctrlActRed 250;
BA_REL_ "GenSigRxStartValue" BU_SG_REL_ EBOOST_OBD_PHS SG_ 311 PriDrvIntvtnMdDetTORed "False";
BA_REL_ "GenSigSuprvResp" BU_SG_REL_ EBOOST_OBD_PHS SG_ 311 PriDrvIntvtnMdDetTORed 1;
BA_REL_ "GenSigTimeoutMsg" BU_SG_REL_ EBOOST_OBD_PHS SG_ 311 PriDrvIntvtnMdDetTORed 311;
BA_REL_ "GenSigTimeoutTime" BU_SG_REL_ EBOOST_OBD_PHS SG_ 311 PriDrvIntvtnMdDetTORed 25;
BA_REL_ "GenSigRxStartValue" BU_SG_REL_ ADIMb_PHS SG_ 311 PriDrvIntvtnMdDetTORed "False";
BA_REL_ "GenSigSuprvResp" BU_SG_REL_ ADIMb_PHS SG_ 311 PriDrvIntvtnMdDetTORed 1;
BA_REL_ "GenSigTimeoutMsg" BU_SG_REL_ ADIMb_PHS SG_ 311 PriDrvIntvtnMdDetTORed 311;
BA_REL_ "GenSigTimeoutTime" BU_SG_REL_ ADIMb_PHS SG_ 311 PriDrvIntvtnMdDetTORed 25;
BA_REL_ "GenSigRxStartValue" BU_SG_REL_ ADIMb_PHS SG_ 403 SpltMuCntrlV "Valid";
BA_REL_ "GenSigVBitResp" BU_SG_REL_ ADIMb_PHS SG_ 403 SpltMuCntrl 1;
BA_REL_ "GenSigRxStartValue" BU_SG_REL_ ADIMb_PHS SG_ 403 SpltMuCntrl "Inactive";
BA_REL_ "GenSigSuprvResp" BU_SG_REL_ ADIMb_PHS SG_ 403 PriBrkModCapStat 1;
BA_REL_ "GenSigTimeoutMsg" BU_SG_REL_ ADIMb_PHS SG_ 403 PriBrkModCapStat 403;
BA_REL_ "GenSigTimeoutTime" BU_SG_REL_ ADIMb_PHS SG_ 403 PriBrkModCapStat 50;
BA_REL_ "GenSigRxStartValue" BU_SG_REL_ ADIMb_PHS SG_ 403 PriMaxAvlBrkTrqGrad "0";
BA_REL_ "GenSigSuprvResp" BU_SG_REL_ ADIMb_PHS SG_ 403 PriMaxAvlBrkTrqGrad 1;
BA_REL_ "GenSigTimeoutMsg" BU_SG_REL_ ADIMb_PHS SG_ 403 PriMaxAvlBrkTrqGrad 403;
BA_REL_ "GenSigTimeoutTime" BU_SG_REL_ ADIMb_PHS SG_ 403 PriMaxAvlBrkTrqGrad 50;
BA_REL_ "GenSigRxStartValue" BU_SG_REL_ ADIMb_PHS SG_ 403 PriMaxAvlBrkTrq "0";
BA_REL_ "GenSigSuprvResp" BU_SG_REL_ ADIMb_PHS SG_ 403 PriMaxAvlBrkTrq 1;
BA_REL_ "GenSigTimeoutMsg" BU_SG_REL_ ADIMb_PHS SG_ 403 PriMaxAvlBrkTrq 403;
BA_REL_ "GenSigTimeoutTime" BU_SG_REL_ ADIMb_PHS SG_ 403 PriMaxAvlBrkTrq 50;
BA_REL_ "GenSigSuprvResp" BU_SG_REL_ ADIMb_PHS SG_ 403 PriEstSrfcMuTyp 1;
BA_REL_ "GenSigTimeoutMsg" BU_SG_REL_ ADIMb_PHS SG_ 403 PriEstSrfcMuTyp 403;
BA_REL_ "GenSigTimeoutTime" BU_SG_REL_ ADIMb_PHS SG_ 403 PriEstSrfcMuTyp 50;
BA_REL_ "GenSigVBitResp" BU_SG_REL_ ADIMb_PHS SG_ 403 PriEstSrfcMuCap 1;
BA_REL_ "GenSigRxStartValue" BU_SG_REL_ ADIMb_PHS SG_ 403 PriEstSrfcMuCap "0";
BA_REL_ "GenSigSuprvResp" BU_SG_REL_ ADIMb_PHS SG_ 403 PriEstSrfcMuCap 1;
BA_REL_ "GenSigTimeoutMsg" BU_SG_REL_ ADIMb_PHS SG_ 403 PriEstSrfcMuCap 403;
BA_REL_ "GenSigTimeoutTime" BU_SG_REL_ ADIMb_PHS SG_ 403 PriEstSrfcMuCap 50;
BA_REL_ "GenSigRxStartValue" BU_SG_REL_ ADIMb_PHS SG_ 403 PriBrkSystCapChksm "0";
BA_REL_ "GenSigRxStartValue" BU_SG_REL_ ADIMb_PHS SG_ 403 PriBrkSysCapARC "0";
BA_REL_ "GenSigSuprvResp" BU_SG_REL_ EBOOST_OBD_PHS SG_ 190 PSBPI_PTSnBrkPdlPsV 1;
BA_REL_ "GenSigTimeoutMsg" BU_SG_REL_ EBOOST_OBD_PHS SG_ 190 PSBPI_PTSnBrkPdlPsV 190;
BA_REL_ "GenSigTimeoutTime" BU_SG_REL_ EBOOST_OBD_PHS SG_ 190 PSBPI_PTSnBrkPdlPsV 250;
BA_REL_ "GenSigSuprvResp" BU_SG_REL_ EBCM_PHS SG_ 190 PSBPI_PTSnBrkPdlPsV 1;
BA_REL_ "GenSigTimeoutMsg" BU_SG_REL_ EBCM_PHS SG_ 190 PSBPI_PTSnBrkPdlPsV 190;
BA_REL_ "GenSigTimeoutTime" BU_SG_REL_ EBCM_PHS SG_ 190 PSBPI_PTSnBrkPdlPsV 250;
BA_REL_ "GenSigSuprvResp" BU_SG_REL_ EBOOST_OBD_PHS SG_ 190 PSBPI_PTSnBrkPdlPs 1;
BA_REL_ "GenSigTimeoutMsg" BU_SG_REL_ EBOOST_OBD_PHS SG_ 190 PSBPI_PTSnBrkPdlPs 190;
BA_REL_ "GenSigTimeoutTime" BU_SG_REL_ EBOOST_OBD_PHS SG_ 190 PSBPI_PTSnBrkPdlPs 250;
BA_REL_ "GenSigSuprvResp" BU_SG_REL_ EBCM_PHS SG_ 190 PSBPI_PTSnBrkPdlPs 1;
BA_REL_ "GenSigTimeoutMsg" BU_SG_REL_ EBCM_PHS SG_ 190 PSBPI_PTSnBrkPdlPs 190;
BA_REL_ "GenSigTimeoutTime" BU_SG_REL_ EBCM_PHS SG_ 190 PSBPI_PTSnBrkPdlPs 250;
BA_REL_ "GenSigVBitResp" BU_SG_REL_ EOCM2cp_IMX6_PHS SG_ 288 VehOdo 1;
BA_REL_ "GenSigSuprvResp" BU_SG_REL_ EOCM2cp_IMX6_PHS SG_ 288 VehOdo 1;
BA_REL_ "GenSigTimeoutMsg" BU_SG_REL_ EOCM2cp_IMX6_PHS SG_ 288 VehOdo 288;
BA_REL_ "GenSigTimeoutTime" BU_SG_REL_ EOCM2cp_IMX6_PHS SG_ 288 VehOdo 12500;
BA_REL_ "GenSigVBitResp" BU_SG_REL_ EBOOST_OBD_PHS SG_ 288 VehOdo 1;
BA_REL_ "GenSigSuprvResp" BU_SG_REL_ EBOOST_OBD_PHS SG_ 288 VehOdo 1;
BA_REL_ "GenSigTimeoutMsg" BU_SG_REL_ EBOOST_OBD_PHS SG_ 288 VehOdo 288;
BA_REL_ "GenSigTimeoutTime" BU_SG_REL_ EBOOST_OBD_PHS SG_ 288 VehOdo 12500;
BA_REL_ "GenSigVBitResp" BU_SG_REL_ EBCM_PHS SG_ 288 VehOdo 1;
BA_REL_ "GenSigSuprvResp" BU_SG_REL_ EBCM_PHS SG_ 288 VehOdo 1;
BA_REL_ "GenSigTimeoutMsg" BU_SG_REL_ EBCM_PHS SG_ 288 VehOdo 288;
BA_REL_ "GenSigTimeoutTime" BU_SG_REL_ EBCM_PHS SG_ 288 VehOdo 12500;
BA_REL_ "GenSigRxStartValue" BU_SG_REL_ ADIMb_PHS SG_ 348 SecCoPCmdMsgStat "Normal Communication";
BA_REL_ "GenSigSuprvResp" BU_SG_REL_ ADIMb_PHS SG_ 348 SecCoPCmdMsgStat 1;
BA_REL_ "GenSigTimeoutMsg" BU_SG_REL_ ADIMb_PHS SG_ 348 SecCoPCmdMsgStat 348;
BA_REL_ "GenSigTimeoutTime" BU_SG_REL_ ADIMb_PHS SG_ 348 SecCoPCmdMsgStat 25;
BA_REL_ "GenSigRxStartValue" BU_SG_REL_ EBCM_PHS SG_ 348 SecCoPCmdMsgStat "Normal Communication";
BA_REL_ "GenSigSuprvResp" BU_SG_REL_ EBCM_PHS SG_ 348 SecCoPCmdMsgStat 1;
BA_REL_ "GenSigTimeoutMsg" BU_SG_REL_ EBCM_PHS SG_ 348 SecCoPCmdMsgStat 348;
BA_REL_ "GenSigTimeoutTime" BU_SG_REL_ EBCM_PHS SG_ 348 SecCoPCmdMsgStat 25;
BA_REL_ "GenSigRxStartValue" BU_SG_REL_ ADIMb_PHS SG_ 348 SecBrkSysArbStat "Unknown";
BA_REL_ "GenSigSuprvResp" BU_SG_REL_ ADIMb_PHS SG_ 348 SecBrkSysArbStat 1;
BA_REL_ "GenSigTimeoutMsg" BU_SG_REL_ ADIMb_PHS SG_ 348 SecBrkSysArbStat 348;
BA_REL_ "GenSigTimeoutTime" BU_SG_REL_ ADIMb_PHS SG_ 348 SecBrkSysArbStat 25;
BA_REL_ "GenSigRxStartValue" BU_SG_REL_ EBCM_PHS SG_ 348 SecBrkSysArbStat "Unknown";
BA_REL_ "GenSigSuprvResp" BU_SG_REL_ EBCM_PHS SG_ 348 SecBrkSysArbStat 1;
BA_REL_ "GenSigTimeoutMsg" BU_SG_REL_ EBCM_PHS SG_ 348 SecBrkSysArbStat 348;
BA_REL_ "GenSigTimeoutTime" BU_SG_REL_ EBCM_PHS SG_ 348 SecBrkSysArbStat 25;
BA_REL_ "GenSigRxStartValue" BU_SG_REL_ ADIMb_PHS SG_ 348 SecADSCmdMsgStat "Normal Communication";
BA_REL_ "GenSigSuprvResp" BU_SG_REL_ ADIMb_PHS SG_ 348 SecADSCmdMsgStat 1;
BA_REL_ "GenSigTimeoutMsg" BU_SG_REL_ ADIMb_PHS SG_ 348 SecADSCmdMsgStat 348;
BA_REL_ "GenSigTimeoutTime" BU_SG_REL_ ADIMb_PHS SG_ 348 SecADSCmdMsgStat 25;
BA_REL_ "GenSigRxStartValue" BU_SG_REL_ EBCM_PHS SG_ 348 SecADSCmdMsgStat "Normal Communication";
BA_REL_ "GenSigSuprvResp" BU_SG_REL_ EBCM_PHS SG_ 348 SecADSCmdMsgStat 1;
BA_REL_ "GenSigTimeoutMsg" BU_SG_REL_ EBCM_PHS SG_ 348 SecADSCmdMsgStat 348;
BA_REL_ "GenSigTimeoutTime" BU_SG_REL_ EBCM_PHS SG_ 348 SecADSCmdMsgStat 25;
BA_REL_ "GenSigSuprvResp" BU_SG_REL_ EBCM_PHS SG_ 348 StrkOtptRodTgtQlfr 1;
BA_REL_ "GenSigTimeoutMsg" BU_SG_REL_ EBCM_PHS SG_ 348 StrkOtptRodTgtQlfr 348;
BA_REL_ "GenSigTimeoutTime" BU_SG_REL_ EBCM_PHS SG_ 348 StrkOtptRodTgtQlfr 25;
BA_REL_ "GenSigSuprvResp" BU_SG_REL_ ADIMb_PHS SG_ 348 StrkOtptRodTgtQlfr 1;
BA_REL_ "GenSigTimeoutMsg" BU_SG_REL_ ADIMb_PHS SG_ 348 StrkOtptRodTgtQlfr 348;
BA_REL_ "GenSigTimeoutTime" BU_SG_REL_ ADIMb_PHS SG_ 348 StrkOtptRodTgtQlfr 25;
BA_REL_ "GenSigSuprvResp" BU_SG_REL_ EBCM_PHS SG_ 348 StrkOtptRodTgt 1;
BA_REL_ "GenSigTimeoutMsg" BU_SG_REL_ EBCM_PHS SG_ 348 StrkOtptRodTgt 348;
BA_REL_ "GenSigTimeoutTime" BU_SG_REL_ EBCM_PHS SG_ 348 StrkOtptRodTgt 25;
BA_REL_ "GenSigSuprvResp" BU_SG_REL_ ADIMb_PHS SG_ 348 StrkOtptRodTgt 1;
BA_REL_ "GenSigTimeoutMsg" BU_SG_REL_ ADIMb_PHS SG_ 348 StrkOtptRodTgt 348;
BA_REL_ "GenSigTimeoutTime" BU_SG_REL_ ADIMb_PHS SG_ 348 StrkOtptRodTgt 25;
BA_REL_ "GenSigSuprvResp" BU_SG_REL_ EBCM_PHS SG_ 348 StrkOtptRodActlQlfr 1;
BA_REL_ "GenSigTimeoutMsg" BU_SG_REL_ EBCM_PHS SG_ 348 StrkOtptRodActlQlfr 348;
BA_REL_ "GenSigTimeoutTime" BU_SG_REL_ EBCM_PHS SG_ 348 StrkOtptRodActlQlfr 25;
BA_REL_ "GenSigSuprvResp" BU_SG_REL_ ADIMb_PHS SG_ 348 StrkOtptRodActlQlfr 1;
BA_REL_ "GenSigTimeoutMsg" BU_SG_REL_ ADIMb_PHS SG_ 348 StrkOtptRodActlQlfr 348;
BA_REL_ "GenSigTimeoutTime" BU_SG_REL_ ADIMb_PHS SG_ 348 StrkOtptRodActlQlfr 25;
BA_REL_ "GenSigSuprvResp" BU_SG_REL_ EBCM_PHS SG_ 348 StrkOtptRodActl 1;
BA_REL_ "GenSigTimeoutMsg" BU_SG_REL_ EBCM_PHS SG_ 348 StrkOtptRodActl 348;
BA_REL_ "GenSigTimeoutTime" BU_SG_REL_ EBCM_PHS SG_ 348 StrkOtptRodActl 25;
BA_REL_ "GenSigSuprvResp" BU_SG_REL_ ADIMb_PHS SG_ 348 StrkOtptRodActl 1;
BA_REL_ "GenSigTimeoutMsg" BU_SG_REL_ ADIMb_PHS SG_ 348 StrkOtptRodActl 348;
BA_REL_ "GenSigTimeoutTime" BU_SG_REL_ ADIMb_PHS SG_ 348 StrkOtptRodActl 25;
BA_REL_ "GenSigRxStartValue" BU_SG_REL_ EBCM_PHS SG_ 348 SecBrkSysStatChksm "0";
BA_REL_ "GenSigRxStartValue" BU_SG_REL_ ADIMb_PHS SG_ 348 SecBrkSysStatChksm "0";
BA_REL_ "GenSigRxStartValue" BU_SG_REL_ EBCM_PHS SG_ 348 SecBrkSysStatARC "0";
BA_REL_ "GenSigRxStartValue" BU_SG_REL_ ADIMb_PHS SG_ 348 SecBrkSysStatARC "0";
BA_REL_ "GenSigRxStartValue" BU_SG_REL_ EBCM_PHS SG_ 348 SecBrkModSbSte "0";
BA_REL_ "GenSigSuprvResp" BU_SG_REL_ EBCM_PHS SG_ 348 SecBrkModSbSte 1;
BA_REL_ "GenSigTimeoutMsg" BU_SG_REL_ EBCM_PHS SG_ 348 SecBrkModSbSte 348;
BA_REL_ "GenSigTimeoutTime" BU_SG_REL_ EBCM_PHS SG_ 348 SecBrkModSbSte 25;
BA_REL_ "GenSigRxStartValue" BU_SG_REL_ ADIMb_PHS SG_ 348 SecBrkModSbSte "0";
BA_REL_ "GenSigSuprvResp" BU_SG_REL_ ADIMb_PHS SG_ 348 SecBrkModSbSte 1;
BA_REL_ "GenSigTimeoutMsg" BU_SG_REL_ ADIMb_PHS SG_ 348 SecBrkModSbSte 348;
BA_REL_ "GenSigTimeoutTime" BU_SG_REL_ ADIMb_PHS SG_ 348 SecBrkModSbSte 25;
BA_REL_ "GenSigRxStartValue" BU_SG_REL_ EBCM_PHS SG_ 348 SecBrkSysStat "0";
BA_REL_ "GenSigSuprvResp" BU_SG_REL_ EBCM_PHS SG_ 348 SecBrkSysStat 1;
BA_REL_ "GenSigTimeoutMsg" BU_SG_REL_ EBCM_PHS SG_ 348 SecBrkSysStat 348;
BA_REL_ "GenSigTimeoutTime" BU_SG_REL_ EBCM_PHS SG_ 348 SecBrkSysStat 25;
BA_REL_ "GenSigRxStartValue" BU_SG_REL_ ADIMb_PHS SG_ 348 SecBrkSysStat "0";
BA_REL_ "GenSigSuprvResp" BU_SG_REL_ ADIMb_PHS SG_ 348 SecBrkSysStat 1;
BA_REL_ "GenSigTimeoutMsg" BU_SG_REL_ ADIMb_PHS SG_ 348 SecBrkSysStat 348;
BA_REL_ "GenSigTimeoutTime" BU_SG_REL_ ADIMb_PHS SG_ 348 SecBrkSysStat 25;
BA_REL_ "GenSigRxStartValue" BU_SG_REL_ EBCM_PHS SG_ 348 SecBrkRngLmtgStat "0";
BA_REL_ "GenSigSuprvResp" BU_SG_REL_ EBCM_PHS SG_ 348 SecBrkRngLmtgStat 1;
BA_REL_ "GenSigTimeoutMsg" BU_SG_REL_ EBCM_PHS SG_ 348 SecBrkRngLmtgStat 348;
BA_REL_ "GenSigTimeoutTime" BU_SG_REL_ EBCM_PHS SG_ 348 SecBrkRngLmtgStat 25;
BA_REL_ "GenSigRxStartValue" BU_SG_REL_ ADIMb_PHS SG_ 348 SecBrkRngLmtgStat "0";
BA_REL_ "GenSigSuprvResp" BU_SG_REL_ ADIMb_PHS SG_ 348 SecBrkRngLmtgStat 1;
BA_REL_ "GenSigTimeoutMsg" BU_SG_REL_ ADIMb_PHS SG_ 348 SecBrkRngLmtgStat 348;
BA_REL_ "GenSigTimeoutTime" BU_SG_REL_ ADIMb_PHS SG_ 348 SecBrkRngLmtgStat 25;
BA_REL_ "GenSigRxStartValue" BU_SG_REL_ EBCM_PHS SG_ 348 SecBrkModCrtThrmlCap "0";
BA_REL_ "GenSigSuprvResp" BU_SG_REL_ EBCM_PHS SG_ 348 SecBrkModCrtThrmlCap 1;
BA_REL_ "GenSigTimeoutMsg" BU_SG_REL_ EBCM_PHS SG_ 348 SecBrkModCrtThrmlCap 348;
BA_REL_ "GenSigTimeoutTime" BU_SG_REL_ EBCM_PHS SG_ 348 SecBrkModCrtThrmlCap 25;
BA_REL_ "GenSigRxStartValue" BU_SG_REL_ ADIMb_PHS SG_ 348 SecBrkModCrtThrmlCap "0";
BA_REL_ "GenSigSuprvResp" BU_SG_REL_ ADIMb_PHS SG_ 348 SecBrkModCrtThrmlCap 1;
BA_REL_ "GenSigTimeoutMsg" BU_SG_REL_ ADIMb_PHS SG_ 348 SecBrkModCrtThrmlCap 348;
BA_REL_ "GenSigTimeoutTime" BU_SG_REL_ ADIMb_PHS SG_ 348 SecBrkModCrtThrmlCap 25;
BA_REL_ "GenSigRxStartValue" BU_SG_REL_ EBCM_PHS SG_ 348 SecDrvIntvtnMdDetTO "False";
BA_REL_ "GenSigSuprvResp" BU_SG_REL_ EBCM_PHS SG_ 348 SecDrvIntvtnMdDetTO 1;
BA_REL_ "GenSigTimeoutMsg" BU_SG_REL_ EBCM_PHS SG_ 348 SecDrvIntvtnMdDetTO 348;
BA_REL_ "GenSigTimeoutTime" BU_SG_REL_ EBCM_PHS SG_ 348 SecDrvIntvtnMdDetTO 25;
BA_REL_ "GenSigRxStartValue" BU_SG_REL_ ADIMb_PHS SG_ 348 SecDrvIntvtnMdDetTO "False";
BA_REL_ "GenSigSuprvResp" BU_SG_REL_ ADIMb_PHS SG_ 348 SecDrvIntvtnMdDetTO 1;
BA_REL_ "GenSigTimeoutMsg" BU_SG_REL_ ADIMb_PHS SG_ 348 SecDrvIntvtnMdDetTO 348;
BA_REL_ "GenSigTimeoutTime" BU_SG_REL_ ADIMb_PHS SG_ 348 SecDrvIntvtnMdDetTO 25;
BA_REL_ "GenSigSuprvResp" BU_SG_REL_ EBCM_PHS SG_ 500 EnhDrvMdSwChUseAct 1;
BA_REL_ "GenSigTimeoutMsg" BU_SG_REL_ EBCM_PHS SG_ 500 EnhDrvMdSwChUseAct 500;
BA_REL_ "GenSigTimeoutTime" BU_SG_REL_ EBCM_PHS SG_ 500 EnhDrvMdSwChUseAct 500;
BA_REL_ "GenSigSuprvResp" BU_SG_REL_ EBCM_PHS SG_ 500 EnhDrvSelMdSwStat 1;
BA_REL_ "GenSigTimeoutMsg" BU_SG_REL_ EBCM_PHS SG_ 500 EnhDrvSelMdSwStat 500;
BA_REL_ "GenSigTimeoutTime" BU_SG_REL_ EBCM_PHS SG_ 500 EnhDrvSelMdSwStat 500;
BA_REL_ "GenSigSuprvResp" BU_SG_REL_ EBCM_PHS SG_ 500 DrvSelMd8Stat 1;
BA_REL_ "GenSigTimeoutMsg" BU_SG_REL_ EBCM_PHS SG_ 500 DrvSelMd8Stat 500;
BA_REL_ "GenSigTimeoutTime" BU_SG_REL_ EBCM_PHS SG_ 500 DrvSelMd8Stat 500;
BA_REL_ "GenSigSuprvResp" BU_SG_REL_ EBCM_PHS SG_ 500 DrvSelMd7Stat 1;
BA_REL_ "GenSigTimeoutMsg" BU_SG_REL_ EBCM_PHS SG_ 500 DrvSelMd7Stat 500;
BA_REL_ "GenSigTimeoutTime" BU_SG_REL_ EBCM_PHS SG_ 500 DrvSelMd7Stat 500;
BA_REL_ "GenSigSuprvResp" BU_SG_REL_ EBCM_PHS SG_ 500 DrvSelMd6Stat 1;
BA_REL_ "GenSigTimeoutMsg" BU_SG_REL_ EBCM_PHS SG_ 500 DrvSelMd6Stat 500;
BA_REL_ "GenSigTimeoutTime" BU_SG_REL_ EBCM_PHS SG_ 500 DrvSelMd6Stat 500;
BA_REL_ "GenSigSuprvResp" BU_SG_REL_ EBCM_PHS SG_ 500 DrvSelMd5Stat 1;
BA_REL_ "GenSigTimeoutMsg" BU_SG_REL_ EBCM_PHS SG_ 500 DrvSelMd5Stat 500;
BA_REL_ "GenSigTimeoutTime" BU_SG_REL_ EBCM_PHS SG_ 500 DrvSelMd5Stat 500;
BA_REL_ "GenSigSuprvResp" BU_SG_REL_ EBCM_PHS SG_ 500 DrvSelMd4Stat 1;
BA_REL_ "GenSigTimeoutMsg" BU_SG_REL_ EBCM_PHS SG_ 500 DrvSelMd4Stat 500;
BA_REL_ "GenSigTimeoutTime" BU_SG_REL_ EBCM_PHS SG_ 500 DrvSelMd4Stat 500;
BA_REL_ "GenSigSuprvResp" BU_SG_REL_ EBCM_PHS SG_ 500 DrvSelMd3Stat 1;
BA_REL_ "GenSigTimeoutMsg" BU_SG_REL_ EBCM_PHS SG_ 500 DrvSelMd3Stat 500;
BA_REL_ "GenSigTimeoutTime" BU_SG_REL_ EBCM_PHS SG_ 500 DrvSelMd3Stat 500;
BA_REL_ "GenSigSuprvResp" BU_SG_REL_ EBCM_PHS SG_ 500 DrvSelMd2Stat 1;
BA_REL_ "GenSigTimeoutMsg" BU_SG_REL_ EBCM_PHS SG_ 500 DrvSelMd2Stat 500;
BA_REL_ "GenSigTimeoutTime" BU_SG_REL_ EBCM_PHS SG_ 500 DrvSelMd2Stat 500;
BA_REL_ "GenSigSuprvResp" BU_SG_REL_ EBCM_PHS SG_ 500 DSMSS_DrvSelMd0Pn 1;
BA_REL_ "GenSigTimeoutMsg" BU_SG_REL_ EBCM_PHS SG_ 500 DSMSS_DrvSelMd0Pn 500;
BA_REL_ "GenSigTimeoutTime" BU_SG_REL_ EBCM_PHS SG_ 500 DSMSS_DrvSelMd0Pn 500;
BA_REL_ "GenSigSuprvResp" BU_SG_REL_ EBCM_PHS SG_ 500 DSMSS_DrvSelMd8Pn 1;
BA_REL_ "GenSigTimeoutMsg" BU_SG_REL_ EBCM_PHS SG_ 500 DSMSS_DrvSelMd8Pn 500;
BA_REL_ "GenSigTimeoutTime" BU_SG_REL_ EBCM_PHS SG_ 500 DSMSS_DrvSelMd8Pn 500;
BA_REL_ "GenSigSuprvResp" BU_SG_REL_ EBCM_PHS SG_ 500 DSMSS_DrvSelMd7Pn 1;
BA_REL_ "GenSigTimeoutMsg" BU_SG_REL_ EBCM_PHS SG_ 500 DSMSS_DrvSelMd7Pn 500;
BA_REL_ "GenSigTimeoutTime" BU_SG_REL_ EBCM_PHS SG_ 500 DSMSS_DrvSelMd7Pn 500;
BA_REL_ "GenSigSuprvResp" BU_SG_REL_ EBCM_PHS SG_ 500 DSMSS_DrvSelMd6Pn 1;
BA_REL_ "GenSigTimeoutMsg" BU_SG_REL_ EBCM_PHS SG_ 500 DSMSS_DrvSelMd6Pn 500;
BA_REL_ "GenSigTimeoutTime" BU_SG_REL_ EBCM_PHS SG_ 500 DSMSS_DrvSelMd6Pn 500;
BA_REL_ "GenSigSuprvResp" BU_SG_REL_ EBCM_PHS SG_ 500 DSMSS_DrvSelMd5Pn 1;
BA_REL_ "GenSigTimeoutMsg" BU_SG_REL_ EBCM_PHS SG_ 500 DSMSS_DrvSelMd5Pn 500;
BA_REL_ "GenSigTimeoutTime" BU_SG_REL_ EBCM_PHS SG_ 500 DSMSS_DrvSelMd5Pn 500;
BA_REL_ "GenSigSuprvResp" BU_SG_REL_ EBCM_PHS SG_ 500 DSMSS_DrvSelMd4Pn 1;
BA_REL_ "GenSigTimeoutMsg" BU_SG_REL_ EBCM_PHS SG_ 500 DSMSS_DrvSelMd4Pn 500;
BA_REL_ "GenSigTimeoutTime" BU_SG_REL_ EBCM_PHS SG_ 500 DSMSS_DrvSelMd4Pn 500;
BA_REL_ "GenSigSuprvResp" BU_SG_REL_ EBCM_PHS SG_ 500 DSMSS_DrvSelMd3Pn 1;
BA_REL_ "GenSigTimeoutMsg" BU_SG_REL_ EBCM_PHS SG_ 500 DSMSS_DrvSelMd3Pn 500;
BA_REL_ "GenSigTimeoutTime" BU_SG_REL_ EBCM_PHS SG_ 500 DSMSS_DrvSelMd3Pn 500;
BA_REL_ "GenSigSuprvResp" BU_SG_REL_ EBCM_PHS SG_ 500 DSMSS_DrvSelMd2Pn 1;
BA_REL_ "GenSigTimeoutMsg" BU_SG_REL_ EBCM_PHS SG_ 500 DSMSS_DrvSelMd2Pn 500;
BA_REL_ "GenSigTimeoutTime" BU_SG_REL_ EBCM_PHS SG_ 500 DSMSS_DrvSelMd2Pn 500;
BA_REL_ "GenSigSuprvResp" BU_SG_REL_ EBCM_PHS SG_ 500 DSMSS_DrvSelMd1Pn 1;
BA_REL_ "GenSigTimeoutMsg" BU_SG_REL_ EBCM_PHS SG_ 500 DSMSS_DrvSelMd1Pn 500;
BA_REL_ "GenSigTimeoutTime" BU_SG_REL_ EBCM_PHS SG_ 500 DSMSS_DrvSelMd1Pn 500;
BA_REL_ "GenSigSuprvResp" BU_SG_REL_ EBCM_PHS SG_ 500 DSMSS_DrvSelMd8Un 1;
BA_REL_ "GenSigTimeoutMsg" BU_SG_REL_ EBCM_PHS SG_ 500 DSMSS_DrvSelMd8Un 500;
BA_REL_ "GenSigTimeoutTime" BU_SG_REL_ EBCM_PHS SG_ 500 DSMSS_DrvSelMd8Un 500;
BA_REL_ "GenSigSuprvResp" BU_SG_REL_ EBCM_PHS SG_ 500 DSMSS_DrvSelMd7Un 1;
BA_REL_ "GenSigTimeoutMsg" BU_SG_REL_ EBCM_PHS SG_ 500 DSMSS_DrvSelMd7Un 500;
BA_REL_ "GenSigTimeoutTime" BU_SG_REL_ EBCM_PHS SG_ 500 DSMSS_DrvSelMd7Un 500;
BA_REL_ "GenSigSuprvResp" BU_SG_REL_ EBCM_PHS SG_ 500 DSMSS_DrvSelMd6Un 1;
BA_REL_ "GenSigTimeoutMsg" BU_SG_REL_ EBCM_PHS SG_ 500 DSMSS_DrvSelMd6Un 500;
BA_REL_ "GenSigTimeoutTime" BU_SG_REL_ EBCM_PHS SG_ 500 DSMSS_DrvSelMd6Un 500;
BA_REL_ "GenSigSuprvResp" BU_SG_REL_ EBCM_PHS SG_ 500 DSMSS_DrvSelMd5Un 1;
BA_REL_ "GenSigTimeoutMsg" BU_SG_REL_ EBCM_PHS SG_ 500 DSMSS_DrvSelMd5Un 500;
BA_REL_ "GenSigTimeoutTime" BU_SG_REL_ EBCM_PHS SG_ 500 DSMSS_DrvSelMd5Un 500;
BA_REL_ "GenSigSuprvResp" BU_SG_REL_ EBCM_PHS SG_ 500 DSMSS_DrvSelMd4Un 1;
BA_REL_ "GenSigTimeoutMsg" BU_SG_REL_ EBCM_PHS SG_ 500 DSMSS_DrvSelMd4Un 500;
BA_REL_ "GenSigTimeoutTime" BU_SG_REL_ EBCM_PHS SG_ 500 DSMSS_DrvSelMd4Un 500;
BA_REL_ "GenSigSuprvResp" BU_SG_REL_ EBCM_PHS SG_ 500 DSMSS_DrvSelMd3Un 1;
BA_REL_ "GenSigTimeoutMsg" BU_SG_REL_ EBCM_PHS SG_ 500 DSMSS_DrvSelMd3Un 500;
BA_REL_ "GenSigTimeoutTime" BU_SG_REL_ EBCM_PHS SG_ 500 DSMSS_DrvSelMd3Un 500;
BA_REL_ "GenSigSuprvResp" BU_SG_REL_ EBCM_PHS SG_ 500 DSMSS_DrvSelMd2Un 1;
BA_REL_ "GenSigTimeoutMsg" BU_SG_REL_ EBCM_PHS SG_ 500 DSMSS_DrvSelMd2Un 500;
BA_REL_ "GenSigTimeoutTime" BU_SG_REL_ EBCM_PHS SG_ 500 DSMSS_DrvSelMd2Un 500;
BA_REL_ "GenSigSuprvResp" BU_SG_REL_ EBCM_PHS SG_ 500 DSMSS_DrvSelMd1Un 1;
BA_REL_ "GenSigTimeoutMsg" BU_SG_REL_ EBCM_PHS SG_ 500 DSMSS_DrvSelMd1Un 500;
BA_REL_ "GenSigTimeoutTime" BU_SG_REL_ EBCM_PHS SG_ 500 DSMSS_DrvSelMd1Un 500;
BA_REL_ "GenSigSuprvResp" BU_SG_REL_ EBCM_PHS SG_ 500 DrvSelMd1Stat 1;
BA_REL_ "GenSigTimeoutMsg" BU_SG_REL_ EBCM_PHS SG_ 500 DrvSelMd1Stat 500;
BA_REL_ "GenSigTimeoutTime" BU_SG_REL_ EBCM_PHS SG_ 500 DrvSelMd1Stat 500;
BA_REL_ "GenSigSuprvResp" BU_SG_REL_ EBCM_PHS SG_ 352 AVHSwtchStats 1;
BA_REL_ "GenSigTimeoutMsg" BU_SG_REL_ EBCM_PHS SG_ 352 AVHSwtchStats 352;
BA_REL_ "GenSigTimeoutTime" BU_SG_REL_ EBCM_PHS SG_ 352 AVHSwtchStats 500;
BA_REL_ "GenSigSuprvResp" BU_SG_REL_ EBCM_PHS SG_ 352 TeenDrvAct 1;
BA_REL_ "GenSigTimeoutMsg" BU_SG_REL_ EBCM_PHS SG_ 352 TeenDrvAct 352;
BA_REL_ "GenSigTimeoutTime" BU_SG_REL_ EBCM_PHS SG_ 352 TeenDrvAct 500;
BA_REL_ "GenSigSuprvResp" BU_SG_REL_ EBCM_PHS SG_ 352 LrnEnvIdSt 1;
BA_REL_ "GenSigTimeoutMsg" BU_SG_REL_ EBCM_PHS SG_ 352 LrnEnvIdSt 352;
BA_REL_ "GenSigTimeoutTime" BU_SG_REL_ EBCM_PHS SG_ 352 LrnEnvIdSt 500;
BA_REL_ "GenSigSuprvResp" BU_SG_REL_ EBCM_PHS SG_ 352 LrnEnvId 1;
BA_REL_ "GenSigTimeoutMsg" BU_SG_REL_ EBCM_PHS SG_ 352 LrnEnvId 352;
BA_REL_ "GenSigTimeoutTime" BU_SG_REL_ EBCM_PHS SG_ 352 LrnEnvId 500;
BA_REL_ "GenSigSuprvResp" BU_SG_REL_ EBCM_PHS SG_ 352 ImoId 1;
BA_REL_ "GenSigTimeoutMsg" BU_SG_REL_ EBCM_PHS SG_ 352 ImoId 352;
BA_REL_ "GenSigTimeoutTime" BU_SG_REL_ EBCM_PHS SG_ 352 ImoId 500;
BA_REL_ "GenSigSuprvResp" BU_SG_REL_ EBCM_PHS SG_ 352 ImoIdSt 1;
BA_REL_ "GenSigTimeoutMsg" BU_SG_REL_ EBCM_PHS SG_ 352 ImoIdSt 352;
BA_REL_ "GenSigTimeoutTime" BU_SG_REL_ EBCM_PHS SG_ 352 ImoIdSt 500;
BA_REL_ "GenSigSuprvResp" BU_SG_REL_ EBCM_PHS SG_ 554 ElecPrkBrkAvailStat 1;
BA_REL_ "GenSigTimeoutMsg" BU_SG_REL_ EBCM_PHS SG_ 554 ElecPrkBrkAvailStat 554;
BA_REL_ "GenSigTimeoutTime" BU_SG_REL_ EBCM_PHS SG_ 554 ElecPrkBrkAvailStat 500;
BA_REL_ "GenSigSuprvResp" BU_SG_REL_ EBCM_PHS SG_ 554 ElecPrkBrkApplStat 1;
BA_REL_ "GenSigTimeoutMsg" BU_SG_REL_ EBCM_PHS SG_ 554 ElecPrkBrkApplStat 554;
BA_REL_ "GenSigTimeoutTime" BU_SG_REL_ EBCM_PHS SG_ 554 ElecPrkBrkApplStat 500;
BA_REL_ "GenSigSuprvResp" BU_SG_REL_ EBCM_PHS SG_ 566 ChrgSysPrkBrkAnmsBrkReq 1;
BA_REL_ "GenSigTimeoutMsg" BU_SG_REL_ EBCM_PHS SG_ 566 ChrgSysPrkBrkAnmsBrkReq 566;
BA_REL_ "GenSigTimeoutTime" BU_SG_REL_ EBCM_PHS SG_ 566 ChrgSysPrkBrkAnmsBrkReq 500;
BA_REL_ "GenSigRxStartValue" BU_SG_REL_ ADIMb_PHS SG_ 401 SecMaxAvlBrkTrqGrad "0";
BA_REL_ "GenSigSuprvResp" BU_SG_REL_ ADIMb_PHS SG_ 401 SecMaxAvlBrkTrqGrad 1;
BA_REL_ "GenSigTimeoutMsg" BU_SG_REL_ ADIMb_PHS SG_ 401 SecMaxAvlBrkTrqGrad 401;
BA_REL_ "GenSigTimeoutTime" BU_SG_REL_ ADIMb_PHS SG_ 401 SecMaxAvlBrkTrqGrad 50;
BA_REL_ "GenSigRxStartValue" BU_SG_REL_ ADIMb_PHS SG_ 401 SecMaxAvlBrkTrq "0";
BA_REL_ "GenSigSuprvResp" BU_SG_REL_ ADIMb_PHS SG_ 401 SecMaxAvlBrkTrq 1;
BA_REL_ "GenSigTimeoutMsg" BU_SG_REL_ ADIMb_PHS SG_ 401 SecMaxAvlBrkTrq 401;
BA_REL_ "GenSigTimeoutTime" BU_SG_REL_ ADIMb_PHS SG_ 401 SecMaxAvlBrkTrq 50;
BA_REL_ "GenSigRxStartValue" BU_SG_REL_ ADIMb_PHS SG_ 401 SecBrkSystCapChksm "0";
BA_REL_ "GenSigRxStartValue" BU_SG_REL_ ADIMb_PHS SG_ 401 SecBrkSysCapARC "0";
BA_REL_ "GenSigSuprvResp" BU_SG_REL_ ADIMb_PHS SG_ 401 SecEstSrfcMuTyp 1;
BA_REL_ "GenSigTimeoutMsg" BU_SG_REL_ ADIMb_PHS SG_ 401 SecEstSrfcMuTyp 401;
BA_REL_ "GenSigTimeoutTime" BU_SG_REL_ ADIMb_PHS SG_ 401 SecEstSrfcMuTyp 50;
BA_REL_ "GenSigRxStartValue" BU_SG_REL_ ADIMb_PHS SG_ 401 SecEstSrfcMuCapV "Valid";
BA_REL_ "GenSigVBitResp" BU_SG_REL_ ADIMb_PHS SG_ 401 SecEstSrfcMuCap 1;
BA_REL_ "GenSigRxStartValue" BU_SG_REL_ ADIMb_PHS SG_ 401 SecEstSrfcMuCap "0";
BA_REL_ "GenSigSuprvResp" BU_SG_REL_ ADIMb_PHS SG_ 401 SecEstSrfcMuCap 1;
BA_REL_ "GenSigTimeoutMsg" BU_SG_REL_ ADIMb_PHS SG_ 401 SecEstSrfcMuCap 401;
BA_REL_ "GenSigTimeoutTime" BU_SG_REL_ ADIMb_PHS SG_ 401 SecEstSrfcMuCap 50;
BA_REL_ "GenSigSuprvResp" BU_SG_REL_ EBCM_PHS SG_ 320 TrnSwAct 1;
BA_REL_ "GenSigTimeoutMsg" BU_SG_REL_ EBCM_PHS SG_ 320 TrnSwAct 320;
BA_REL_ "GenSigTimeoutTime" BU_SG_REL_ EBCM_PHS SG_ 320 TrnSwAct 2500;
VAL_ 1008 SecuredVehSpdSrcDrvn 3 "Transmission Output Speed" 2 "Averaged Driven Wheel Speed" 1 "Motor RPM" 0 " No Source Available" ;
VAL_ 1008 SecuredVehSpdAvlblDrvn 1 "true" 0 "false" ;
VAL_ 1008 SecuredVehSpdDrvnV 1 "Invalid" 0 "Valid" ;
VAL_ 647 CrnksftTqModRspMxCapV 1 "Invalid" 0 "Valid" ;
VAL_ 647 EngDetPndTrnCsRngShfV 1 "Invalid" 0 "Valid" ;
VAL_ 647 EngDetPndTrnCsRngShf 3 "Shift Out of Neutral Range" 2 "Shift Out of Low Range" 1 "Shift Out of High Range" 0 "None" ;
VAL_ 647 CrpCstCrvCmd 7 "Creep Coast Curve 7" 6 "Creep Coast Curve 6" 5 "Creep Coast Curve 5" 4 "Creep Coast Curve 4" 3 "Creep Coast Curve 3" 2 "Creep Coast Curve 2" 1 "Creep Coast Curve 1" 0 "Creep Coast Curve 0" ;
VAL_ 647 DrvMntnMdCmnd 1 "true" 0 "false" ;
VAL_ 647 DrvHldMdCmnd 1 "true" 0 "false" ;
VAL_ 647 DrPTGrdBrkDsbMdCmd 1 "true" 0 "false" ;
VAL_ 647 DrvWntrMdCmd 1 "true" 0 "false" ;
VAL_ 647 DrvTwHaulMdCmd 1 "true" 0 "false" ;
VAL_ 647 DrvSprtMdCmd 1 "true" 0 "false" ;
VAL_ 647 DrvEconMdCmd 1 "true" 0 "false" ;
VAL_ 647 EngCntrlDtrmdTrfCRngV 1 "Invalid" 0 "Valid" ;
VAL_ 647 EngCntrlDtrmdTrfCRng 3 "Neutral" 2 "Unused and Reserved" 1 "Low" 0 "High" ;
VAL_ 647 EngCntrlUtldTrnCsRng 3 "Neutral" 2 "Unused and Reserved" 1 "Low" 0 "High" ;
VAL_ 647 EngCntrlUtldTrnCsRgIn 1 "true" 0 "false" ;
VAL_ 170 EngCommFlrRedPwrCm 1 "true" 0 "false" ;
VAL_ 170 CmndAxlTrqRespTyp 0 "Inactive" 1 "Pleasability Limit" 2 "Maximum Range" 3 "Automatic Actuator Selection" ;
VAL_ 1105 HybImpSnsDsbld 1 "true" 0 "false" ;
VAL_ 1105 JmpStrtReq 1 "true" 0 "false" ;
VAL_ 1105 HybVehHiVltInvDisRqd 1 "true" 0 "false" ;
VAL_ 1105 NESSRoSevSt 1 "true" 0 "false" ;
VAL_ 1105 NESSRiSiSevSt 1 "true" 0 "false" ;
VAL_ 1105 NESSReImpSevSt 1 "true" 0 "false" ;
VAL_ 1105 NESSLeSiSevSt 1 "true" 0 "false" ;
VAL_ 1105 NESSFrImpSt2SevSt 1 "true" 0 "false" ;
VAL_ 1105 NESSFrImpSt1SevSt 1 "true" 0 "false" ;
VAL_ 1105 NESSFrImpPreSevSt 1 "true" 0 "false" ;
VAL_ 872 ESBR_AutoBrkgRqTyp 3 "Unused and Reserved" 2 "Hold Deny Driver Release" 1 "Hold Allow Driver Release" 0 "Release" ;
VAL_ 872 ESBR_AutoBrkgRqd 1 "Braking Requested" 0 "Braking Not Requested " ;
VAL_ 1223 PropSysOffTmeV 1 "Invalid" 0 "Valid" ;
VAL_ 1223 PropSysOffTmeM 1 "Use Data" 0 "Don't Use Data" ;
VAL_ 405 EstWhlBrkPrsStat 3 "Invalid" 2 "Reduced Accuracy" 1 "Valid" 0 "Unknown" ;
VAL_ 311 PriCoPCmdMsgStatRed 3 "Dual Communication Failure" 2 "Secondary Communication Failed" 1 "Main Communication Failed" 0 "Communication Normal" ;
VAL_ 311 PriADSCmdMsgStatRed 3 "Dual Communication Failure" 2 "Secondary Communication Failed" 1 "Main Communication Failed" 0 "Communication Normal" ;
VAL_ 311 PriBrkSysArbStatRed 7 "Supervisor Override" 6 "Automatic Brake Apply 2" 5 "Automatic Brake Apply 1" 4 "CoPilot Override Request Honored" 3 "Redundant ADS Request Honored" 2 "Main ADS Request Honored" 1 "No Autonomous Request" 0 "Unknown" ;
VAL_ 311 PriBrkModSbSteRed 5 "Loss of Request" 4 "Full System" 3 "Failed Operational" 2 "Failed Degraded" 1 "Unable to Execute Requests" 0 "Faulted" ;
VAL_ 311 PriBrkSysStatRed 6 "Degraded Mode 5" 5 "Degraded Mode 4" 4 "Degraded Mode 3" 3 "Degraded Mode 2" 2 "Degraded Mode 1" 1 "Full Function" 0 "Unknown" ;
VAL_ 311 PriBrkRngLmtgStatRed 3 "Request Rate Limited" 2 "Req Value Limited Maximum" 1 "Req Value Limited Minimum" 0 "Request Not Limited" ;
VAL_ 311 ActrBrkFldFlwReqStat 2 "qTarget_EBRmaxPerformance" 1 "qTarget_EBR" 0 "qTarget_Off" ;
VAL_ 311 ABSAtv 1 "true" 0 "false" ;
VAL_ 311 EBCMhydctrlActRed 1 "true" 0 "false" ;
VAL_ 311 PriDrvIntvtnMdDetTORed 1 "true" 0 "false" ;
VAL_ 403 SpltMuCntrlV 1 "Invalid" 0 "Valid" ;
VAL_ 403 SpltMuCntrl 2 "Split Driver Side High" 1 "Split Driver Side Low" 0 "Inactive" ;
VAL_ 403 PriBrkModCapStat 1 "Active" 0 "Not Active" ;
VAL_ 403 PriEstSrfcMuTyp 3 "Invalid" 2 "Actual Surface Estimate" 1 "Minimum Surface Estimate" 0 "Unknown" ;
VAL_ 229 AutoRedAxlTrqStat 3 "Serial Data Failure" 2 "Data Invalid" 1 "Data Valid" 0 "Unknown" ;
VAL_ 229 AATPCS_PropRngLmtgStat 3 "Request Rate Limited" 2 "Request Value Limited Maximum" 1 "Request Value Limited Minimum" 0 "Request Not Limited" ;
VAL_ 229 AATPCS_PropSysStat 6 "Degraded Mode 5" 5 "Degraded Mode 4" 4 "Degraded Mode 3" 3 "Degraded Mode 2" 2 "Degraded Mode 1" 1 "Full Function" 0 "Initialize" ;
VAL_ 229 CpAxlTrqReqStat 3 "Serial Data Failure" 2 "Data Invalid" 1 "Data Valid" 0 "Unknown" ;
VAL_ 229 AutoPriAxlTrqStat 3 "Serial Data Failure" 2 "Data Invalid" 1 "Data Valid" 0 "Unknown" ;
VAL_ 229 AutoPropAxlTrqArbStat 3 "Lost Axle Arbitration" 2 "CoPilot Active" 1 "ADS Active" 0 "No ADS data" ;
VAL_ 229 AutoActAxleTrqV 1 "Invalid" 0 "Valid" ;
VAL_ 229 AutoPropSysDrInfcDtd 1 "true" 0 "false" ;
VAL_ 190 TrnsAuxPmpAct 1 "true" 0 "false" ;
VAL_ 190 PSBPI_PTSnBrkPdlPsV 1 "Invalid" 0 "Valid" ;
VAL_ 288 VehOdoV 1 "Invalid" 0 "Valid" ;
VAL_ 454 APAAxlTrqRdctnAct 1 "true" 0 "false" ;
VAL_ 454 CSPATR_TrqIntrvnTyp 3 "Minimum and Maximum Limit" 2 "Minimum Limit" 1 "Maximum Limit" 0 "No Intervention" ;
VAL_ 454 CSPATR_TrqRqTyp 0 "Absolute Torque Request" ;
VAL_ 454 ChsSysAxlTqRqRspTyp 4 "Braking Torque Request" 3 "Automatic Actuator Selection" 2 "Maximum Range Request" 1 "Pleasability Limited Request" 0 "Inactive" ;
VAL_ 209 ChsBrkPdlPsERltdV 1 "Invalid" 0 "Valid" ;
VAL_ 348 SecCoPCmdMsgStat 3 "Dual Communication Failure" 2 "Secondary Communication Failed" 1 "Main Communication Failed" 0 "Communication Normal" ;
VAL_ 348 SecBrkSysArbStat 7 "Supervisor Override" 6 "Automatic Brake Apply 2" 5 "Automatic Brake Apply 1" 4 "CoPilot Override Request Honored" 3 "Redundant ADS Request Honored" 2 "Main ADS Request Honored" 1 "No Autonomous Request" 0 "Unknown" ;
VAL_ 348 SecADSCmdMsgStat 3 "Dual Communication Failure" 2 "Secondary Communication Failed" 1 "Main Communication Failed" 0 "Communication Normal" ;
VAL_ 348 StrkOtptRodTgtQlfr 2 "Faulted" 1 "Normal" 0 "Unknown" ;
VAL_ 348 StrkOtptRodActlQlfr 2 "Faulted" 1 "Normal" 0 "Unknown" ;
VAL_ 348 SecBrkModSbSte 5 "Loss of Request" 4 "Full System" 3 "Failed Operational" 2 "Failed Degraded" 1 "Unable to Execute Requests" 0 "Faulted" ;
VAL_ 348 SecBrkSysStat 6 "Degraded Mode 5" 5 "Degraded Mode 4" 4 "Degraded Mode 3" 3 "Degraded Mode 2" 2 "Degraded Mode 1" 1 "Full Function" 0 "Unknown" ;
VAL_ 348 SecBrkRngLmtgStat 3 "Request Rate Limited" 2 "Req Value Limited Maximum" 1 "Req Value Limited Minimum" 0 "Request Not Limited" ;
VAL_ 348 SecDrvIntvtnMdDetTO 1 "true" 0 "false" ;
VAL_ 197 WRSLNDWhlRotStRst 1 "true" 0 "false" ;
VAL_ 197 WRSLNDWhlDistVal 1 "Invalid" 0 "Valid" ;
VAL_ 197 WRSRNDWhlRotStRst 1 "true" 0 "false" ;
VAL_ 197 WRSRNDWhlDistVal 1 "Invalid" 0 "Valid" ;
VAL_ 500 EnhDrvMdSwChUseAct 1 "true" 0 "false" ;
VAL_ 500 EnhDrvSelMdSwStat 0 "No Activation" 1 "Increment" 2 "Decrement" 3 "Faulted" ;
VAL_ 500 DrvSelMd8Stat 1 "Active" 0 "Inactive" ;
VAL_ 500 DrvSelMd8ReqDnd 1 "true" 0 "false" ;
VAL_ 500 DrvSelMd7Stat 1 "Active" 0 "Inactive" ;
VAL_ 500 DrvSelMd7ReqDnd 1 "true" 0 "false" ;
VAL_ 500 DrvSelMd6Stat 1 "Active" 0 "Inactive" ;
VAL_ 500 DrvSelMd6ReqDnd 1 "true" 0 "false" ;
VAL_ 500 DrvSelMd5Stat 1 "Active" 0 "Inactive" ;
VAL_ 500 DrvSelMd5ReqDnd 1 "true" 0 "false" ;
VAL_ 500 DrvSelMd4Stat 1 "Active" 0 "Inactive" ;
VAL_ 500 DrvSelMd4ReqDnd 1 "true" 0 "false" ;
VAL_ 500 DrvSelMd3Stat 1 "Active" 0 "Inactive" ;
VAL_ 500 DrvSelMd3ReqDnd 1 "true" 0 "false" ;
VAL_ 500 DrvSelMd2Stat 1 "Active" 0 "Inactive" ;
VAL_ 500 DrvSelMd2ReqDnd 1 "true" 0 "false" ;
VAL_ 500 DSMSS_DrvSelMd0Pn 1 "true" 0 "false" ;
VAL_ 500 DSMSS_DrvSelMd8Pn 1 "true" 0 "false" ;
VAL_ 500 DSMSS_DrvSelMd7Pn 1 "true" 0 "false" ;
VAL_ 500 DSMSS_DrvSelMd6Pn 1 "true" 0 "false" ;
VAL_ 500 DSMSS_DrvSelMd5Pn 1 "true" 0 "false" ;
VAL_ 500 DSMSS_DrvSelMd4Pn 1 "true" 0 "false" ;
VAL_ 500 DSMSS_DrvSelMd3Pn 1 "true" 0 "false" ;
VAL_ 500 DSMSS_DrvSelMd2Pn 1 "true" 0 "false" ;
VAL_ 500 DSMSS_DrvSelMd1Pn 1 "true" 0 "false" ;
VAL_ 500 DSMSS_DrvSelMd8Un 1 "true" 0 "false" ;
VAL_ 500 DSMSS_DrvSelMd7Un 1 "true" 0 "false" ;
VAL_ 500 DSMSS_DrvSelMd6Un 1 "true" 0 "false" ;
VAL_ 500 DSMSS_DrvSelMd5Un 1 "true" 0 "false" ;
VAL_ 500 DSMSS_DrvSelMd4Un 1 "true" 0 "false" ;
VAL_ 500 DSMSS_DrvSelMd3Un 1 "true" 0 "false" ;
VAL_ 500 DSMSS_DrvSelMd2Un 1 "true" 0 "false" ;
VAL_ 500 DSMSS_DrvSelMd1Un 1 "true" 0 "false" ;
VAL_ 500 DrvSelMd1ReqDnd 1 "true" 0 "false" ;
VAL_ 500 DrvSelMd1Stat 1 "Active" 0 "Inactive" ;
VAL_ 352 ShfFrmPrkAlwd 1 "true" 0 "false" ;
VAL_ 352 AVHSwtchStats 1 "Active" 0 "Not Active" ;
VAL_ 352 TeenDrvAct 1 "true" 0 "false" ;
VAL_ 352 LrnEnvIdSt 1 "Info_valid" 0 "No_info" ;
VAL_ 352 ImoIdSt 1 "Info valid" 0 "No info" ;
VAL_ 554 PrtdEPBSwStat 3 "Active" 2 "Apply" 1 "Release" 0 "Not Active" ;
VAL_ 554 ElecPrkBrkAvailStat 7 "Unused and Reserved 3" 6 "Unused and Reserved 2" 5 "Unused and Reserved 1" 4 "Unavailable, Failed other" 3 "Unavailable, Failed Released" 2 "Unavailable, Failed Applied" 1 "Available, Not Failed" 0 "Unavailable, Not Failed" ;
VAL_ 554 ElecPrkBrkApplStat 3 "Park Brake Application in Progress" 2 "Park brake Released" 1 "Park Brake Applied" 0 "Unknown" ;
VAL_ 566 RdHVBatHtrCntctrStat 0 "Open" 1 "Unused and Reserved" 2 "Closed" ;
VAL_ 566 ChrgSysShftPrkReq 1 "true" 0 "false" ;
VAL_ 566 ChrgSysAudblIndRq 7 "Unused and Reserved3" 6 "Unused and Reserved2" 5 "Unused and Reserved1" 4 "Sequence 4" 3 "Sequence 3" 2 "Sequence 2" 1 "Sequence 1" 0 "Inactive" ;
VAL_ 566 HVBatChrgCrdAlrtReq 0 "None" 1 "Pedestrian" 2 "Theft" ;
VAL_ 566 RdHVBatLwParMdReq 1 "true" 0 "false" ;
VAL_ 566 RdHVBtClOVFFTstRq 1 "true" 0 "false" ;
VAL_ 566 ClimCtrlHVDvcShtdwnCmd 1 "true" 0 "false" ;
VAL_ 566 VICMHVEnMgCmEnTrS 0 "Inactive" 1 "Active" ;
VAL_ 566 ChrgSysPrkBrkAnmsBrkReq 1 "true" 0 "false" ;
VAL_ 566 HybVehHiVltSysDisbld_236 1 "true" 0 "false" ;
VAL_ 566 RHVBCCS_ACChrgrCntCmd 1 "true" 0 "false" ;
VAL_ 566 RHVBCCS_InvtrCntCmd 1 "true" 0 "false" ;
VAL_ 566 RHVBCCS_InvtrCaptrChrgAct 1 "true" 0 "false" ;
VAL_ 566 RHVBCCS_DCChrgrCntCmd 1 "true" 0 "false" ;
VAL_ 566 RdDCChrgCntctrStat 0 "Open" 1 "Precharge" 2 "Close" ;
VAL_ 566 RdHVCntctrShdwnCmd 4 "Normal Shutdown" 3 "Emergency Crash Shutdown" 2 "Controlled Shutdown" 1 "Emergency Shutdown" 0 "None" ;
VAL_ 1017 ACRfHiSdFldPrsV 1 "Invalid" 0 "Valid" ;
VAL_ 1017 GenStptDtCycPtOvrAct 1 "true" 0 "false" ;
VAL_ 1017 VehTopSpdLmtMdAct 1 "true" 0 "false" ;
VAL_ 1017 GenFldDutCycV 1 "Invalid" 0 "Valid" ;
VAL_ 1017 GenFld 1 "true" 0 "false" ;
VAL_ 1017 FlInjRlCtRstOcc 1 "true" 0 "false" ;
VAL_ 1017 EngSpdLmtnMdAct 1 "true" 0 "false" ;
VAL_ 401 SecBrkModCapStat 1 "Active" 0 "Not Active" ;
VAL_ 401 SecEstSrfcMuTyp 3 "Invalid" 2 "Actual Surface Estimate" 1 "Minimum Surface Estimate" 0 "Unknown" ;
VAL_ 401 SecEstSrfcMuCapV 1 "Invalid" 0 "Valid" ;
VAL_ 320 Ky_IdDevPrgmAuthReq 1 "true" 0 "false" ;
VAL_ 320 AutoBmSlctAllwd 1 "true" 0 "false" ;
VAL_ 320 BrkLtsAtv 1 "true" 0 "false" ;
VAL_ 320 TrnSwAct 2 "Right" 1 "Left" 0 "No Activation" ;
VAL_ 320 RrFogLmpsAct 1 "true" 0 "false" ;
VAL_ 320 OtsdAmbtLtLvlStatV 1 "Invalid" 0 "Valid" ;
VAL_ 320 OtsdAmbtLtLvlStat 2 "Day" 1 "Night" 0 "Unknown" ;
VAL_ 320 MainLghtSw 3 "HEADLAMP" 2 "PARKLAMP" 1 "OFF" 0 "AUTO" ;
VAL_ 320 LowBmAct 1 "true" 0 "false" ;
VAL_ 320 HighBmAct 1 "true" 0 "false" ;
VAL_ 320 HdlmpBmSelectStat 2 "High Beams" 1 "Low Beams" 0 "Unknown" ;
VAL_ 320 FlToPsSwAtv 1 "true" 0 "false" ;
VAL_ 320 AdvFrntLghtSysEnbld 1 "true" 0 "false" ;
VAL_ 320 FrFogLmpsAct 1 "true" 0 "false" ;
VAL_ 320 AutLghtCtrl 1 "true" 0 "false" ;
SIG_GROUP_ 1105 NoEvSevSt 1 : NESSRoSevSt NESSRiSiSevSt NESSReImpSevSt NESSLeSiSevSt NESSFrImpSt2SevSt NESSFrImpSt1SevSt NESSFrImpPreSevSt;
SIG_GROUP_ 872 ElcShftBrkgRq 1 : ESBR_AutoBrkgRqTyp ESBR_AutoBrkgRqd;
SIG_GROUP_ 229 AutoAxlTrqPropCapStat 1 : AATPCS_PropRngLmtgStat AATPCS_PropSysStat;
SIG_GROUP_ 190 PTSnsdBrkPdlInf 1 : PSBPI_PTSnBrkPdlPsV PSBPI_PTSnBrkPdlPs;
SIG_GROUP_ 454 ChsSysPrdAxlTqRq 1 : CSPATR_TrqIntrvnTyp CSPATR_PrdTrqRqVal CSPATR_TrqRqTyp;
SIG_GROUP_ 197 WhlRotStatLftNDrvn 1 : WRSLNDWhlDisTpRC WRSLNDWhlRotStRst WRSLNDWhlDistVal WRSLNDWhlDistTstm WRSLNDWhlDistPCntr WRSLNDSeqNum;
SIG_GROUP_ 197 WhlRotStatRghtNDrvn 1 : WRSRNDWhlRotStRst WRSRNDWhlDisTpRC WRSRNDWhlDistVal WRSRNDWhlDistTstm WRSRNDWhlDistPCntr WRSRNDSeqNum;
SIG_GROUP_ 500 DrvSelMdSelnStat 1 : DSMSS_DrvSelMd0Pn DSMSS_DrvSelMd8Pn DSMSS_DrvSelMd7Pn DSMSS_DrvSelMd6Pn DSMSS_DrvSelMd5Pn DSMSS_DrvSelMd4Pn DSMSS_DrvSelMd3Pn DSMSS_DrvSelMd2Pn DSMSS_DrvSelMd1Pn DSMSS_DrvSelMd8Un DSMSS_DrvSelMd7Un DSMSS_DrvSelMd6Un DSMSS_DrvSelMd5Un DSMSS_DrvSelMd4Un DSMSS_DrvSelMd3Un DSMSS_DrvSelMd2Un DSMSS_DrvSelMd1Un;
SIG_GROUP_ 566 RHVBCCS 1 : RHVBCCS_ACChrgrCntCmd RHVBCCS_InvtrCntCmd RHVBCCS_InvtrCaptrChrgAct RHVBCCS_DCChrgrCntCmd;
